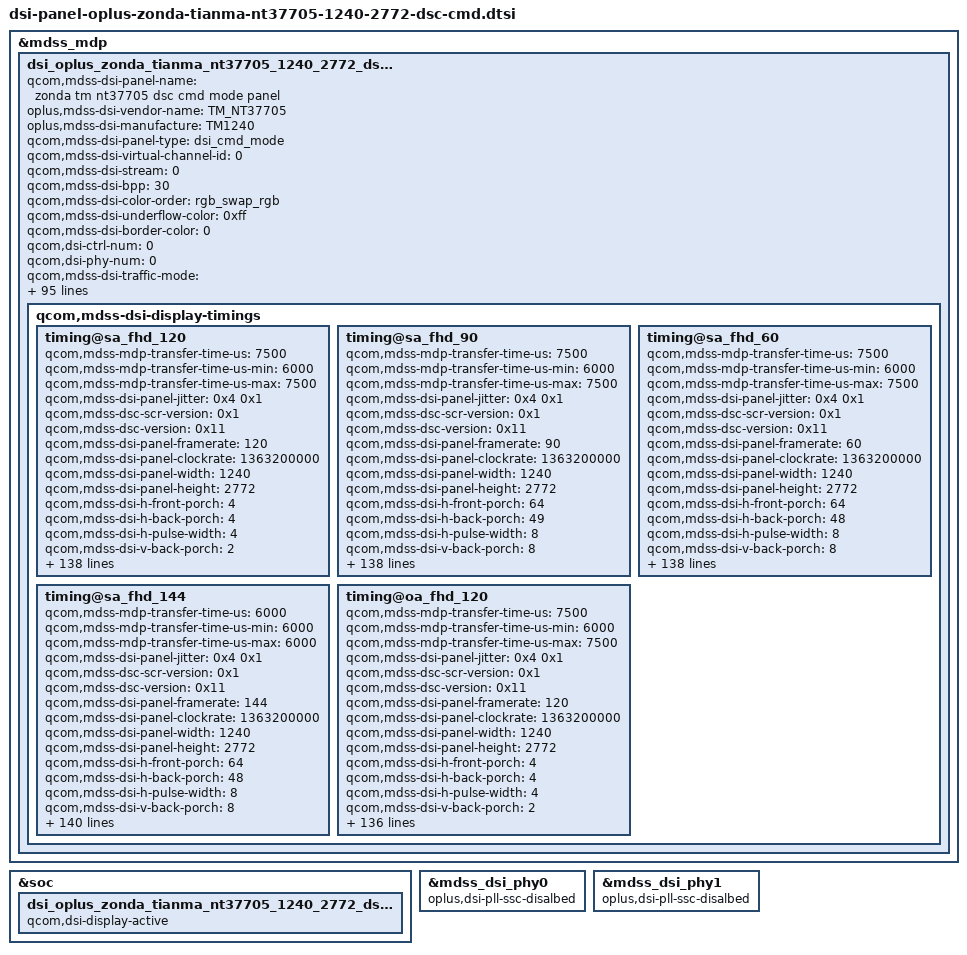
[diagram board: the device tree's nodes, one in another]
&mdss_mdp {
	dsi_oplus_zonda_tianma_nt37705_1240_2772_dsc_cmd: qcom,mdss_dsi_oplus_zonda_tianma_nt37705_1240_2772_dsc_cmd {
		qcom,mdss-dsi-panel-name = "zonda tm nt37705 dsc cmd mode panel";
		oplus,mdss-dsi-vendor-name = "TM_NT37705";
		oplus,mdss-dsi-manufacture = "TM1240";
		qcom,mdss-dsi-panel-type = "dsi_cmd_mode";
		qcom,mdss-dsi-virtual-channel-id = <0>;
		qcom,mdss-dsi-stream = <0>;
		qcom,mdss-dsi-bpp = <30>;
		qcom,mdss-dsi-color-order = "rgb_swap_rgb";
		qcom,mdss-dsi-underflow-color = <0xff>;
		qcom,mdss-dsi-border-color = <0>;
		qcom,dsi-ctrl-num = <0>;
		qcom,dsi-phy-num = <0>;
		qcom,mdss-dsi-traffic-mode = "non_burst_sync_event";
		qcom,mdss-dsi-lane-map = "lane_map_0123";
		qcom,mdss-dsi-bllp-eof-power-mode;
		qcom,mdss-dsi-bllp-power-mode;
		qcom,mdss-dsi-lane-0-state;
		qcom,mdss-dsi-lane-1-state;
		qcom,mdss-dsi-lane-2-state;
		qcom,mdss-dsi-lane-3-state;
		qcom,mdss-dsi-dma-trigger = "trigger_sw";
		qcom,mdss-dsi-mdp-trigger = "none";
		qcom,mdss-dsi-reset-sequence = <1 2>, <0 2>, <1 20>;

		qcom,mdss-dsi-te-pin-select = <1>;
		qcom,mdss-dsi-te-dcs-command = <1>;
		qcom,mdss-dsi-te-check-enable;
		qcom,mdss-dsi-te-using-te-pin;
		qcom,mdss-dsi-lp11-init;
		qcom,mdss-dsi-wr-mem-start = <0x2c>;
		qcom,mdss-dsi-wr-mem-continue = <0x3c>;
		/* HDR Setting */
		qcom,mdss-dsi-panel-hdr-enabled;
		qcom,mdss-dsi-panel-hdr-color-primaries = <15635 16450 34000 16000 13250 34500 7500 3000>;
		qcom,mdss-dsi-panel-peak-brightness = <5400000>;
		qcom,mdss-dsi-panel-blackness-level = <2000>;
		qcom,mdss-pan-physical-width-dimension = <70>;
		qcom,mdss-pan-physical-height-dimension = <156>;

		qcom,esd-check-enabled;
		//oplus,esd-check-flag-enabled;
		qcom,mdss-dsi-panel-status-check-mode = "reg_read";
		qcom,mdss-dsi-panel-status-command = [
				06 01 00 01 05 00 02 0A 00
			];
		qcom,mdss-dsi-panel-status-command-state = "dsi_lp_mode";
		qcom,mdss-dsi-panel-status-value = <0x9C>;
		qcom,mdss-dsi-panel-status-read-length = <1>;

		qcom,dynamic-mode-switch-enabled;
		qcom,dynamic-mode-switch-type = "dynamic-resolution-switch-immediate";
		qcom,mdss-dsi-display-timings {
			timing@sa_fhd_120{
				qcom,mdss-mdp-transfer-time-us = <7500>;
				qcom,mdss-mdp-transfer-time-us-min = <6000>;
				qcom,mdss-mdp-transfer-time-us-max = <7500>;
				qcom,mdss-dsi-panel-jitter = <0x4 0x1>;
				qcom,mdss-dsc-scr-version = <0x1>;
				qcom,mdss-dsc-version = <0x11>;
				qcom,mdss-dsi-panel-framerate = <120>;
				qcom,mdss-dsi-panel-clockrate = <1363200000>;
				qcom,mdss-dsi-panel-width = <1240>;
				qcom,mdss-dsi-panel-height = <2772>;

				qcom,mdss-dsi-h-front-porch = <4>;
				qcom,mdss-dsi-h-back-porch = <4>;
				qcom,mdss-dsi-h-pulse-width = <4>;
				qcom,mdss-dsi-v-back-porch = <2>;
				qcom,mdss-dsi-v-front-porch = <2>;
				qcom,mdss-dsi-v-pulse-width = <2>;
				qcom,mdss-dsi-h-sync-pulse = <0>;

				qcom,mdss-dsi-h-left-border = <0>;
				qcom,mdss-dsi-h-right-border = <0>;
				qcom,mdss-dsi-v-top-border = <0>;
				qcom,mdss-dsi-v-bottom-border = <0>;

				/* Apollo vsync config, need to measure TE signal */
				//oplus,apollo-panel-vsync-width = <13000>;
				//oplus,apollo-panel-vsync-period = <16600>;

				/* standard adfr */
				qcom,mdss-dsi-h-sync-skew = <0>;
				oplus,adfr-min-fps-mapping-table = <120 60>;

				qcom,mdss-dsi-panel-vsync-source = <1>;
				qcom,mdss-dsi-qsync-min-fps-0 = <1314>;
				oplus,fod-on-vblank = <0>;
				oplus,fod-off-vblank = <0>;
				oplus,ofp-need-to-filter-backlight-dim-icon;
				qcom,mdss-dsi-bl-demua1-command = [
					/* 51hex > 0x644 */
					39 00 00 50 00 00 06 F0 55 AA 52 08 04
					39 00 00 50 00 00 02 6F 02
					39 00 00 50 00 00 03 EC 01 03
					39 00 00 50 00 00 02 6F A5
					39 00 00 10 00 00 07 EC 01 01 01 03 03 03
				];
				qcom,mdss-dsi-bl-demua2-command = [
					/* 0x644>51hex>=0x530 */
					39 00 00 50 00 00 06 F0 55 AA 52 08 04
					39 00 00 50 00 00 02 6F 02
					39 00 00 50 00 00 03 EC 03 0B
					39 00 00 50 00 00 02 6F A5
					39 00 00 10 00 00 07 EC 03 03 03 0B 0B 0B
				];
				qcom,mdss-dsi-bl-demua3-command = [
					/* 0x530>51hex>=0x33A */
					39 00 00 50 00 00 06 F0 55 AA 52 08 04
					39 00 00 50 00 00 02 6F 02
					39 00 00 50 00 00 03 EC 10 18
					39 00 00 50 00 00 02 6F A5
					39 00 00 10 00 00 07 EC 10 10 10 18 18 18
				];
				qcom,mdss-dsi-bl-demua4-command = [
					/* 0x339>51hex>=0x25C */
					39 00 00 50 00 00 06 F0 55 AA 52 08 04
					39 00 00 50 00 00 02 6F 02
					39 00 00 50 00 00 03 EC 15 1D
					39 00 00 50 00 00 02 6F A5
					39 00 00 10 00 00 07 EC 15 15 15 1D 1D 1D
				];
				qcom,mdss-dsi-bl-demua5-command = [
					/* 0x25C>51hex>=0x196 */
					39 00 00 50 00 00 06 F0 55 AA 52 08 04
					39 00 00 50 00 00 02 6F 02
					39 00 00 50 00 00 03 EC 15 2D
					39 00 00 50 00 00 02 6F A5
					39 00 00 10 00 00 07 EC 15 15 15 2D 2D 2D
				];
				qcom,mdss-dsi-bl-demua6-command = [
					/* 0x196>51hex>=0x008 */
					39 00 00 50 00 00 06 F0 55 AA 52 08 04
					39 00 00 50 00 00 02 6F 02
					39 00 00 50 00 00 03 EC 15 4D
					39 00 00 50 00 00 02 6F A5
					39 00 00 10 00 00 07 EC 15 15 15 4D 4D 4D
				];
				qcom,mdss-dsi-skipframe-dbv-command = [
					39 00 00 40 00 00 06 F0 55 AA 52 08 01
					39 00 00 40 00 00 02 6F 02
					39 00 00 40 00 00 11 E5 00 00 00 00 00 00 00 00 00 00 00 00 00 00 00 00
					39 00 00 40 00 00 02 6F 24
					39 00 00 40 00 00 0D E5 00 00 00 00 00 00 00 00 00 00 00 00
					39 00 00 40 00 00 02 6F 46
					39 00 00 40 00 00 0D E5 00 00 00 00 00 00 00 00 00 00 00 00
					39 00 00 40 00 00 02 6F 03
					39 00 00 40 00 00 19 C6 1B 1B 24 23 23 23 23 23 23 1D 1D 25 23 23 23 23 23 23 1B 1B 24 23 23 23
					39 00 00 40 00 00 02 E5 B2
					39 00 00 40 00 00 02 6F 22
					39 00 00 40 00 00 02 E5 B2
					39 00 00 40 00 00 02 6F 44
					39 00 00 40 00 00 02 E5 B2
					39 00 00 40 00 00 06 F0 55 AA 52 08 05
					39 00 00 40 00 00 02 6F 12
					39 00 00 00 00 00 05 EC 00 00 00 00
					];
				qcom,mdss-dsi-timing-switch-command = [
					/* switch */
					39 00 00 40 00 00 06 F0 55 AA 52 08 00
					39 00 00 00 0C 00 02 2F 00
					39 00 00 40 00 00 02 BE 47
					39 00 00 40 00 00 02 6F A8
					39 00 00 40 00 00 03 BA 00 00
					39 00 00 40 00 00 02 6F B0
					39 00 00 40 00 00 05 BA 00 00 00 00
					39 00 00 40 00 00 02 2F 30
					39 00 00 40 00 00 02 6D 00
					39 00 00 00 00 00 05 35 00 00 00 00
					];
				qcom,mdss-dsi-on-command=[
					/* Optimize edge green */
					39 00 00 40 00 00 06 F0 55 AA 52 08 07
					39 00 00 40 00 00 0E B4 C0 80 80 80 80 50 80 80 80 80 80 50 80
					/* Vsync Hsync output */
					39 00 00 40 00 00 06 F0 55 AA 52 08 00
					39 00 00 40 00 00 02 6F 02
					39 00 00 00 00 00 03 BE 49 4C
					/* AVDD=7.9 */
					39 00 00 40 00 00 06 F0 55 AA 52 08 00
					39 00 00 40 00 00 02 6F 07
					39 00 00 40 00 00 02 B5 4E
					/* HBM L0 glows green */
					39 00 00 40 00 00 02 B5 80
					39 00 00 40 00 00 02 6F 2C
					39 00 00 00 00 00 02 B5 03
					39 00 00 40 00 00 05 FF AA 55 A5 81
					39 00 00 40 00 00 02 6F 19
					39 00 00 40 00 00 02 FB 00
					39 00 00 40 00 00 02 6F 05
					39 00 00 40 00 00 02 FE 34
					39 00 00 40 00 00 05 FF AA 55 A5 80
					39 00 00 40 00 00 02 6F 1A
					39 00 00 40 00 00 02 F4 55
					39 00 00 40 00 00 05 FF AA 55 A5 83
					39 00 00 40 00 00 02 6F 12
					39 00 00 40 00 00 02 FE 41
					39 00 00 40 00 00 02 5F 00
					39 00 00 40 00 00 02 26 00
					39 00 00 40 00 00 02 26 00
					39 00 00 40 00 00 02 17 10
					39 00 00 40 00 00 05 2A 00 00 04 D7
					39 00 00 00 00 00 05 2B 00 00 0A D3
					/* Fre 120Hz */
					39 00 00 00 00 00 02 2F 00
					/* TE ON */
					39 00 00 40 00 00 02 35 00
					39 00 00 00 00 00 03 44 00 00
					/* Nor 51 */
					39 00 00 40 00 00 03 51 00 00
					39 00 00 00 00 00 02 6F 04
					/* AOD 51 */
					39 00 00 40 00 00 03 51 00 00
					39 00 00 40 00 00 02 53 20
					39 00 00 00 00 00 03 90 03 03
					/* 10bit DSC */
					39 00 00 40 00 00 13 91 AB 28 00 0C F2 00 02 85 01 0F 00 08 0A E9 07 5F 10 F0
					39 00 00 40 00 00 05 FF AA 55 A5 81
					39 00 00 40 00 00 02 6F 24
					39 00 00 40 00 00 15 FB 00 03 04 55 77 77 77 99 9D 00 00 06 88 9A BB BC DE EF F0 11
					39 00 00 40 00 00 05 FF AA 55 A5 81
					39 00 00 40 00 00 02 6F 0E
					39 00 00 40 00 00 02 F5 00
					39 00 00 40 00 00 05 FF AA 55 A5 80
					39 00 00 40 00 00 02 6F 0F
					39 00 00 40 00 00 02 FC 00
					39 00 00 40 00 00 02 6F 09
					39 00 00 40 00 00 03 FC FC F0
					39 00 00 40 00 00 05 FF AA 55 A5 80
					39 00 00 40 00 00 02 6F 0A
					39 00 00 40 00 00 04 F6 70 70 70
					39 00 00 40 00 00 02 6F 0E
					39 00 00 00 00 00 02 F6 60
					/* OSC start */
					39 00 00 40 00 00 05 FF AA 55 A5 80
					39 00 00 40 00 00 02 6F 11
					/* OSC2 145Mhz */
					39 00 00 40 00 00 03 F8 01 8E
					39 00 00 40 00 00 02 6F 2D
					/* OSC1 121.9Mhz */
					39 00 00 40 00 00 03 F8 00 FC
					39 00 00 40 00 00 02 6F 01
					39 00 00 40 00 00 02 1F 06
					39 00 00 40 00 00 05 FF AA 55 A5 81
					39 00 00 40 00 00 02 6F 1E
					39 00 00 00 00 00 02 FB 0F
					/* OSC end */
					39 00 00 40 00 00 05 FF AA 55 A5 83
					39 00 00 40 00 00 02 6F 12
					39 00 00 40 00 00 02 FE 41
					39 00 00 40 00 00 05 FF AA 55 A5 80
					39 00 00 40 00 00 02 6F 19
					39 00 00 40 00 00 02 F2 00
					39 00 00 40 00 00 05 FF AA 55 A5 81
					39 00 00 40 00 00 02 6F 02
					39 00 00 40 00 00 02 F9 04
					39 00 00 40 00 00 02 5A 00
					/* AOD remove black frame */
					39 00 00 00 00 00 06 F0 55 AA 52 08 01
					39 00 00 00 00 00 06 D2 00 00 00 00 15
					15 00 00 00 00 00 02 6F 05
					39 00 00 00 00 00 04 D2 01 00 00
					15 00 00 00 00 00 02 6F 0E
					39 00 00 00 00 00 06 D2 02 00 10 05 88
					39 00 00 00 00 00 0B E4 80 00 00 00 00 00 00 00 00 33
					15 00 00 00 00 00 02 6F 0A
					39 00 00 00 00 00 07 E4 80 00 00 10 00 53
					/* AOD off splash */
					39 00 00 40 00 00 06 F0 55 AA 52 08 01
					39 00 00 40 00 00 02 6F 0E
					39 00 00 00 00 00 06 D2 02 00 10 05 82
					/* OSC Tracking */
					39 00 00 40 00 00 06 F0 55 AA 52 08 01
					39 00 00 00 00 00 2A C3 DD 06 22 15 F9 00 06 20 15 FF 00 03 E7 16 06 2B 1D 03 E7 16 06 2B 1D 03 E7 16 06 2B 1D 03 E7 16 06 2B 1D 03 E7 16 06 2B 1D
					/* 11H sleep out */
					39 00 00 00 78 00 02 11 00
					39 00 00 40 00 00 06 F0 55 AA 52 08 00
					39 00 00 00 09 00 02 2F 00
					39 00 00 40 00 00 02 BE 47
					39 00 00 40 00 00 02 6F A8
					39 00 00 40 00 00 03 BA 00 00
					39 00 00 40 00 00 02 6F B0
					39 00 00 40 00 00 05 BA 00 00 00 00
					39 00 00 40 00 00 02 2F 30
					39 00 00 40 00 00 02 6D 00
					39 00 00 00 00 00 05 35 00 00 00 00
					05 00 00 00 00 00 01 29
				];

				qcom,mdss-dsi-panel-info-switch-page-command = [
					/*read panel info switch page 01*/
					39 00 00 00 00 00 06 F0 55 AA 52 08 01
				];
				qcom,mdss-dsi-default-switch-page-command = [
					/*switch default page*/
					39 00 00 00 00 00 06 F0 55 AA 52 08 00
				];

				qcom,mdss-dsi-adfr-auto-on-command = [
					/* SDC Auto On */
				];
				qcom,mdss-dsi-adfr-auto-off-command = [
					/* SDC Auto Off */
				];
				qcom,mdss-dsi-adfr-min-fps-0-command = [
					15 00 00 40 00 00 02 2F 00
					15 00 00 40 00 00 02 2F 30
					15 00 00 00 00 00 02 6D 00
				];
				qcom,mdss-dsi-adfr-min-fps-1-command = [
					15 00 00 40 00 00 02 2F 00
					15 00 00 40 00 00 02 2F 30
					15 00 00 00 00 00 02 6D 01
				];

				qcom,mdss-dsi-post-on-backlight = [
					/* Display On */
					05 00 00 00 00 00 01 29
				];
				qcom,mdss-dsi-off-command=[
					05 00 00 00 0A 00 01 28
					05 00 00 00 78 00 01 10
				];
				qcom,mdss-dsi-lp1-command = [
					/* AOD Mode ON Setting */
					39 00 00 00 00 00 06 F0 55 AA 52 08 00
					15 00 00 00 00 00 02 6F 0C
					39 00 00 00 00 00 03 B5 50 4B
					39 00 00 00 00 00 05 35 00 00 00 00
					39 00 00 00 00 00 03 44 00 00
					15 00 00 00 10 00 02 2F 00
					05 00 00 00 00 00 01 39
					15 00 00 00 00 00 02 65 01
					15 00 00 00 00 00 02 6F 04
					39 00 00 00 00 00 03 51 02 FF
				];
				qcom,mdss-dsi-nolp-command = [
					/* AOD OFF */
					39 00 00 00 00 00 06 F0 55 AA 52 08 00
					15 00 00 00 00 00 02 6F 0C
					39 00 00 00 00 00 03 B5 4F 4B
					15 00 00 00 00 00 02 65 00
					05 00 00 00 00 00 01 38
					15 00 00 00 00 00 02 2F 30
					15 00 00 00 00 00 02 6D 00
					39 00 00 00 00 00 05 35 00 00 00 00
					39 00 00 00 00 00 03 44 00 00
					39 00 00 00 28 00 03 51 00 00
				];
				qcom,mdss-dsi-hbm-off-command = [
					//39 00 00 00 00 00 03 51 0D BB
				];
				qcom,mdss-dsi-hbm-on-command = [
					39 00 00 40 00 00 06 F0 55 AA 52 08 01
					39 00 00 40 00 00 02 6F 02
					39 00 00 40 00 00 11 E5 00 00 00 00 20 20 20 00 28 28 28 00 30 30 30 00
					39 00 00 40 00 00 02 6F 24
					39 00 00 40 00 00 0D E5 00 00 00 00 20 20 20 00 28 28 28 00
					39 00 00 40 00 00 02 6F 46
					39 00 00 40 00 00 0D E5 00 00 00 00 20 20 20 00 28 28 28 00
					39 00 00 40 00 00 02 6F 03
					39 00 00 40 00 00 19 C6 37 37 37 23 23 23 23 23 23 37 37 37 23 23 23 23 23 23 37 37 37 23 23 23
					39 00 00 40 00 00 02 E5 B2
					39 00 00 40 00 00 02 6F 22
					39 00 00 40 00 00 02 E5 B2
					39 00 00 40 00 00 02 6F 44
					39 00 00 40 00 00 02 E5 B2
					39 00 00 40 00 00 06 F0 55 AA 52 08 05
					39 00 00 40 00 00 02 6F 12
					39 00 00 40 00 00 05 EC 00 00 00 00
					39 00 00 40 00 00 06 F0 55 AA 52 08 00
					39 00 00 40 00 00 02 6F 11
					39 00 00 40 00 00 04 B2 02 03 42
					39 00 00 40 00 00 2D B3 00 08 00 B4 00 B4 01 5F 01 5F 02 20 02 20 03 7C 03 7C 05 30 05 30 06 43 06 43 06 44 06 44 09 0B 09 0B 0D BB 0D BB 0F FF 0F FF 0F FF
					39 00 00 40 00 00 2F B4 00 00 00 80 00 96 00 96 00 C0 00 C0 01 26 01 26 02 8E 02 8E 05 8E 05 8E 08 26 08 26 09 40 09 40 09 40 09 40 09 40 09 40 09 40 09 40 09 40
					39 00 00 40 00 00 02 6F 2E
					39 00 00 40 00 00 2F B4 00 00 00 E2 00 FF 00 FF 01 3A 01 3A 01 CE 01 CE 03 AA 03 AA 07 9C 07 9C 0B 20 0B 20 0C 56 0C 56 0C 56 0C 56 0C 56 0C 56 0C 56 0C 56 0C 56
					39 00 00 40 00 00 02 6F 5C
					39 00 00 40 00 00 2F B4 00 00 00 78 00 8C 00 8C 00 B4 00 B4 01 26 01 26 02 8E 02 8E 05 8E 05 8E 08 26 08 26 09 40 09 40 09 40 09 40 09 40 09 40 09 40 09 40 09 40
					39 00 00 00 00 00 03 51 0F 00
				];
				qcom,mdss-dsi-hbm-on-onepulse-command = [
					39 00 00 40 00 00 06 F0 55 AA 52 08 01
					39 00 00 40 00 00 02 6F 02
					39 00 00 40 00 00 11 E5 00 00 00 00 00 00 00 00 00 00 00 00 00 00 00 00
					39 00 00 40 00 00 02 6F 24
					39 00 00 40 00 00 0D E5 00 00 00 00 20 20 20 00 28 28 28 00
					39 00 00 40 00 00 02 6F 46
					39 00 00 40 00 00 0D E5 00 00 00 00 20 20 20 00 28 28 28 00
					39 00 00 40 00 00 02 6F 03
					39 00 00 40 00 00 19 C6 1D 1D 1D 23 23 23 23 23 23 37 37 37 23 23 23 23 23 23 37 37 37 23 23 23
					39 00 00 40 00 00 02 E5 B2
					39 00 00 40 00 00 02 6F 22
					39 00 00 40 00 00 02 E5 B2
					39 00 00 40 00 00 02 6F 44
					39 00 00 40 00 00 02 E5 B2
					39 00 00 40 00 00 06 F0 55 AA 52 08 05
					39 00 00 40 00 00 02 6F 12
					39 00 00 40 00 00 05 EC 00 00 00 00
					39 00 00 40 00 00 06 F0 55 AA 52 08 00
					39 00 00 40 00 00 02 6F 11
					39 00 00 40 00 00 04 B2 00 00 40
					39 00 00 40 00 00 2D B3 00 08 00 B4 00 B4 01 5F 01 5F 02 20 02 20 03 7C 03 7C 05 30 05 30 06 43 06 43 06 44 06 44 09 0B 09 0B 0D BB 0D BB 0F FF 0F FF 0F FF
					39 00 00 40 00 00 2F B4 00 00 00 80 00 96 00 96 00 C0 00 C0 01 26 01 26 02 8E 02 8E 05 8E 05 8E 08 26 08 26 0A DE 0A DE 0A DE 0A DE 0A DE 0A DE 0A DE 0A DE 0A DE
					39 00 00 40 00 00 02 6F 2E
					39 00 00 40 00 00 2F B4 00 00 00 E2 00 FF 00 FF 01 3A 01 3A 01 CE 01 CE 03 AA 03 AA 07 9C 07 9C 0B 20 0B 20 0E 5B 0E 5B 0E 5B 0E 5B 0E 5B 0E 5B 0E 5B 0E 5B 0E 5B
					39 00 00 40 00 00 02 6F 5C
					39 00 00 40 00 00 2F B4 00 00 00 78 00 8C 00 8C 00 B4 00 B4 01 26 01 26 02 8E 02 8E 05 8E 05 8E 08 26 08 26 0A DE 0A DE 0A DE 0A DE 0A DE 0A DE 0A DE 0A DE 0A DE
					39 00 00 00 00 00 03 51 0F 00
				];
				qcom,mdss-dsi-aod-high-mode-command = [
					/* AOD 50nit */
					15 00 00 40 00 00 02 6F 04
					39 00 00 00 00 00 03 51 02 FF
				];
				qcom,mdss-dsi-aod-low-mode-command = [
					/* AOD 10nit */
					15 00 00 40 00 00 02 6F 04
					39 00 00 00 00 00 03 51 01 FF
				];
				qcom,mdss-dsi-temperature-compensation-command = [
					39 00 00 40 00 00 06 F0 55 AA 52 08 01
					39 00 00 40 00 00 02 6F 06
					39 00 00 40 00 00 05 E5 00 00 00 00
					39 00 00 40 00 00 02 6F 0A
					39 00 00 40 00 00 05 E5 00 00 00 00
					39 00 00 40 00 00 02 6F 0E
					39 00 00 40 00 00 05 E5 00 00 00 00
					39 00 00 40 00 00 02 6F 28
					39 00 00 40 00 00 05 E5 00 00 00 00
					39 00 00 40 00 00 02 6F 2C
					39 00 00 40 00 00 05 E5 00 00 00 00
					39 00 00 40 00 00 02 6F 4A
					39 00 00 40 00 00 05 E5 00 00 00 00
					39 00 00 40 00 00 02 6F 4E
					39 00 00 40 00 00 05 E5 00 00 00 00
					39 00 00 40 00 00 02 6F 52
					39 00 00 40 00 00 05 E5 00 00 00 00
					39 00 00 40 00 00 02 6F 03
					39 00 00 40 00 00 04 C6 00 00 00
					39 00 00 40 00 00 02 6F 0C
					39 00 00 40 00 00 04 C6 00 00 00
					39 00 00 40 00 00 02 6F 15
					39 00 00 40 00 00 04 C6 00 00 00
					39 00 00 40 00 00 06 F0 55 AA 52 08 05
					39 00 00 40 00 00 02 6F 12
					39 00 00 00 00 00 05 EC 00 00 00 00
				];
				/* origin 3 pulse */
				qcom,mdss-dsi-pwm-switch-high-command = [
					39 00 00 40 00 00 06 F0 55 AA 52 08 00
					39 00 00 40 00 00 02 6F 11
					39 00 00 40 00 00 04 B2 02 03 42
					39 00 00 40 00 00 2D B3 00 08 00 B4 00 B4 01 5F 01 5F 02 20 02 20 03 7C 03 7C 05 30 05 30 06 43 06 43 06 44 06 44 09 0B 09 0B 0D BB 0D BB 0F FF 0F FF 0F FF
					39 00 00 40 00 00 2F B4 00 00 00 80 00 96 00 96 00 C0 00 C0 01 26 01 26 02 8E 02 8E 05 8E 05 8E 08 26 08 26 09 40 09 40 09 40 09 40 09 40 09 40 09 40 09 40 09 40
					39 00 00 40 00 00 02 6F 2E
					39 00 00 40 00 00 2F B4 00 00 00 E2 00 FF 00 FF 01 3A 01 3A 01 CE 01 CE 03 AA 03 AA 07 9C 07 9C 0B 20 0B 20 0C 56 0C 56 0C 56 0C 56 0C 56 0C 56 0C 56 0C 56 0C 56
					39 00 00 40 00 00 02 6F 5C
					39 00 00 40 00 00 2F B4 00 00 00 78 00 8C 00 8C 00 B4 00 B4 01 26 01 26 02 8E 02 8E 05 8E 05 8E 08 26 08 26 09 40 09 40 09 40 09 40 09 40 09 40 09 40 09 40 09 40
					39 00 00 00 00 00 03 51 06 44
				];
				qcom,mdss-dsi-pwm-switch-low-command = [
					39 00 00 40 00 00 06 F0 55 AA 52 08 00
					39 00 00 40 00 00 02 6F 11
					39 00 00 40 00 00 04 B2 0F 17 4E
					39 00 00 40 00 00 2D B3 00 08 00 B4 00 B4 01 5F 01 5F 02 20 02 20 03 7C 03 7C 05 30 05 30 06 43 06 43 06 44 06 44 09 0B 09 0B 0D BB 0D BB 0F FF 0F FF 0F FF
					39 00 00 40 00 00 2F B4 00 00 00 80 00 96 00 96 00 C0 00 C0 01 26 01 26 02 8E 02 8E 05 8E 05 8E 08 26 08 26 09 40 09 40 09 40 09 40 09 40 09 40 09 40 09 40 09 40
					39 00 00 40 00 00 02 6F 2E
					39 00 00 40 00 00 2F B4 00 00 00 E2 00 FF 00 FF 01 3A 01 3A 01 CE 01 CE 03 AA 03 AA 07 9C 07 9C 0B 20 0B 20 0C 56 0C 56 0C 56 0C 56 0C 56 0C 56 0C 56 0C 56 0C 56
					39 00 00 40 00 00 02 6F 5C
					39 00 00 40 00 00 2F B4 00 00 00 78 00 8C 00 8C 00 B4 00 B4 01 26 01 26 02 8E 02 8E 05 8E 05 8E 08 26 08 26 09 40 09 40 09 40 09 40 09 40 09 40 09 40 09 40 09 40
					39 00 00 00 00 00 03 51 06 43
				];
				/* origin 3 pulse */
				qcom,mdss-dsi-timming-pwm-switch-high-command = [
					39 00 00 40 00 00 06 F0 55 AA 52 08 00
					39 00 00 40 00 00 02 6F 11
					39 00 00 40 00 00 04 B2 02 03 42
					39 00 00 40 00 00 2D B3 00 08 00 B4 00 B4 01 5F 01 5F 02 20 02 20 03 7C 03 7C 05 30 05 30 06 43 06 43 06 44 06 44 09 0B 09 0B 0D BB 0D BB 0F FF 0F FF 0F FF
					39 00 00 40 00 00 2F B4 00 00 00 80 00 96 00 96 00 C0 00 C0 01 26 01 26 02 8E 02 8E 05 8E 05 8E 08 26 08 26 09 40 09 40 09 40 09 40 09 40 09 40 09 40 09 40 09 40
					39 00 00 40 00 00 02 6F 2E
					39 00 00 40 00 00 2F B4 00 00 00 E2 00 FF 00 FF 01 3A 01 3A 01 CE 01 CE 03 AA 03 AA 07 9C 07 9C 0B 20 0B 20 0C 56 0C 56 0C 56 0C 56 0C 56 0C 56 0C 56 0C 56 0C 56
					39 00 00 40 00 00 02 6F 5C
					39 00 00 00 00 00 2F B4 00 00 00 78 00 8C 00 8C 00 B4 00 B4 01 26 01 26 02 8E 02 8E 05 8E 05 8E 08 26 08 26 09 40 09 40 09 40 09 40 09 40 09 40 09 40 09 40 09 40
				];
				qcom,mdss-dsi-timming-pwm-switch-low-command = [
					39 00 00 40 00 00 06 F0 55 AA 52 08 00
					39 00 00 40 00 00 02 6F 11
					39 00 00 40 00 00 04 B2 0F 17 4E
					39 00 00 40 00 00 2D B3 00 08 00 B4 00 B4 01 5F 01 5F 02 20 02 20 03 7C 03 7C 05 30 05 30 06 43 06 43 06 44 06 44 09 0B 09 0B 0D BB 0D BB 0F FF 0F FF 0F FF
					39 00 00 40 00 00 2F B4 00 00 00 80 00 96 00 96 00 C0 00 C0 01 26 01 26 02 8E 02 8E 05 8E 05 8E 08 26 08 26 09 40 09 40 09 40 09 40 09 40 09 40 09 40 09 40 09 40
					39 00 00 40 00 00 02 6F 2E
					39 00 00 40 00 00 2F B4 00 00 00 E2 00 FF 00 FF 01 3A 01 3A 01 CE 01 CE 03 AA 03 AA 07 9C 07 9C 0B 20 0B 20 0C 56 0C 56 0C 56 0C 56 0C 56 0C 56 0C 56 0C 56 0C 56
					39 00 00 40 00 00 02 6F 5C
					39 00 00 00 00 00 2F B4 00 00 00 78 00 8C 00 8C 00 B4 00 B4 01 26 01 26 02 8E 02 8E 05 8E 05 8E 08 26 08 26 09 40 09 40 09 40 09 40 09 40 09 40 09 40 09 40 09 40
				];
				qcom,mdss-dsi-pwm-switch-onepulse-command = [
					39 00 00 40 00 00 06 F0 55 AA 52 08 00
					39 00 00 40 00 00 02 6F 11
					39 00 00 40 00 00 04 B2 00 00 40
					39 00 00 40 00 00 2D B3 00 08 00 B4 00 B4 01 5F 01 5F 02 20 02 20 03 7C 03 7C 05 30 05 30 06 43 06 43 06 44 06 44 09 0B 09 0B 0D BB 0D BB 0F FF 0F FF 0F FF
					39 00 00 40 00 00 2F B4 00 00 00 80 00 96 00 96 00 C0 00 C0 01 26 01 26 02 8E 02 8E 05 8E 05 8E 08 26 08 26 0A DE 0A DE 0A DE 0A DE 0A DE 0A DE 0A DE 0A DE 0A DE
					39 00 00 40 00 00 02 6F 2E
					39 00 00 40 00 00 2F B4 00 00 00 E2 00 FF 00 FF 01 3A 01 3A 01 CE 01 CE 03 AA 03 AA 07 9C 07 9C 0B 20 0B 20 0E 5B 0E 5B 0E 5B 0E 5B 0E 5B 0E 5B 0E 5B 0E 5B 0E 5B
					39 00 00 40 00 00 02 6F 5C
					39 00 00 40 00 00 2F B4 00 00 00 78 00 8C 00 8C 00 B4 00 B4 01 26 01 26 02 8E 02 8E 05 8E 05 8E 08 26 08 26 0A DE 0A DE 0A DE 0A DE 0A DE 0A DE 0A DE 0A DE 0A DE
					39 00 00 00 00 00 03 51 06 44
				];
				qcom,mdss-dsi-timming-pwm-switch-onepulse-command = [
					39 00 00 40 00 00 06 F0 55 AA 52 08 00
					39 00 00 40 00 00 02 6F 11
					39 00 00 40 00 00 04 B2 00 00 40
					39 00 00 40 00 00 2D B3 00 08 00 B4 00 B4 01 5F 01 5F 02 20 02 20 03 7C 03 7C 05 30 05 30 06 43 06 43 06 44 06 44 09 0B 09 0B 0D BB 0D BB 0F FF 0F FF 0F FF
					39 00 00 40 00 00 2F B4 00 00 00 80 00 96 00 96 00 C0 00 C0 01 26 01 26 02 8E 02 8E 05 8E 05 8E 08 26 08 26 0A DE 0A DE 0A DE 0A DE 0A DE 0A DE 0A DE 0A DE 0A DE
					39 00 00 40 00 00 02 6F 2E
					39 00 00 40 00 00 2F B4 00 00 00 E2 00 FF 00 FF 01 3A 01 3A 01 CE 01 CE 03 AA 03 AA 07 9C 07 9C 0B 20 0B 20 0E 5B 0E 5B 0E 5B 0E 5B 0E 5B 0E 5B 0E 5B 0E 5B 0E 5B
					39 00 00 40 00 00 02 6F 5C
					39 00 00 00 00 00 2F B4 00 00 00 78 00 8C 00 8C 00 B4 00 B4 01 26 01 26 02 8E 02 8E 05 8E 05 8E 08 26 08 26 0A DE 0A DE 0A DE 0A DE 0A DE 0A DE 0A DE 0A DE 0A DE
				];
				qcom,mdss-dsi-pwm-switch-threepulse-command = [
					39 00 00 40 00 00 06 F0 55 AA 52 08 00
					39 00 00 40 00 00 02 6F 11
					39 00 00 40 00 00 04 B2 02 03 42
					39 00 00 40 00 00 2D B3 00 08 00 B4 00 B4 01 5F 01 5F 02 20 02 20 03 7C 03 7C 05 30 05 30 06 43 06 43 06 44 06 44 09 0B 09 0B 0D BB 0D BB 0F FF 0F FF 0F FF
					39 00 00 40 00 00 2F B4 00 00 00 80 00 96 00 96 00 C0 00 C0 01 26 01 26 02 8E 02 8E 05 8E 05 8E 08 26 08 26 09 40 09 40 09 40 09 40 09 40 09 40 09 40 09 40 09 40
					39 00 00 40 00 00 02 6F 2E
					39 00 00 40 00 00 2F B4 00 00 00 E2 00 FF 00 FF 01 3A 01 3A 01 CE 01 CE 03 AA 03 AA 07 9C 07 9C 0B 20 0B 20 0C 56 0C 56 0C 56 0C 56 0C 56 0C 56 0C 56 0C 56 0C 56
					39 00 00 40 00 00 02 6F 5C
					39 00 00 00 00 00 2F B4 00 00 00 78 00 8C 00 8C 00 B4 00 B4 01 26 01 26 02 8E 02 8E 05 8E 05 8E 08 26 08 26 09 40 09 40 09 40 09 40 09 40 09 40 09 40 09 40 09 40
				];

				qcom,mdss-dsi-timing-switch-command-state = "dsi_hs_mode";
				qcom,mdss-dsi-on-command-state = "dsi_lp_mode";
				qcom,mdss-dsi-off-command-state = "dsi_hs_mode";
				qcom,mdss-dsi-hbm-on-command-state = "dsi_lp_mode";
				qcom,mdss-dsi-hbm-on-onepulse-command-state = "dsi_lp_mode";
				qcom,mdss-dsi-hbm-off-command-state = "dsi_lp_mode";
				qcom,mdss-dsi-skipframe-dbv-command-state = "dsi_hs_mode";
				qcom,mdss-dsi-adfr-auto-on-command-state ="dsi_hs_mode";
				qcom,mdss-dsi-adfr-auto-off-command-state ="dsi_hs_mode";
				qcom,mdss-dsi-adfr-min-fps-0-command-state = "dsi_hs_mode";
				qcom,mdss-dsi-adfr-min-fps-1-command-state = "dsi_hs_mode";
				qcom,mdss-dsi-bl-demua1-command-state = "dsi_hs_mode";
				qcom,mdss-dsi-bl-demua2-command-state = "dsi_hs_mode";
				qcom,mdss-dsi-bl-demua3-command-state = "dsi_hs_mode";
				qcom,mdss-dsi-bl-demua4-command-state = "dsi_hs_mode";
				qcom,mdss-dsi-bl-demua5-command-state = "dsi_hs_mode";
				qcom,mdss-dsi-bl-demua6-command-state = "dsi_hs_mode";
				qcom,mdss-dsi-panel-info-switch-page-command-state = "dsi_lp_mode";
				qcom,mdss-dsi-default-switch-page-command-state = "dsi_lp_mode";

				qcom,mdss-dsi-pwm-switch-high-command-state = "dsi_hs_mode";
				qcom,mdss-dsi-pwm-switch-low-command-state = "dsi_hs_mode";
				qcom,mdss-dsi-timming-pwm-switch-high-command-state = "dsi_hs_mode";
				qcom,mdss-dsi-timming-pwm-switch-low-command-state = "dsi_hs_mode";
				qcom,mdss-dsi-pwm-switch-onepulse-command-state = "dsi_hs_mode";
				qcom,mdss-dsi-timming-pwm-switch-onepulse-command-state = "dsi_hs_mode";
				qcom,mdss-dsi-pwm-switch-threepulse-command-state = "dsi_hs_mode";
				qcom,lm-split = <620 620>;
				qcom,compression-mode = "dsc";
				qcom,mdss-dsc-encoders = <2>;
				qcom,mdss-dsc-slice-height = <12>;
				qcom,mdss-dsc-slice-width = <620>;
				qcom,mdss-dsc-slice-per-pkt = <2>;
				qcom,mdss-dsc-bit-per-component = <10>;
				qcom,mdss-dsc-bit-per-pixel = <8>;
				qcom,mdss-dsc-block-prediction-enable;
			};
			timing@sa_fhd_90{
				qcom,mdss-mdp-transfer-time-us = <7500>;
				qcom,mdss-mdp-transfer-time-us-min = <6000>;
				qcom,mdss-mdp-transfer-time-us-max = <7500>;
				qcom,mdss-dsi-panel-jitter = <0x4 0x1>;
				qcom,mdss-dsc-scr-version = <0x1>;
				qcom,mdss-dsc-version = <0x11>;
				qcom,mdss-dsi-panel-framerate = <90>;
				qcom,mdss-dsi-panel-clockrate = <1363200000>;
				qcom,mdss-dsi-panel-width = <1240>;
				qcom,mdss-dsi-panel-height = <2772>;

				qcom,mdss-dsi-h-front-porch = <64>;
				qcom,mdss-dsi-h-back-porch = <49>;
				qcom,mdss-dsi-h-pulse-width = <8>;
				qcom,mdss-dsi-v-back-porch = <8>;
				qcom,mdss-dsi-v-front-porch = <2>;
				qcom,mdss-dsi-v-pulse-width = <2>;
				qcom,mdss-dsi-h-sync-pulse = <0>;

				qcom,mdss-dsi-h-left-border = <0>;
				qcom,mdss-dsi-h-right-border = <0>;
				qcom,mdss-dsi-v-top-border = <0>;
				qcom,mdss-dsi-v-bottom-border = <0>;

				/* Apollo vsync config, need to measure TE signal */
				//oplus,apollo-panel-vsync-width = <13000>;
				//oplus,apollo-panel-vsync-period = <16600>;

				/* standard adfr */
				qcom,mdss-dsi-h-sync-skew = <0>;
				oplus,adfr-min-fps-mapping-table = <90 45>;

				qcom,mdss-dsi-panel-vsync-source = <1>;
				qcom,mdss-dsi-qsync-min-fps-0 = <1314>;
				oplus,fod-on-vblank = <0>;
				oplus,fod-off-vblank = <0>;
				oplus,ofp-need-to-filter-backlight-dim-icon;
				qcom,mdss-dsi-bl-demua1-command = [
					/* 51hex > 0x644 */
					39 00 00 50 00 00 06 F0 55 AA 52 08 04
					39 00 00 50 00 00 02 6F 02
					39 00 00 50 00 00 03 EC 01 03
					39 00 00 50 00 00 02 6F A5
					39 00 00 10 00 00 07 EC 01 01 01 03 03 03
				];
				qcom,mdss-dsi-bl-demua2-command = [
					/* 0x644>51hex>=0x530 */
					39 00 00 50 00 00 06 F0 55 AA 52 08 04
					39 00 00 50 00 00 02 6F 02
					39 00 00 50 00 00 03 EC 03 0B
					39 00 00 50 00 00 02 6F A5
					39 00 00 10 00 00 07 EC 03 03 03 0B 0B 0B
				];
				qcom,mdss-dsi-bl-demua3-command = [
					/* 0x530>51hex>=0x33A */
					39 00 00 50 00 00 06 F0 55 AA 52 08 04
					39 00 00 50 00 00 02 6F 02
					39 00 00 50 00 00 03 EC 10 18
					39 00 00 50 00 00 02 6F A5
					39 00 00 10 00 00 07 EC 10 10 10 18 18 18
				];
				qcom,mdss-dsi-bl-demua4-command = [
					/* 0x339>51hex>=0x25C */
					39 00 00 50 00 00 06 F0 55 AA 52 08 04
					39 00 00 50 00 00 02 6F 02
					39 00 00 50 00 00 03 EC 15 1D
					39 00 00 50 00 00 02 6F A5
					39 00 00 10 00 00 07 EC 15 15 15 1D 1D 1D
				];
				qcom,mdss-dsi-bl-demua5-command = [
					/* 0x25C>51hex>=0x196 */
					39 00 00 50 00 00 06 F0 55 AA 52 08 04
					39 00 00 50 00 00 02 6F 02
					39 00 00 50 00 00 03 EC 15 2D
					39 00 00 50 00 00 02 6F A5
					39 00 00 10 00 00 07 EC 15 15 15 2D 2D 2D
				];
				qcom,mdss-dsi-bl-demua6-command = [
					/* 0x196>51hex>=0x008 */
					39 00 00 50 00 00 06 F0 55 AA 52 08 04
					39 00 00 50 00 00 02 6F 02
					39 00 00 50 00 00 03 EC 15 4D
					39 00 00 50 00 00 02 6F A5
					39 00 00 10 00 00 07 EC 15 15 15 4D 4D 4D
				];
				qcom,mdss-dsi-skipframe-dbv-command = [
					39 00 00 40 00 00 06 F0 55 AA 52 08 01
					39 00 00 40 00 00 02 6F 02
					39 00 00 40 00 00 11 E5 00 00 00 00 00 00 00 00 00 00 00 00 00 00 00 00
					39 00 00 40 00 00 02 6F 24
					39 00 00 40 00 00 0D E5 00 00 00 00 00 00 00 00 00 00 00 00
					39 00 00 40 00 00 02 6F 46
					39 00 00 40 00 00 0D E5 00 00 00 00 00 00 00 00 00 00 00 00
					39 00 00 40 00 00 02 6F 03
					39 00 00 40 00 00 19 C6 1B 1B 24 23 23 23 23 23 23 1D 1D 25 23 23 23 23 23 23 1B 1B 24 23 23 23
					39 00 00 40 00 00 02 E5 B2
					39 00 00 40 00 00 02 6F 22
					39 00 00 40 00 00 02 E5 B2
					39 00 00 40 00 00 02 6F 44
					39 00 00 40 00 00 02 E5 B2
					39 00 00 40 00 00 06 F0 55 AA 52 08 05
					39 00 00 40 00 00 02 6F 12
					39 00 00 00 00 00 05 EC 00 00 00 00
					];
				qcom,mdss-dsi-timing-switch-command = [
					/* switch to 120*/
					39 00 00 40 00 00 06 F0 55 AA 52 08 00
					39 00 00 00 0C 00 02 2F 00
					39 00 00 40 00 00 02 BE 47
					39 00 00 40 00 00 02 6F A8
					39 00 00 40 00 00 03 BA 00 00
					39 00 00 40 00 00 02 6F B0
					39 00 00 40 00 00 05 BA 00 00 00 00
					39 00 00 40 00 00 02 2F 30
					39 00 00 40 00 00 02 6D 00
					39 00 00 00 00 00 05 35 00 00 00 00
					/* switch */
					39 00 00 40 00 00 06 F0 55 AA 52 08 00
					39 00 00 00 0C 00 02 2F 01
					39 00 00 40 00 00 02 BE 47
					39 00 00 40 00 00 02 6F A8
					39 00 00 40 00 00 03 BA 11 11
					39 00 00 40 00 00 02 6F B0
					39 00 00 40 00 00 05 BA 11 11 00 00
					39 00 00 40 00 00 02 2F 31
					39 00 00 40 00 00 02 6D 00
					39 00 00 00 00 00 05 35 00 00 00 00
					];
				qcom,mdss-dsi-on-command=[
					/* Optimize edge green */
					39 00 00 40 00 00 06 F0 55 AA 52 08 07
					39 00 00 40 00 00 0E B4 C0 80 80 80 80 50 80 80 80 80 80 50 80
					/* Vsync Hsync output */
					39 00 00 40 00 00 06 F0 55 AA 52 08 00
					39 00 00 40 00 00 02 6F 02
					39 00 00 00 00 00 03 BE 49 4C
					/* AVDD=7.9 */
					39 00 00 40 00 00 06 F0 55 AA 52 08 00
					39 00 00 40 00 00 02 6F 07
					39 00 00 40 00 00 02 B5 4E
					/* HBM L0 glows green */
					39 00 00 40 00 00 02 B5 80
					39 00 00 40 00 00 02 6F 2C
					39 00 00 00 00 00 02 B5 03
					39 00 00 40 00 00 05 FF AA 55 A5 81
					39 00 00 40 00 00 02 6F 19
					39 00 00 40 00 00 02 FB 00
					39 00 00 40 00 00 02 6F 05
					39 00 00 40 00 00 02 FE 34
					39 00 00 40 00 00 05 FF AA 55 A5 80
					39 00 00 40 00 00 02 6F 1A
					39 00 00 40 00 00 02 F4 55
					39 00 00 40 00 00 05 FF AA 55 A5 83
					39 00 00 40 00 00 02 6F 12
					39 00 00 40 00 00 02 FE 41
					39 00 00 40 00 00 02 5F 00
					39 00 00 40 00 00 02 26 00
					39 00 00 40 00 00 02 26 00
					39 00 00 40 00 00 02 17 10
					39 00 00 40 00 00 05 2A 00 00 04 D7
					39 00 00 00 00 00 05 2B 00 00 0A D3
					/* Fre 90Hz */
					39 00 00 00 00 00 02 2F 01
					/* TE ON */
					39 00 00 40 00 00 02 35 00
					39 00 00 00 00 00 03 44 00 00
					/* Nor 51 */
					39 00 00 40 00 00 03 51 00 00
					39 00 00 00 00 00 02 6F 04
					/* AOD 51 */
					39 00 00 40 00 00 03 51 00 00
					39 00 00 40 00 00 02 53 20
					39 00 00 00 00 00 03 90 03 03
					/* 10bit DSC */
					39 00 00 40 00 00 13 91 AB 28 00 0C F2 00 02 85 01 0F 00 08 0A E9 07 5F 10 F0
					39 00 00 40 00 00 05 FF AA 55 A5 81
					39 00 00 40 00 00 02 6F 24
					39 00 00 40 00 00 15 FB 00 03 04 55 77 77 77 99 9D 00 00 06 88 9A BB BC DE EF F0 11
					39 00 00 40 00 00 05 FF AA 55 A5 81
					39 00 00 40 00 00 02 6F 0E
					39 00 00 40 00 00 02 F5 00
					39 00 00 40 00 00 05 FF AA 55 A5 80
					39 00 00 40 00 00 02 6F 0F
					39 00 00 40 00 00 02 FC 00
					39 00 00 40 00 00 02 6F 09
					39 00 00 40 00 00 03 FC FC F0
					39 00 00 40 00 00 05 FF AA 55 A5 80
					39 00 00 40 00 00 02 6F 0A
					39 00 00 40 00 00 04 F6 70 70 70
					39 00 00 40 00 00 02 6F 0E
					39 00 00 00 00 00 02 F6 60
					/* OSC start */
					39 00 00 40 00 00 05 FF AA 55 A5 80
					39 00 00 40 00 00 02 6F 11
					/* OSC2 145Mhz */
					39 00 00 40 00 00 03 F8 01 8E
					39 00 00 40 00 00 02 6F 2D
					/* OSC1 121.9Mhz */
					39 00 00 40 00 00 03 F8 00 FC
					39 00 00 40 00 00 02 6F 01
					39 00 00 40 00 00 02 1F 06
					39 00 00 40 00 00 05 FF AA 55 A5 81
					39 00 00 40 00 00 02 6F 1E
					39 00 00 00 00 00 02 FB 0F
					/* OSC end */
					39 00 00 40 00 00 05 FF AA 55 A5 83
					39 00 00 40 00 00 02 6F 12
					39 00 00 40 00 00 02 FE 41
					39 00 00 40 00 00 05 FF AA 55 A5 80
					39 00 00 40 00 00 02 6F 19
					39 00 00 40 00 00 02 F2 00
					39 00 00 40 00 00 05 FF AA 55 A5 81
					39 00 00 40 00 00 02 6F 02
					39 00 00 40 00 00 02 F9 04
					39 00 00 40 00 00 02 5A 00
					/* AOD remove black frame */
					39 00 00 00 00 00 06 F0 55 AA 52 08 01
					39 00 00 00 00 00 06 D2 00 00 00 00 15
					15 00 00 00 00 00 02 6F 05
					39 00 00 00 00 00 04 D2 01 00 00
					15 00 00 00 00 00 02 6F 0E
					39 00 00 00 00 00 06 D2 02 00 10 05 88
					39 00 00 00 00 00 0B E4 80 00 00 00 00 00 00 00 00 33
					15 00 00 00 00 00 02 6F 0A
					39 00 00 00 00 00 07 E4 80 00 00 10 00 53
					/* AOD off splash */
					39 00 00 40 00 00 06 F0 55 AA 52 08 01
					39 00 00 40 00 00 02 6F 0E
					39 00 00 00 00 00 06 D2 02 00 10 05 82
					/* OSC Tracking */
					39 00 00 40 00 00 06 F0 55 AA 52 08 01
					39 00 00 00 00 00 2A C3 DD 06 22 15 F9 00 06 20 15 FF 00 03 E7 16 06 2B 1D 03 E7 16 06 2B 1D 03 E7 16 06 2B 1D 03 E7 16 06 2B 1D 03 E7 16 06 2B 1D
					/* 11H sleep out */
					39 01 00 00 78 00 02 11 00
					39 00 00 40 00 00 06 F0 55 AA 52 08 00
					39 00 00 00 0C 00 02 2F 01
					39 00 00 40 00 00 02 BE 47
					39 00 00 40 00 00 02 6F A8
					39 00 00 40 00 00 03 BA 11 11
					39 00 00 40 00 00 02 6F B0
					39 00 00 40 00 00 05 BA 11 11 00 00
					39 00 00 40 00 00 02 2F 31
					39 00 00 40 00 00 02 6D 00
					39 00 00 00 00 00 05 35 00 00 00 00
					05 00 00 00 00 00 01 29
				];

				qcom,mdss-dsi-panel-info-switch-page-command = [
					/*read panel info switch page 01*/
					39 00 00 00 00 00 06 F0 55 AA 52 08 01
				];
				qcom,mdss-dsi-default-switch-page-command = [
					/*switch default page*/
					39 00 00 00 00 00 06 F0 55 AA 52 08 00
				];

				qcom,mdss-dsi-adfr-auto-on-command = [
					/* SDC Auto On */
				];
				qcom,mdss-dsi-adfr-auto-off-command = [
					/* SDC Auto Off */
				];
				qcom,mdss-dsi-adfr-min-fps-0-command = [
					15 00 00 40 00 00 02 2F 01
					15 00 00 40 00 00 02 2F 31
					15 00 00 00 00 00 02 6D 00
				];
				qcom,mdss-dsi-adfr-min-fps-1-command = [
					15 00 00 40 00 00 02 2F 01
					15 00 00 40 00 00 02 2F 31
					15 00 00 00 00 00 02 6D 01
				];

				qcom,mdss-dsi-post-on-backlight = [
					/* Display On */
					05 00 00 00 00 00 01 29
				];
				qcom,mdss-dsi-off-command=[
					05 00 00 00 0A 00 01 28
					05 00 00 00 78 00 01 10
				];
				qcom,mdss-dsi-lp1-command = [
					/* AOD Mode ON Setting */
					39 00 00 00 00 00 06 F0 55 AA 52 08 00
					15 00 00 00 00 00 02 6F 0C
					39 00 00 00 00 00 03 B5 50 4B
					39 00 00 00 00 00 05 35 00 00 00 00
					39 00 00 00 00 00 03 44 00 00
					15 00 00 00 10 00 02 2F 00
					05 00 00 00 00 00 01 39
					15 00 00 00 00 00 02 65 01
					15 00 00 00 00 00 02 6F 04
					39 00 00 00 00 00 03 51 02 FF
				];
				qcom,mdss-dsi-nolp-command = [
					/* AOD OFF */
					39 00 00 00 00 00 06 F0 55 AA 52 08 00
					15 00 00 00 00 00 02 6F 0C
					39 00 00 00 00 00 03 B5 4F 4B
					15 00 00 00 00 00 02 65 00
					05 00 00 00 00 00 01 38
					15 00 00 00 00 00 02 2F 31
					15 00 00 00 00 00 02 6D 00
					39 00 00 00 00 00 05 35 00 00 00 00
					39 00 00 00 00 00 03 44 00 00
					39 00 00 00 28 00 03 51 00 00
				];
				qcom,mdss-dsi-hbm-off-command = [
					//39 00 00 00 00 00 03 51 0D BB
				];
				qcom,mdss-dsi-hbm-on-command = [
					39 00 00 40 00 00 06 F0 55 AA 52 08 01
					39 00 00 40 00 00 02 6F 02
					39 00 00 40 00 00 11 E5 00 00 00 00 20 20 20 00 28 28 28 00 30 30 30 00
					39 00 00 40 00 00 02 6F 24
					39 00 00 40 00 00 0D E5 00 00 00 00 20 20 20 00 28 28 28 00
					39 00 00 40 00 00 02 6F 46
					39 00 00 40 00 00 0D E5 00 00 00 00 20 20 20 00 28 28 28 00
					39 00 00 40 00 00 02 6F 03
					39 00 00 40 00 00 19 C6 37 37 37 23 23 23 23 23 23 37 37 37 23 23 23 23 23 23 37 37 37 23 23 23
					39 00 00 40 00 00 02 E5 B2
					39 00 00 40 00 00 02 6F 22
					39 00 00 40 00 00 02 E5 B2
					39 00 00 40 00 00 02 6F 44
					39 00 00 40 00 00 02 E5 B2
					39 00 00 40 00 00 06 F0 55 AA 52 08 05
					39 00 00 40 00 00 02 6F 12
					39 00 00 40 00 00 05 EC 00 00 00 00
					39 00 00 40 00 00 06 F0 55 AA 52 08 00
					39 00 00 40 00 00 02 6F 11
					39 00 00 40 00 00 04 B2 02 03 42
					39 00 00 40 00 00 2D B3 00 08 00 B4 00 B4 01 5F 01 5F 02 20 02 20 03 7C 03 7C 05 30 05 30 06 43 06 43 06 44 06 44 09 0B 09 0B 0D BB 0D BB 0F FF 0F FF 0F FF
					39 00 00 40 00 00 2F B4 00 00 00 80 00 96 00 96 00 C0 00 C0 01 26 01 26 02 8E 02 8E 05 8E 05 8E 08 26 08 26 09 40 09 40 09 40 09 40 09 40 09 40 09 40 09 40 09 40
					39 00 00 40 00 00 02 6F 2E
					39 00 00 40 00 00 2F B4 00 00 00 E2 00 FF 00 FF 01 3A 01 3A 01 CE 01 CE 03 AA 03 AA 07 9C 07 9C 0B 20 0B 20 0C 56 0C 56 0C 56 0C 56 0C 56 0C 56 0C 56 0C 56 0C 56
					39 00 00 40 00 00 02 6F 5C
					39 00 00 40 00 00 2F B4 00 00 00 78 00 8C 00 8C 00 B4 00 B4 01 26 01 26 02 8E 02 8E 05 8E 05 8E 08 26 08 26 09 40 09 40 09 40 09 40 09 40 09 40 09 40 09 40 09 40
					39 00 00 00 00 00 03 51 0F 00
				];
				qcom,mdss-dsi-hbm-on-onepulse-command = [
					39 00 00 40 00 00 06 F0 55 AA 52 08 01
					39 00 00 40 00 00 02 6F 02
					39 00 00 40 00 00 11 E5 00 00 00 00 00 00 00 00 00 00 00 00 00 00 00 00
					39 00 00 40 00 00 02 6F 24
					39 00 00 40 00 00 0D E5 00 00 00 00 20 20 20 00 28 28 28 00
					39 00 00 40 00 00 02 6F 46
					39 00 00 40 00 00 0D E5 00 00 00 00 20 20 20 00 28 28 28 00
					39 00 00 40 00 00 02 6F 03
					39 00 00 40 00 00 19 C6 1D 1D 1D 23 23 23 23 23 23 37 37 37 23 23 23 23 23 23 37 37 37 23 23 23
					39 00 00 40 00 00 02 E5 B2
					39 00 00 40 00 00 02 6F 22
					39 00 00 40 00 00 02 E5 B2
					39 00 00 40 00 00 02 6F 44
					39 00 00 40 00 00 02 E5 B2
					39 00 00 40 00 00 06 F0 55 AA 52 08 05
					39 00 00 40 00 00 02 6F 12
					39 00 00 40 00 00 05 EC 00 00 00 00
					39 00 00 40 00 00 06 F0 55 AA 52 08 00
					39 00 00 40 00 00 02 6F 11
					39 00 00 40 00 00 04 B2 00 00 40
					39 00 00 40 00 00 2D B3 00 08 00 B4 00 B4 01 5F 01 5F 02 20 02 20 03 7C 03 7C 05 30 05 30 06 43 06 43 06 44 06 44 09 0B 09 0B 0D BB 0D BB 0F FF 0F FF 0F FF
					39 00 00 40 00 00 2F B4 00 00 00 80 00 96 00 96 00 C0 00 C0 01 26 01 26 02 8E 02 8E 05 8E 05 8E 08 26 08 26 0A DE 0A DE 0A DE 0A DE 0A DE 0A DE 0A DE 0A DE 0A DE
					39 00 00 40 00 00 02 6F 2E
					39 00 00 40 00 00 2F B4 00 00 00 E2 00 FF 00 FF 01 3A 01 3A 01 CE 01 CE 03 AA 03 AA 07 9C 07 9C 0B 20 0B 20 0E 5B 0E 5B 0E 5B 0E 5B 0E 5B 0E 5B 0E 5B 0E 5B 0E 5B
					39 00 00 40 00 00 02 6F 5C
					39 00 00 40 00 00 2F B4 00 00 00 78 00 8C 00 8C 00 B4 00 B4 01 26 01 26 02 8E 02 8E 05 8E 05 8E 08 26 08 26 0A DE 0A DE 0A DE 0A DE 0A DE 0A DE 0A DE 0A DE 0A DE
					39 00 00 00 00 00 03 51 0F 00
				];
				qcom,mdss-dsi-aod-high-mode-command = [
					/* AOD 50nit */
					15 00 00 40 00 00 02 6F 04
					39 00 00 00 00 00 03 51 02 FF
				];
				qcom,mdss-dsi-aod-low-mode-command = [
					/* AOD 10nit */
					15 00 00 40 00 00 02 6F 04
					39 00 00 00 00 00 03 51 01 FF
				];
				qcom,mdss-dsi-temperature-compensation-command = [
					39 00 00 40 00 00 06 F0 55 AA 52 08 01
					39 00 00 40 00 00 02 6F 06
					39 00 00 40 00 00 05 E5 00 00 00 00
					39 00 00 40 00 00 02 6F 0A
					39 00 00 40 00 00 05 E5 00 00 00 00
					39 00 00 40 00 00 02 6F 0E
					39 00 00 40 00 00 05 E5 00 00 00 00
					39 00 00 40 00 00 02 6F 28
					39 00 00 40 00 00 05 E5 00 00 00 00
					39 00 00 40 00 00 02 6F 2C
					39 00 00 40 00 00 05 E5 00 00 00 00
					39 00 00 40 00 00 02 6F 4A
					39 00 00 40 00 00 05 E5 00 00 00 00
					39 00 00 40 00 00 02 6F 4E
					39 00 00 40 00 00 05 E5 00 00 00 00
					39 00 00 40 00 00 02 6F 52
					39 00 00 40 00 00 05 E5 00 00 00 00
					39 00 00 40 00 00 02 6F 03
					39 00 00 40 00 00 04 C6 00 00 00
					39 00 00 40 00 00 02 6F 0C
					39 00 00 40 00 00 04 C6 00 00 00
					39 00 00 40 00 00 02 6F 15
					39 00 00 40 00 00 04 C6 00 00 00
					39 00 00 40 00 00 06 F0 55 AA 52 08 05
					39 00 00 40 00 00 02 6F 12
					39 00 00 00 00 00 05 EC 00 00 00 00
				];
				/* origin 3 pulse */
				qcom,mdss-dsi-pwm-switch-high-command = [
					39 00 00 40 00 00 06 F0 55 AA 52 08 00
					39 00 00 40 00 00 02 6F 11
					39 00 00 40 00 00 04 B2 02 03 42
					39 00 00 40 00 00 2D B3 00 08 00 B4 00 B4 01 5F 01 5F 02 20 02 20 03 7C 03 7C 05 30 05 30 06 43 06 43 06 44 06 44 09 0B 09 0B 0D BB 0D BB 0F FF 0F FF 0F FF
					39 00 00 40 00 00 2F B4 00 00 00 80 00 96 00 96 00 C0 00 C0 01 26 01 26 02 8E 02 8E 05 8E 05 8E 08 26 08 26 09 40 09 40 09 40 09 40 09 40 09 40 09 40 09 40 09 40
					39 00 00 40 00 00 02 6F 2E
					39 00 00 40 00 00 2F B4 00 00 00 E2 00 FF 00 FF 01 3A 01 3A 01 CE 01 CE 03 AA 03 AA 07 9C 07 9C 0B 20 0B 20 0C 56 0C 56 0C 56 0C 56 0C 56 0C 56 0C 56 0C 56 0C 56
					39 00 00 40 00 00 02 6F 5C
					39 00 00 40 00 00 2F B4 00 00 00 78 00 8C 00 8C 00 B4 00 B4 01 26 01 26 02 8E 02 8E 05 8E 05 8E 08 26 08 26 09 40 09 40 09 40 09 40 09 40 09 40 09 40 09 40 09 40
					39 00 00 00 00 00 03 51 06 44
				];
				qcom,mdss-dsi-pwm-switch-low-command = [
					39 00 00 40 00 00 06 F0 55 AA 52 08 00
					39 00 00 40 00 00 02 6F 11
					39 00 00 40 00 00 04 B2 0F 17 4E
					39 00 00 40 00 00 2D B3 00 08 00 B4 00 B4 01 5F 01 5F 02 20 02 20 03 7C 03 7C 05 30 05 30 06 43 06 43 06 44 06 44 09 0B 09 0B 0D BB 0D BB 0F FF 0F FF 0F FF
					39 00 00 40 00 00 2F B4 00 00 00 80 00 96 00 96 00 C0 00 C0 01 26 01 26 02 8E 02 8E 05 8E 05 8E 08 26 08 26 09 40 09 40 09 40 09 40 09 40 09 40 09 40 09 40 09 40
					39 00 00 40 00 00 02 6F 2E
					39 00 00 40 00 00 2F B4 00 00 00 E2 00 FF 00 FF 01 3A 01 3A 01 CE 01 CE 03 AA 03 AA 07 9C 07 9C 0B 20 0B 20 0C 56 0C 56 0C 56 0C 56 0C 56 0C 56 0C 56 0C 56 0C 56
					39 00 00 40 00 00 02 6F 5C
					39 00 00 40 00 00 2F B4 00 00 00 78 00 8C 00 8C 00 B4 00 B4 01 26 01 26 02 8E 02 8E 05 8E 05 8E 08 26 08 26 09 40 09 40 09 40 09 40 09 40 09 40 09 40 09 40 09 40
					39 00 00 00 00 00 03 51 06 43
				];
				/* origin 3 pulse */
				qcom,mdss-dsi-timming-pwm-switch-high-command = [
					39 00 00 40 00 00 06 F0 55 AA 52 08 00
					39 00 00 40 00 00 02 6F 11
					39 00 00 40 00 00 04 B2 02 03 42
					39 00 00 40 00 00 2D B3 00 08 00 B4 00 B4 01 5F 01 5F 02 20 02 20 03 7C 03 7C 05 30 05 30 06 43 06 43 06 44 06 44 09 0B 09 0B 0D BB 0D BB 0F FF 0F FF 0F FF
					39 00 00 40 00 00 2F B4 00 00 00 80 00 96 00 96 00 C0 00 C0 01 26 01 26 02 8E 02 8E 05 8E 05 8E 08 26 08 26 09 40 09 40 09 40 09 40 09 40 09 40 09 40 09 40 09 40
					39 00 00 40 00 00 02 6F 2E
					39 00 00 40 00 00 2F B4 00 00 00 E2 00 FF 00 FF 01 3A 01 3A 01 CE 01 CE 03 AA 03 AA 07 9C 07 9C 0B 20 0B 20 0C 56 0C 56 0C 56 0C 56 0C 56 0C 56 0C 56 0C 56 0C 56
					39 00 00 40 00 00 02 6F 5C
					39 00 00 00 00 00 2F B4 00 00 00 78 00 8C 00 8C 00 B4 00 B4 01 26 01 26 02 8E 02 8E 05 8E 05 8E 08 26 08 26 09 40 09 40 09 40 09 40 09 40 09 40 09 40 09 40 09 40
				];
				qcom,mdss-dsi-timming-pwm-switch-low-command = [
					39 00 00 40 00 00 06 F0 55 AA 52 08 00
					39 00 00 40 00 00 02 6F 11
					39 00 00 40 00 00 04 B2 0F 17 4E
					39 00 00 40 00 00 2D B3 00 08 00 B4 00 B4 01 5F 01 5F 02 20 02 20 03 7C 03 7C 05 30 05 30 06 43 06 43 06 44 06 44 09 0B 09 0B 0D BB 0D BB 0F FF 0F FF 0F FF
					39 00 00 40 00 00 2F B4 00 00 00 80 00 96 00 96 00 C0 00 C0 01 26 01 26 02 8E 02 8E 05 8E 05 8E 08 26 08 26 09 40 09 40 09 40 09 40 09 40 09 40 09 40 09 40 09 40
					39 00 00 40 00 00 02 6F 2E
					39 00 00 40 00 00 2F B4 00 00 00 E2 00 FF 00 FF 01 3A 01 3A 01 CE 01 CE 03 AA 03 AA 07 9C 07 9C 0B 20 0B 20 0C 56 0C 56 0C 56 0C 56 0C 56 0C 56 0C 56 0C 56 0C 56
					39 00 00 40 00 00 02 6F 5C
					39 00 00 00 00 00 2F B4 00 00 00 78 00 8C 00 8C 00 B4 00 B4 01 26 01 26 02 8E 02 8E 05 8E 05 8E 08 26 08 26 09 40 09 40 09 40 09 40 09 40 09 40 09 40 09 40 09 40
				];
				qcom,mdss-dsi-pwm-switch-onepulse-command = [
					39 00 00 40 00 00 06 F0 55 AA 52 08 00
					39 00 00 40 00 00 02 6F 11
					39 00 00 40 00 00 04 B2 00 00 40
					39 00 00 40 00 00 2D B3 00 08 00 B4 00 B4 01 5F 01 5F 02 20 02 20 03 7C 03 7C 05 30 05 30 06 43 06 43 06 44 06 44 09 0B 09 0B 0D BB 0D BB 0F FF 0F FF 0F FF
					39 00 00 40 00 00 2F B4 00 00 00 80 00 96 00 96 00 C0 00 C0 01 26 01 26 02 8E 02 8E 05 8E 05 8E 08 26 08 26 0A DE 0A DE 0A DE 0A DE 0A DE 0A DE 0A DE 0A DE 0A DE
					39 00 00 40 00 00 02 6F 2E
					39 00 00 40 00 00 2F B4 00 00 00 E2 00 FF 00 FF 01 3A 01 3A 01 CE 01 CE 03 AA 03 AA 07 9C 07 9C 0B 20 0B 20 0E 5B 0E 5B 0E 5B 0E 5B 0E 5B 0E 5B 0E 5B 0E 5B 0E 5B
					39 00 00 40 00 00 02 6F 5C
					39 00 00 40 00 00 2F B4 00 00 00 78 00 8C 00 8C 00 B4 00 B4 01 26 01 26 02 8E 02 8E 05 8E 05 8E 08 26 08 26 0A DE 0A DE 0A DE 0A DE 0A DE 0A DE 0A DE 0A DE 0A DE
					39 00 00 00 00 00 03 51 06 44
				];
				qcom,mdss-dsi-timming-pwm-switch-onepulse-command = [
					39 00 00 40 00 00 06 F0 55 AA 52 08 00
					39 00 00 40 00 00 02 6F 11
					39 00 00 40 00 00 04 B2 00 00 40
					39 00 00 40 00 00 2D B3 00 08 00 B4 00 B4 01 5F 01 5F 02 20 02 20 03 7C 03 7C 05 30 05 30 06 43 06 43 06 44 06 44 09 0B 09 0B 0D BB 0D BB 0F FF 0F FF 0F FF
					39 00 00 40 00 00 2F B4 00 00 00 80 00 96 00 96 00 C0 00 C0 01 26 01 26 02 8E 02 8E 05 8E 05 8E 08 26 08 26 0A DE 0A DE 0A DE 0A DE 0A DE 0A DE 0A DE 0A DE 0A DE
					39 00 00 40 00 00 02 6F 2E
					39 00 00 40 00 00 2F B4 00 00 00 E2 00 FF 00 FF 01 3A 01 3A 01 CE 01 CE 03 AA 03 AA 07 9C 07 9C 0B 20 0B 20 0E 5B 0E 5B 0E 5B 0E 5B 0E 5B 0E 5B 0E 5B 0E 5B 0E 5B
					39 00 00 40 00 00 02 6F 5C
					39 00 00 00 00 00 2F B4 00 00 00 78 00 8C 00 8C 00 B4 00 B4 01 26 01 26 02 8E 02 8E 05 8E 05 8E 08 26 08 26 0A DE 0A DE 0A DE 0A DE 0A DE 0A DE 0A DE 0A DE 0A DE
				];
				qcom,mdss-dsi-pwm-switch-threepulse-command = [
					39 00 00 40 00 00 06 F0 55 AA 52 08 00
					39 00 00 40 00 00 02 6F 11
					39 00 00 40 00 00 04 B2 02 03 42
					39 00 00 40 00 00 2D B3 00 08 00 B4 00 B4 01 5F 01 5F 02 20 02 20 03 7C 03 7C 05 30 05 30 06 43 06 43 06 44 06 44 09 0B 09 0B 0D BB 0D BB 0F FF 0F FF 0F FF
					39 00 00 40 00 00 2F B4 00 00 00 80 00 96 00 96 00 C0 00 C0 01 26 01 26 02 8E 02 8E 05 8E 05 8E 08 26 08 26 09 40 09 40 09 40 09 40 09 40 09 40 09 40 09 40 09 40
					39 00 00 40 00 00 02 6F 2E
					39 00 00 40 00 00 2F B4 00 00 00 E2 00 FF 00 FF 01 3A 01 3A 01 CE 01 CE 03 AA 03 AA 07 9C 07 9C 0B 20 0B 20 0C 56 0C 56 0C 56 0C 56 0C 56 0C 56 0C 56 0C 56 0C 56
					39 00 00 40 00 00 02 6F 5C
					39 00 00 00 00 00 2F B4 00 00 00 78 00 8C 00 8C 00 B4 00 B4 01 26 01 26 02 8E 02 8E 05 8E 05 8E 08 26 08 26 09 40 09 40 09 40 09 40 09 40 09 40 09 40 09 40 09 40
				];
				qcom,mdss-dsi-timing-switch-command-state = "dsi_hs_mode";
				qcom,mdss-dsi-on-command-state = "dsi_lp_mode";
				qcom,mdss-dsi-off-command-state = "dsi_hs_mode";
				qcom,mdss-dsi-hbm-on-command-state = "dsi_lp_mode";
				qcom,mdss-dsi-hbm-on-onepulse-command-state = "dsi_lp_mode";
				qcom,mdss-dsi-hbm-off-command-state = "dsi_lp_mode";
				qcom,mdss-dsi-skipframe-dbv-command-state = "dsi_hs_mode";
				qcom,mdss-dsi-adfr-auto-on-command-state ="dsi_hs_mode";
				qcom,mdss-dsi-adfr-auto-off-command-state ="dsi_hs_mode";
				qcom,mdss-dsi-adfr-min-fps-0-command-state = "dsi_hs_mode";
				qcom,mdss-dsi-adfr-min-fps-1-command-state = "dsi_hs_mode";
				qcom,mdss-dsi-bl-demua1-command-state = "dsi_hs_mode";
				qcom,mdss-dsi-bl-demua2-command-state = "dsi_hs_mode";
				qcom,mdss-dsi-bl-demua3-command-state = "dsi_hs_mode";
				qcom,mdss-dsi-bl-demua4-command-state = "dsi_hs_mode";
				qcom,mdss-dsi-bl-demua5-command-state = "dsi_hs_mode";
				qcom,mdss-dsi-bl-demua6-command-state = "dsi_hs_mode";
				qcom,mdss-dsi-panel-info-switch-page-command-state = "dsi_lp_mode";
				qcom,mdss-dsi-default-switch-page-command-state = "dsi_lp_mode";

                qcom,mdss-dsi-pwm-switch-high-command-state = "dsi_hs_mode";
				qcom,mdss-dsi-pwm-switch-low-command-state = "dsi_hs_mode";
				qcom,mdss-dsi-timming-pwm-switch-high-command-state = "dsi_hs_mode";
				qcom,mdss-dsi-timming-pwm-switch-low-command-state = "dsi_hs_mode";
				qcom,mdss-dsi-pwm-switch-onepulse-command-state = "dsi_hs_mode";
				qcom,mdss-dsi-timming-pwm-switch-onepulse-command-state = "dsi_hs_mode";
				qcom,mdss-dsi-pwm-switch-threepulse-command-state = "dsi_hs_mode";
				qcom,lm-split = <620 620>;
				qcom,compression-mode = "dsc";
				qcom,mdss-dsc-encoders = <2>;
				qcom,mdss-dsc-slice-height = <12>;
				qcom,mdss-dsc-slice-width = <620>;
				qcom,mdss-dsc-slice-per-pkt = <2>;
				qcom,mdss-dsc-bit-per-component = <10>;
				qcom,mdss-dsc-bit-per-pixel = <8>;
				qcom,mdss-dsc-block-prediction-enable;
			};
			timing@sa_fhd_60{
				qcom,mdss-mdp-transfer-time-us = <7500>;
				qcom,mdss-mdp-transfer-time-us-min = <6000>;
				qcom,mdss-mdp-transfer-time-us-max = <7500>;
				qcom,mdss-dsi-panel-jitter = <0x4 0x1>;
				qcom,mdss-dsc-scr-version = <0x1>;
				qcom,mdss-dsc-version = <0x11>;
				qcom,mdss-dsi-panel-framerate = <60>;
				qcom,mdss-dsi-panel-clockrate = <1363200000>;
				qcom,mdss-dsi-panel-width = <1240>;
				qcom,mdss-dsi-panel-height = <2772>;

				qcom,mdss-dsi-h-front-porch = <64>;
				qcom,mdss-dsi-h-back-porch = <48>;
				qcom,mdss-dsi-h-pulse-width = <8>;
				qcom,mdss-dsi-v-back-porch = <8>;
				qcom,mdss-dsi-v-front-porch = <2>;
				qcom,mdss-dsi-v-pulse-width = <2>;
				qcom,mdss-dsi-h-sync-pulse = <0>;

				qcom,mdss-dsi-h-left-border = <0>;
				qcom,mdss-dsi-h-right-border = <0>;
				qcom,mdss-dsi-v-top-border = <0>;
				qcom,mdss-dsi-v-bottom-border = <0>;

				/* Apollo vsync config, need to measure TE signal */
				//oplus,apollo-panel-vsync-width = <13000>;
				//oplus,apollo-panel-vsync-period = <16600>;
				/* standard adfr */
				qcom,mdss-dsi-h-sync-skew = <0>;
				oplus,adfr-min-fps-mapping-table = <60 40>;

				qcom,mdss-dsi-panel-vsync-source = <1>;
				qcom,mdss-dsi-qsync-min-fps-0 = <1314>;
				oplus,fod-on-vblank = <0>;
				oplus,fod-off-vblank = <0>;
				oplus,ofp-need-to-filter-backlight-dim-icon;
				qcom,mdss-dsi-bl-demua1-command = [
					/* 51hex > 0x644 */
					39 00 00 50 00 00 06 F0 55 AA 52 08 04
					39 00 00 50 00 00 02 6F 02
					39 00 00 50 00 00 03 EC 01 03
					39 00 00 50 00 00 02 6F A5
					39 00 00 10 00 00 07 EC 01 01 01 03 03 03
				];
				qcom,mdss-dsi-bl-demua2-command = [
					/* 0x644>51hex>=0x530 */
					39 00 00 50 00 00 06 F0 55 AA 52 08 04
					39 00 00 50 00 00 02 6F 02
					39 00 00 50 00 00 03 EC 03 0B
					39 00 00 50 00 00 02 6F A5
					39 00 00 10 00 00 07 EC 03 03 03 0B 0B 0B
				];
				qcom,mdss-dsi-bl-demua3-command = [
					/* 0x530>51hex>=0x33A */
					39 00 00 50 00 00 06 F0 55 AA 52 08 04
					39 00 00 50 00 00 02 6F 02
					39 00 00 50 00 00 03 EC 10 18
					39 00 00 50 00 00 02 6F A5
					39 00 00 10 00 00 07 EC 10 10 10 18 18 18
				];
				qcom,mdss-dsi-bl-demua4-command = [
					/* 0x339>51hex>=0x25C */
					39 00 00 50 00 00 06 F0 55 AA 52 08 04
					39 00 00 50 00 00 02 6F 02
					39 00 00 50 00 00 03 EC 15 1D
					39 00 00 50 00 00 02 6F A5
					39 00 00 10 00 00 07 EC 15 15 15 1D 1D 1D
				];
				qcom,mdss-dsi-bl-demua5-command = [
					/* 0x25C>51hex>=0x196 */
					39 00 00 50 00 00 06 F0 55 AA 52 08 04
					39 00 00 50 00 00 02 6F 02
					39 00 00 50 00 00 03 EC 15 2D
					39 00 00 50 00 00 02 6F A5
					39 00 00 10 00 00 07 EC 15 15 15 2D 2D 2D
				];
				qcom,mdss-dsi-bl-demua6-command = [
					/* 0x196>51hex>=0x008 */
					39 00 00 50 00 00 06 F0 55 AA 52 08 04
					39 00 00 50 00 00 02 6F 02
					39 00 00 50 00 00 03 EC 15 4D
					39 00 00 50 00 00 02 6F A5
					39 00 00 10 00 00 07 EC 15 15 15 4D 4D 4D
				];
				qcom,mdss-dsi-skipframe-dbv-command = [
					39 00 00 40 00 00 06 F0 55 AA 52 08 01
					39 00 00 40 00 00 02 6F 02
					39 00 00 40 00 00 11 E5 00 00 00 00 00 00 00 00 00 00 00 00 00 00 00 00
					39 00 00 40 00 00 02 6F 24
					39 00 00 40 00 00 0D E5 00 00 00 00 00 00 00 00 00 00 00 00
					39 00 00 40 00 00 02 6F 46
					39 00 00 40 00 00 0D E5 00 00 00 00 00 00 00 00 00 00 00 00
					39 00 00 40 00 00 02 6F 03
					39 00 00 40 00 00 19 C6 1B 1B 24 23 23 23 23 23 23 1D 1D 25 23 23 23 23 23 23 1B 1B 24 23 23 23
					39 00 00 40 00 00 02 E5 B2
					39 00 00 40 00 00 02 6F 22
					39 00 00 40 00 00 02 E5 B2
					39 00 00 40 00 00 02 6F 44
					39 00 00 40 00 00 02 E5 B2
					39 00 00 40 00 00 06 F0 55 AA 52 08 05
					39 00 00 40 00 00 02 6F 12
					39 00 00 00 00 00 05 EC 00 00 00 00
					];
				qcom,mdss-dsi-timing-switch-command = [
					/* switch60Hz */
					39 00 00 40 00 00 06 F0 55 AA 52 08 00
					39 00 00 00 11 00 02 2F 00
					39 00 00 40 00 00 02 BE 47
					39 00 00 40 00 00 02 6F A8
					39 00 00 40 00 00 03 BA 00 00
					39 00 00 40 00 00 02 6F B0
					39 00 00 40 00 00 05 BA 00 00 00 00
					39 00 00 40 00 00 02 2F 30
					39 00 00 40 00 00 02 6D 01
					39 00 00 00 00 00 05 35 00 00 00 01
					];
				qcom,mdss-dsi-on-command=[
					/* Optimize edge green */
					39 00 00 40 00 00 06 F0 55 AA 52 08 07
					39 00 00 40 00 00 0E B4 C0 80 80 80 80 50 80 80 80 80 80 50 80
					/* Vsync Hsync output */
					39 00 00 40 00 00 06 F0 55 AA 52 08 00
					39 00 00 40 00 00 02 6F 02
					39 00 00 00 00 00 03 BE 49 4C
					/* AVDD=7.9 */
					39 00 00 40 00 00 06 F0 55 AA 52 08 00
					39 00 00 40 00 00 02 6F 07
					39 00 00 40 00 00 02 B5 4E
					/* HBM L0 glows green */
					39 00 00 40 00 00 02 B5 80
					39 00 00 40 00 00 02 6F 2C
					39 00 00 00 00 00 02 B5 03
					39 00 00 40 00 00 05 FF AA 55 A5 81
					39 00 00 40 00 00 02 6F 19
					39 00 00 40 00 00 02 FB 00
					39 00 00 40 00 00 02 6F 05
					39 00 00 40 00 00 02 FE 34
					39 00 00 40 00 00 05 FF AA 55 A5 80
					39 00 00 40 00 00 02 6F 1A
					39 00 00 40 00 00 02 F4 55
					39 00 00 40 00 00 05 FF AA 55 A5 83
					39 00 00 40 00 00 02 6F 12
					39 00 00 40 00 00 02 FE 41
					39 00 00 40 00 00 02 5F 00
					39 00 00 40 00 00 02 26 00
					39 00 00 40 00 00 02 26 00
					39 00 00 40 00 00 02 17 10
					39 00 00 40 00 00 05 2A 00 00 04 D7
					39 00 00 00 00 00 05 2B 00 00 0A D3
					/* Fre 120Hz */
					39 00 00 00 00 00 02 2F 00
					/* TE ON */
					/*39 00 00 40 00 00 02 35 00*/
					39 00 00 00 00 00 03 44 00 00
					/* Nor 51 */
					39 00 00 40 00 00 03 51 00 00
					39 00 00 00 00 00 02 6F 04
					/* AOD 51 */
					39 00 00 40 00 00 03 51 00 00
					39 00 00 40 00 00 02 53 20
					39 00 00 00 00 00 03 90 03 03
					/* 10bit DSC */
					39 00 00 40 00 00 13 91 AB 28 00 0C F2 00 02 85 01 0F 00 08 0A E9 07 5F 10 F0
					39 00 00 40 00 00 05 FF AA 55 A5 81
					39 00 00 40 00 00 02 6F 24
					39 00 00 40 00 00 15 FB 00 03 04 55 77 77 77 99 9D 00 00 06 88 9A BB BC DE EF F0 11
					39 00 00 40 00 00 05 FF AA 55 A5 81
					39 00 00 40 00 00 02 6F 0E
					39 00 00 40 00 00 02 F5 00
					39 00 00 40 00 00 05 FF AA 55 A5 80
					39 00 00 40 00 00 02 6F 0F
					39 00 00 40 00 00 02 FC 00
					39 00 00 40 00 00 02 6F 09
					39 00 00 40 00 00 03 FC FC F0
					39 00 00 40 00 00 05 FF AA 55 A5 80
					39 00 00 40 00 00 02 6F 0A
					39 00 00 40 00 00 04 F6 70 70 70
					39 00 00 40 00 00 02 6F 0E
					39 00 00 00 00 00 02 F6 60
					/* OSC start */
					39 00 00 40 00 00 05 FF AA 55 A5 80
					39 00 00 40 00 00 02 6F 11
					/* OSC2 145Mhz */
					39 00 00 40 00 00 03 F8 01 8E
					39 00 00 40 00 00 02 6F 2D
					/* OSC1 121.9Mhz */
					39 00 00 40 00 00 03 F8 00 FC
					39 00 00 40 00 00 02 6F 01
					39 00 00 40 00 00 02 1F 06
					39 00 00 40 00 00 05 FF AA 55 A5 81
					39 00 00 40 00 00 02 6F 1E
					39 00 00 00 00 00 02 FB 0F
					/* OSC end */
					39 00 00 40 00 00 05 FF AA 55 A5 83
					39 00 00 40 00 00 02 6F 12
					39 00 00 40 00 00 02 FE 41
					39 00 00 40 00 00 05 FF AA 55 A5 80
					39 00 00 40 00 00 02 6F 19
					39 00 00 40 00 00 02 F2 00
					39 00 00 40 00 00 05 FF AA 55 A5 81
					39 00 00 40 00 00 02 6F 02
					39 00 00 40 00 00 02 F9 04
					39 00 00 40 00 00 02 5A 00
					/* AOD remove black frame */
					39 00 00 00 00 00 06 F0 55 AA 52 08 01
					39 00 00 00 00 00 06 D2 00 00 00 00 15
					15 00 00 00 00 00 02 6F 05
					39 00 00 00 00 00 04 D2 01 00 00
					15 00 00 00 00 00 02 6F 0E
					39 00 00 00 00 00 06 D2 02 00 10 05 88
					39 00 00 00 00 00 0B E4 80 00 00 00 00 00 00 00 00 33
					15 00 00 00 00 00 02 6F 0A
					39 00 00 00 00 00 07 E4 80 00 00 10 00 53
					/* AOD off splash */
					39 00 00 40 00 00 06 F0 55 AA 52 08 01
					39 00 00 40 00 00 02 6F 0E
					39 00 00 00 00 00 06 D2 02 00 10 05 82
					/* OSC Tracking */
					39 00 00 40 00 00 06 F0 55 AA 52 08 01
					39 00 00 00 00 00 2A C3 DD 06 22 15 F9 00 06 20 15 FF 00 03 E7 16 06 2B 1D 03 E7 16 06 2B 1D 03 E7 16 06 2B 1D 03 E7 16 06 2B 1D 03 E7 16 06 2B 1D
					/* 11H sleep out */
					39 01 00 00 78 00 02 11 00
					/* timing-switch */
					39 00 00 40 00 00 06 F0 55 AA 52 08 00
					39 00 00 00 11 00 02 2F 00
					39 00 00 40 00 00 02 6F A8
					39 00 00 40 00 00 03 BA 00 00
					39 00 00 40 00 00 02 6F B0
					39 00 00 40 00 00 05 BA 00 00 00 00
					39 00 00 40 00 00 02 2F 30
					39 00 00 40 00 00 02 6D 01
					39 00 00 00 00 00 05 35 00 00 00 01
					05 00 00 00 00 00 01 29
				];

				qcom,mdss-dsi-panel-info-switch-page-command = [
					/*read panel info switch page 01*/
					39 00 00 00 00 00 06 F0 55 AA 52 08 01
				];
				qcom,mdss-dsi-default-switch-page-command = [
					/*switch default page*/
					39 00 00 00 00 00 06 F0 55 AA 52 08 00
				];

				qcom,mdss-dsi-adfr-auto-on-command = [
					/* SDC Auto On */
				];
				qcom,mdss-dsi-adfr-auto-off-command = [
					/* SDC Auto Off */
				];
				qcom,mdss-dsi-adfr-min-fps-0-command = [
					15 00 00 40 00 00 02 2F 00
					15 00 00 40 00 00 02 2F 30
					15 00 00 00 00 00 02 6D 01
				];
				qcom,mdss-dsi-adfr-min-fps-1-command = [
					15 00 00 40 00 00 02 2F 00
					15 00 00 40 00 00 02 2F 30
					15 00 00 00 00 00 02 6D 02
				];

				qcom,mdss-dsi-post-on-backlight = [
					/* Display On */
					05 00 00 00 00 00 01 29
				];
				qcom,mdss-dsi-off-command=[
					05 00 00 00 0A 00 01 28
					05 00 00 00 78 00 01 10
				];
				qcom,mdss-dsi-lp1-command = [
					/* FD OFF */
					39 00 00 00 00 00 06 F0 55 AA 52 08 00
					15 00 00 00 00 00 02 6F 0C
					39 00 00 00 00 00 03 B5 50 4B
					39 00 00 00 00 00 05 35 00 00 00 00
					39 00 00 00 00 00 03 44 00 00
					/* AOD Mode 30Hz */
					15 00 00 00 10 00 02 2F 00
					05 00 00 00 00 00 01 39
					15 00 00 00 00 00 02 65 01
					/* 50nit */
					15 00 00 00 00 00 02 6F 04
					39 00 00 00 00 00 03 51 02 FF
				];
				qcom,mdss-dsi-nolp-command = [
					/* AOD OFF */
					39 00 00 00 00 00 06 F0 55 AA 52 08 00
					15 00 00 00 00 00 02 6F 0C
					39 00 00 00 00 00 03 B5 4F 4B
					15 00 00 00 00 00 02 65 00
					05 00 00 00 00 00 01 38
					/* Switch to 60Hz */
					15 00 00 00 00 00 02 2F 30
					15 00 00 00 00 00 02 6D 01
					39 00 00 00 00 00 05 35 00 00 00 01
					39 00 00 00 00 00 03 44 00 00
					39 00 00 00 28 00 03 51 00 00
				];
				qcom,mdss-dsi-hbm-off-command = [
					//39 00 00 00 00 00 03 51 0D BB
				];
				qcom,mdss-dsi-hbm-on-command = [
					39 00 00 40 00 00 06 F0 55 AA 52 08 01
					39 00 00 40 00 00 02 6F 02
					39 00 00 40 00 00 11 E5 00 00 00 00 20 20 20 00 28 28 28 00 30 30 30 00
					39 00 00 40 00 00 02 6F 24
					39 00 00 40 00 00 0D E5 00 00 00 00 20 20 20 00 28 28 28 00
					39 00 00 40 00 00 02 6F 46
					39 00 00 40 00 00 0D E5 00 00 00 00 20 20 20 00 28 28 28 00
					39 00 00 40 00 00 02 6F 03
					39 00 00 40 00 00 19 C6 37 37 37 23 23 23 23 23 23 37 37 37 23 23 23 23 23 23 37 37 37 23 23 23
					39 00 00 40 00 00 02 E5 B2
					39 00 00 40 00 00 02 6F 22
					39 00 00 40 00 00 02 E5 B2
					39 00 00 40 00 00 02 6F 44
					39 00 00 40 00 00 02 E5 B2
					39 00 00 40 00 00 06 F0 55 AA 52 08 05
					39 00 00 40 00 00 02 6F 12
					39 00 00 40 00 00 05 EC 00 00 00 00
					39 00 00 40 00 00 06 F0 55 AA 52 08 00
					39 00 00 40 00 00 02 6F 11
					39 00 00 40 00 00 04 B2 02 03 42
					39 00 00 40 00 00 2D B3 00 08 00 B4 00 B4 01 5F 01 5F 02 20 02 20 03 7C 03 7C 05 30 05 30 06 43 06 43 06 44 06 44 09 0B 09 0B 0D BB 0D BB 0F FF 0F FF 0F FF
					39 00 00 40 00 00 2F B4 00 00 00 80 00 96 00 96 00 C0 00 C0 01 26 01 26 02 8E 02 8E 05 8E 05 8E 08 26 08 26 09 40 09 40 09 40 09 40 09 40 09 40 09 40 09 40 09 40
					39 00 00 40 00 00 02 6F 2E
					39 00 00 40 00 00 2F B4 00 00 00 E2 00 FF 00 FF 01 3A 01 3A 01 CE 01 CE 03 AA 03 AA 07 9C 07 9C 0B 20 0B 20 0C 56 0C 56 0C 56 0C 56 0C 56 0C 56 0C 56 0C 56 0C 56
					39 00 00 40 00 00 02 6F 5C
					39 00 00 40 00 00 2F B4 00 00 00 78 00 8C 00 8C 00 B4 00 B4 01 26 01 26 02 8E 02 8E 05 8E 05 8E 08 26 08 26 09 40 09 40 09 40 09 40 09 40 09 40 09 40 09 40 09 40
					39 00 00 00 00 00 03 51 0F 00
				];
				qcom,mdss-dsi-hbm-on-onepulse-command = [
					39 00 00 40 00 00 06 F0 55 AA 52 08 01
					39 00 00 40 00 00 02 6F 02
					39 00 00 40 00 00 11 E5 00 00 00 00 00 00 00 00 00 00 00 00 00 00 00 00
					39 00 00 40 00 00 02 6F 24
					39 00 00 40 00 00 0D E5 00 00 00 00 20 20 20 00 28 28 28 00
					39 00 00 40 00 00 02 6F 46
					39 00 00 40 00 00 0D E5 00 00 00 00 20 20 20 00 28 28 28 00
					39 00 00 40 00 00 02 6F 03
					39 00 00 40 00 00 19 C6 1D 1D 1D 23 23 23 23 23 23 37 37 37 23 23 23 23 23 23 37 37 37 23 23 23
					39 00 00 40 00 00 02 E5 B2
					39 00 00 40 00 00 02 6F 22
					39 00 00 40 00 00 02 E5 B2
					39 00 00 40 00 00 02 6F 44
					39 00 00 40 00 00 02 E5 B2
					39 00 00 40 00 00 06 F0 55 AA 52 08 05
					39 00 00 40 00 00 02 6F 12
					39 00 00 40 00 00 05 EC 00 00 00 00
					39 00 00 40 00 00 06 F0 55 AA 52 08 00
					39 00 00 40 00 00 02 6F 11
					39 00 00 40 00 00 04 B2 00 00 40
					39 00 00 40 00 00 2D B3 00 08 00 B4 00 B4 01 5F 01 5F 02 20 02 20 03 7C 03 7C 05 30 05 30 06 43 06 43 06 44 06 44 09 0B 09 0B 0D BB 0D BB 0F FF 0F FF 0F FF
					39 00 00 40 00 00 2F B4 00 00 00 80 00 96 00 96 00 C0 00 C0 01 26 01 26 02 8E 02 8E 05 8E 05 8E 08 26 08 26 0A DE 0A DE 0A DE 0A DE 0A DE 0A DE 0A DE 0A DE 0A DE
					39 00 00 40 00 00 02 6F 2E
					39 00 00 40 00 00 2F B4 00 00 00 E2 00 FF 00 FF 01 3A 01 3A 01 CE 01 CE 03 AA 03 AA 07 9C 07 9C 0B 20 0B 20 0E 5B 0E 5B 0E 5B 0E 5B 0E 5B 0E 5B 0E 5B 0E 5B 0E 5B
					39 00 00 40 00 00 02 6F 5C
					39 00 00 40 00 00 2F B4 00 00 00 78 00 8C 00 8C 00 B4 00 B4 01 26 01 26 02 8E 02 8E 05 8E 05 8E 08 26 08 26 0A DE 0A DE 0A DE 0A DE 0A DE 0A DE 0A DE 0A DE 0A DE
					39 00 00 00 00 00 03 51 0F 00
				];
				qcom,mdss-dsi-aod-high-mode-command = [
					/* AOD 50nit */
					15 00 00 40 00 00 02 6F 04
					39 00 00 00 00 00 03 51 02 FF
				];
				qcom,mdss-dsi-aod-low-mode-command = [
					/* AOD 10nit */
					15 00 00 40 00 00 02 6F 04
					39 00 00 00 00 00 03 51 01 FF
				];
				qcom,mdss-dsi-temperature-compensation-command = [
					39 00 00 40 00 00 06 F0 55 AA 52 08 01
					39 00 00 40 00 00 02 6F 06
					39 00 00 40 00 00 05 E5 00 00 00 00
					39 00 00 40 00 00 02 6F 0A
					39 00 00 40 00 00 05 E5 00 00 00 00
					39 00 00 40 00 00 02 6F 0E
					39 00 00 40 00 00 05 E5 00 00 00 00
					39 00 00 40 00 00 02 6F 28
					39 00 00 40 00 00 05 E5 00 00 00 00
					39 00 00 40 00 00 02 6F 2C
					39 00 00 40 00 00 05 E5 00 00 00 00
					39 00 00 40 00 00 02 6F 4A
					39 00 00 40 00 00 05 E5 00 00 00 00
					39 00 00 40 00 00 02 6F 4E
					39 00 00 40 00 00 05 E5 00 00 00 00
					39 00 00 40 00 00 02 6F 52
					39 00 00 40 00 00 05 E5 00 00 00 00
					39 00 00 40 00 00 02 6F 03
					39 00 00 40 00 00 04 C6 00 00 00
					39 00 00 40 00 00 02 6F 0C
					39 00 00 40 00 00 04 C6 00 00 00
					39 00 00 40 00 00 02 6F 15
					39 00 00 40 00 00 04 C6 00 00 00
					39 00 00 40 00 00 06 F0 55 AA 52 08 05
					39 00 00 40 00 00 02 6F 12
					39 00 00 00 00 00 05 EC 00 00 00 00
				];
				/* origin 3 pulse */
				qcom,mdss-dsi-pwm-switch-high-command = [
					39 00 00 40 00 00 06 F0 55 AA 52 08 00
					39 00 00 40 00 00 02 6F 11
					39 00 00 40 00 00 04 B2 02 03 42
					39 00 00 40 00 00 2D B3 00 08 00 B4 00 B4 01 5F 01 5F 02 20 02 20 03 7C 03 7C 05 30 05 30 06 43 06 43 06 44 06 44 09 0B 09 0B 0D BB 0D BB 0F FF 0F FF 0F FF
					39 00 00 40 00 00 2F B4 00 00 00 80 00 96 00 96 00 C0 00 C0 01 26 01 26 02 8E 02 8E 05 8E 05 8E 08 26 08 26 09 40 09 40 09 40 09 40 09 40 09 40 09 40 09 40 09 40
					39 00 00 40 00 00 02 6F 2E
					39 00 00 40 00 00 2F B4 00 00 00 E2 00 FF 00 FF 01 3A 01 3A 01 CE 01 CE 03 AA 03 AA 07 9C 07 9C 0B 20 0B 20 0C 56 0C 56 0C 56 0C 56 0C 56 0C 56 0C 56 0C 56 0C 56
					39 00 00 40 00 00 02 6F 5C
					39 00 00 40 00 00 2F B4 00 00 00 78 00 8C 00 8C 00 B4 00 B4 01 26 01 26 02 8E 02 8E 05 8E 05 8E 08 26 08 26 09 40 09 40 09 40 09 40 09 40 09 40 09 40 09 40 09 40
					39 00 00 00 00 00 03 51 06 44
				];
				qcom,mdss-dsi-pwm-switch-low-command = [
					39 00 00 40 00 00 06 F0 55 AA 52 08 00
					39 00 00 40 00 00 02 6F 11
					39 00 00 40 00 00 04 B2 0F 17 4E
					39 00 00 40 00 00 2D B3 00 08 00 B4 00 B4 01 5F 01 5F 02 20 02 20 03 7C 03 7C 05 30 05 30 06 43 06 43 06 44 06 44 09 0B 09 0B 0D BB 0D BB 0F FF 0F FF 0F FF
					39 00 00 40 00 00 2F B4 00 00 00 80 00 96 00 96 00 C0 00 C0 01 26 01 26 02 8E 02 8E 05 8E 05 8E 08 26 08 26 09 40 09 40 09 40 09 40 09 40 09 40 09 40 09 40 09 40
					39 00 00 40 00 00 02 6F 2E
					39 00 00 40 00 00 2F B4 00 00 00 E2 00 FF 00 FF 01 3A 01 3A 01 CE 01 CE 03 AA 03 AA 07 9C 07 9C 0B 20 0B 20 0C 56 0C 56 0C 56 0C 56 0C 56 0C 56 0C 56 0C 56 0C 56
					39 00 00 40 00 00 02 6F 5C
					39 00 00 40 00 00 2F B4 00 00 00 78 00 8C 00 8C 00 B4 00 B4 01 26 01 26 02 8E 02 8E 05 8E 05 8E 08 26 08 26 09 40 09 40 09 40 09 40 09 40 09 40 09 40 09 40 09 40
					39 00 00 00 00 00 03 51 06 43

				];
				/* origin 3 pulse */
				qcom,mdss-dsi-timming-pwm-switch-high-command = [
					39 00 00 40 00 00 06 F0 55 AA 52 08 00
					39 00 00 40 00 00 02 6F 11
					39 00 00 40 00 00 04 B2 02 03 42
					39 00 00 40 00 00 2D B3 00 08 00 B4 00 B4 01 5F 01 5F 02 20 02 20 03 7C 03 7C 05 30 05 30 06 43 06 43 06 44 06 44 09 0B 09 0B 0D BB 0D BB 0F FF 0F FF 0F FF
					39 00 00 40 00 00 2F B4 00 00 00 80 00 96 00 96 00 C0 00 C0 01 26 01 26 02 8E 02 8E 05 8E 05 8E 08 26 08 26 09 40 09 40 09 40 09 40 09 40 09 40 09 40 09 40 09 40
					39 00 00 40 00 00 02 6F 2E
					39 00 00 40 00 00 2F B4 00 00 00 E2 00 FF 00 FF 01 3A 01 3A 01 CE 01 CE 03 AA 03 AA 07 9C 07 9C 0B 20 0B 20 0C 56 0C 56 0C 56 0C 56 0C 56 0C 56 0C 56 0C 56 0C 56
					39 00 00 40 00 00 02 6F 5C
					39 00 00 00 00 00 2F B4 00 00 00 78 00 8C 00 8C 00 B4 00 B4 01 26 01 26 02 8E 02 8E 05 8E 05 8E 08 26 08 26 09 40 09 40 09 40 09 40 09 40 09 40 09 40 09 40 09 40
				];
				qcom,mdss-dsi-timming-pwm-switch-low-command = [
					39 00 00 40 00 00 06 F0 55 AA 52 08 00
					39 00 00 40 00 00 02 6F 11
					39 00 00 40 00 00 04 B2 0F 17 4E
					39 00 00 40 00 00 2D B3 00 08 00 B4 00 B4 01 5F 01 5F 02 20 02 20 03 7C 03 7C 05 30 05 30 06 43 06 43 06 44 06 44 09 0B 09 0B 0D BB 0D BB 0F FF 0F FF 0F FF
					39 00 00 40 00 00 2F B4 00 00 00 80 00 96 00 96 00 C0 00 C0 01 26 01 26 02 8E 02 8E 05 8E 05 8E 08 26 08 26 09 40 09 40 09 40 09 40 09 40 09 40 09 40 09 40 09 40
					39 00 00 40 00 00 02 6F 2E
					39 00 00 40 00 00 2F B4 00 00 00 E2 00 FF 00 FF 01 3A 01 3A 01 CE 01 CE 03 AA 03 AA 07 9C 07 9C 0B 20 0B 20 0C 56 0C 56 0C 56 0C 56 0C 56 0C 56 0C 56 0C 56 0C 56
					39 00 00 40 00 00 02 6F 5C
					39 00 00 00 00 00 2F B4 00 00 00 78 00 8C 00 8C 00 B4 00 B4 01 26 01 26 02 8E 02 8E 05 8E 05 8E 08 26 08 26 09 40 09 40 09 40 09 40 09 40 09 40 09 40 09 40 09 40
				];
				qcom,mdss-dsi-pwm-switch-onepulse-command = [
					39 00 00 40 00 00 06 F0 55 AA 52 08 00
					39 00 00 40 00 00 02 6F 11
					39 00 00 40 00 00 04 B2 00 00 40
					39 00 00 40 00 00 2D B3 00 08 00 B4 00 B4 01 5F 01 5F 02 20 02 20 03 7C 03 7C 05 30 05 30 06 43 06 43 06 44 06 44 09 0B 09 0B 0D BB 0D BB 0F FF 0F FF 0F FF
					39 00 00 40 00 00 2F B4 00 00 00 80 00 96 00 96 00 C0 00 C0 01 26 01 26 02 8E 02 8E 05 8E 05 8E 08 26 08 26 0A DE 0A DE 0A DE 0A DE 0A DE 0A DE 0A DE 0A DE 0A DE
					39 00 00 40 00 00 02 6F 2E
					39 00 00 40 00 00 2F B4 00 00 00 E2 00 FF 00 FF 01 3A 01 3A 01 CE 01 CE 03 AA 03 AA 07 9C 07 9C 0B 20 0B 20 0E 5B 0E 5B 0E 5B 0E 5B 0E 5B 0E 5B 0E 5B 0E 5B 0E 5B
					39 00 00 40 00 00 02 6F 5C
					39 00 00 40 00 00 2F B4 00 00 00 78 00 8C 00 8C 00 B4 00 B4 01 26 01 26 02 8E 02 8E 05 8E 05 8E 08 26 08 26 0A DE 0A DE 0A DE 0A DE 0A DE 0A DE 0A DE 0A DE 0A DE
					39 00 00 00 00 00 03 51 06 44
				];
				qcom,mdss-dsi-timming-pwm-switch-onepulse-command = [
					39 00 00 40 00 00 06 F0 55 AA 52 08 00
					39 00 00 40 00 00 02 6F 11
					39 00 00 40 00 00 04 B2 00 00 40
					39 00 00 40 00 00 2D B3 00 08 00 B4 00 B4 01 5F 01 5F 02 20 02 20 03 7C 03 7C 05 30 05 30 06 43 06 43 06 44 06 44 09 0B 09 0B 0D BB 0D BB 0F FF 0F FF 0F FF
					39 00 00 40 00 00 2F B4 00 00 00 80 00 96 00 96 00 C0 00 C0 01 26 01 26 02 8E 02 8E 05 8E 05 8E 08 26 08 26 0A DE 0A DE 0A DE 0A DE 0A DE 0A DE 0A DE 0A DE 0A DE
					39 00 00 40 00 00 02 6F 2E
					39 00 00 40 00 00 2F B4 00 00 00 E2 00 FF 00 FF 01 3A 01 3A 01 CE 01 CE 03 AA 03 AA 07 9C 07 9C 0B 20 0B 20 0E 5B 0E 5B 0E 5B 0E 5B 0E 5B 0E 5B 0E 5B 0E 5B 0E 5B
					39 00 00 40 00 00 02 6F 5C
					39 00 00 00 00 00 2F B4 00 00 00 78 00 8C 00 8C 00 B4 00 B4 01 26 01 26 02 8E 02 8E 05 8E 05 8E 08 26 08 26 0A DE 0A DE 0A DE 0A DE 0A DE 0A DE 0A DE 0A DE 0A DE
				];
				qcom,mdss-dsi-pwm-switch-threepulse-command = [
					39 00 00 40 00 00 06 F0 55 AA 52 08 00
					39 00 00 40 00 00 02 6F 11
					39 00 00 40 00 00 04 B2 02 03 42
					39 00 00 40 00 00 2D B3 00 08 00 B4 00 B4 01 5F 01 5F 02 20 02 20 03 7C 03 7C 05 30 05 30 06 43 06 43 06 44 06 44 09 0B 09 0B 0D BB 0D BB 0F FF 0F FF 0F FF
					39 00 00 40 00 00 2F B4 00 00 00 80 00 96 00 96 00 C0 00 C0 01 26 01 26 02 8E 02 8E 05 8E 05 8E 08 26 08 26 09 40 09 40 09 40 09 40 09 40 09 40 09 40 09 40 09 40
					39 00 00 40 00 00 02 6F 2E
					39 00 00 40 00 00 2F B4 00 00 00 E2 00 FF 00 FF 01 3A 01 3A 01 CE 01 CE 03 AA 03 AA 07 9C 07 9C 0B 20 0B 20 0C 56 0C 56 0C 56 0C 56 0C 56 0C 56 0C 56 0C 56 0C 56
					39 00 00 40 00 00 02 6F 5C
					39 00 00 00 00 00 2F B4 00 00 00 78 00 8C 00 8C 00 B4 00 B4 01 26 01 26 02 8E 02 8E 05 8E 05 8E 08 26 08 26 09 40 09 40 09 40 09 40 09 40 09 40 09 40 09 40 09 40
				];
				qcom,mdss-dsi-timing-switch-command-state = "dsi_hs_mode";
				qcom,mdss-dsi-on-command-state = "dsi_lp_mode";
				qcom,mdss-dsi-off-command-state = "dsi_hs_mode";
				qcom,mdss-dsi-hbm-on-command-state = "dsi_lp_mode";
				qcom,mdss-dsi-hbm-on-onepulse-command-state = "dsi_lp_mode";
				qcom,mdss-dsi-hbm-off-command-state = "dsi_lp_mode";
				qcom,mdss-dsi-skipframe-dbv-command-state = "dsi_hs_mode";
				qcom,mdss-dsi-adfr-auto-on-command-state ="dsi_hs_mode";
				qcom,mdss-dsi-adfr-auto-off-command-state ="dsi_hs_mode";
				qcom,mdss-dsi-adfr-min-fps-0-command-state = "dsi_hs_mode";
				qcom,mdss-dsi-adfr-min-fps-1-command-state = "dsi_hs_mode";
				qcom,mdss-dsi-bl-demua1-command-state = "dsi_hs_mode";
				qcom,mdss-dsi-bl-demua2-command-state = "dsi_hs_mode";
				qcom,mdss-dsi-bl-demua3-command-state = "dsi_hs_mode";
				qcom,mdss-dsi-bl-demua4-command-state = "dsi_hs_mode";
				qcom,mdss-dsi-bl-demua5-command-state = "dsi_hs_mode";
				qcom,mdss-dsi-bl-demua6-command-state = "dsi_hs_mode";
				qcom,mdss-dsi-panel-info-switch-page-command-state = "dsi_lp_mode";
				qcom,mdss-dsi-default-switch-page-command-state = "dsi_lp_mode";
				qcom,mdss-dsi-pwm-switch-high-command-state = "dsi_hs_mode";
				qcom,mdss-dsi-pwm-switch-low-command-state = "dsi_hs_mode";
				qcom,mdss-dsi-timming-pwm-switch-high-command-state = "dsi_hs_mode";
				qcom,mdss-dsi-timming-pwm-switch-low-command-state = "dsi_hs_mode";
				qcom,mdss-dsi-pwm-switch-onepulse-command-state = "dsi_hs_mode";
				qcom,mdss-dsi-timming-pwm-switch-onepulse-command-state = "dsi_hs_mode";
				qcom,mdss-dsi-pwm-switch-threepulse-command-state = "dsi_hs_mode";

				qcom,lm-split = <620 620>;
				qcom,compression-mode = "dsc";
				qcom,mdss-dsc-encoders = <2>;
				qcom,mdss-dsc-slice-height = <12>;
				qcom,mdss-dsc-slice-width = <620>;
				qcom,mdss-dsc-slice-per-pkt = <2>;
				qcom,mdss-dsc-bit-per-component = <10>;
				qcom,mdss-dsc-bit-per-pixel = <8>;
				qcom,mdss-dsc-block-prediction-enable;
			};
			timing@sa_fhd_144{
				qcom,mdss-mdp-transfer-time-us = <6000>;
				qcom,mdss-mdp-transfer-time-us-min = <6000>;
				qcom,mdss-mdp-transfer-time-us-max = <6000>;
				qcom,mdss-dsi-panel-jitter = <0x4 0x1>;
				qcom,mdss-dsc-scr-version = <0x1>;
				qcom,mdss-dsc-version = <0x11>;
				qcom,mdss-dsi-panel-framerate = <144>;
				qcom,mdss-dsi-panel-clockrate = <1363200000>;
				qcom,mdss-dsi-panel-width = <1240>;
				qcom,mdss-dsi-panel-height = <2772>;

				qcom,mdss-dsi-h-front-porch = <64>;
				qcom,mdss-dsi-h-back-porch = <48>;
				qcom,mdss-dsi-h-pulse-width = <8>;
				qcom,mdss-dsi-v-back-porch = <8>;
				qcom,mdss-dsi-v-front-porch = <2>;
				qcom,mdss-dsi-v-pulse-width = <2>;
				qcom,mdss-dsi-h-sync-pulse = <0>;

				qcom,mdss-dsi-h-left-border = <0>;
				qcom,mdss-dsi-h-right-border = <0>;
				qcom,mdss-dsi-v-top-border = <0>;
				qcom,mdss-dsi-v-bottom-border = <0>;

				/* Apollo vsync config, need to measure TE signal */
				//oplus,apollo-panel-vsync-width = <13000>;
				//oplus,apollo-panel-vsync-period = <16600>;
				/* standard adfr */
				qcom,mdss-dsi-h-sync-skew = <0>;
				oplus,adfr-min-fps-mapping-table = <144 72>;

				qcom,mdss-dsi-panel-vsync-source = <1>;
				qcom,mdss-dsi-qsync-min-fps-0 = <1314>;
				oplus,fod-on-vblank = <0>;
				oplus,fod-off-vblank = <0>;
				oplus,ofp-need-to-filter-backlight-dim-icon;
				qcom,mdss-dsi-bl-demua1-command = [
					/* 51hex > 0x644 */
					39 00 00 50 00 00 06 F0 55 AA 52 08 04
					39 00 00 50 00 00 02 6F 02
					39 00 00 50 00 00 03 EC 01 03
					39 00 00 50 00 00 02 6F A5
					39 00 00 10 00 00 07 EC 01 01 01 03 03 03
				];
				qcom,mdss-dsi-bl-demua2-command = [
					/* 0x644>51hex>=0x530 */
					39 00 00 50 00 00 06 F0 55 AA 52 08 04
					39 00 00 50 00 00 02 6F 02
					39 00 00 50 00 00 03 EC 03 0B
					39 00 00 50 00 00 02 6F A5
					39 00 00 10 00 00 07 EC 03 03 03 0B 0B 0B
				];
				qcom,mdss-dsi-bl-demua3-command = [
					/* 0x530>51hex>=0x33A */
					39 00 00 50 00 00 06 F0 55 AA 52 08 04
					39 00 00 50 00 00 02 6F 02
					39 00 00 50 00 00 03 EC 10 18
					39 00 00 50 00 00 02 6F A5
					39 00 00 10 00 00 07 EC 10 10 10 18 18 18
				];
				qcom,mdss-dsi-bl-demua4-command = [
					/* 0x339>51hex>=0x25C */
					39 00 00 50 00 00 06 F0 55 AA 52 08 04
					39 00 00 50 00 00 02 6F 02
					39 00 00 50 00 00 03 EC 15 1D
					39 00 00 50 00 00 02 6F A5
					39 00 00 10 00 00 07 EC 15 15 15 1D 1D 1D
				];
				qcom,mdss-dsi-bl-demua5-command = [
					/* 0x25C>51hex>=0x196 */
					39 00 00 50 00 00 06 F0 55 AA 52 08 04
					39 00 00 50 00 00 02 6F 02
					39 00 00 50 00 00 03 EC 15 2D
					39 00 00 50 00 00 02 6F A5
					39 00 00 10 00 00 07 EC 15 15 15 2D 2D 2D
				];
				qcom,mdss-dsi-bl-demua6-command = [
					/* 0x196>51hex>=0x008 */
					39 00 00 50 00 00 06 F0 55 AA 52 08 04
					39 00 00 50 00 00 02 6F 02
					39 00 00 50 00 00 03 EC 15 4D
					39 00 00 50 00 00 02 6F A5
					39 00 00 10 00 00 07 EC 15 15 15 4D 4D 4D
				];
				qcom,mdss-dsi-skipframe-dbv-command = [
					39 00 00 40 00 00 06 F0 55 AA 52 08 01
					39 00 00 40 00 00 02 6F 02
					39 00 00 40 00 00 11 E5 00 00 00 00 00 00 00 00 00 00 00 00 00 00 00 00
					39 00 00 40 00 00 02 6F 24
					39 00 00 40 00 00 0D E5 00 00 00 00 00 00 00 00 00 00 00 00
					39 00 00 40 00 00 02 6F 46
					39 00 00 40 00 00 0D E5 00 00 00 00 00 00 00 00 00 00 00 00
					39 00 00 40 00 00 02 6F 03
					39 00 00 40 00 00 19 C6 1B 1B 24 23 23 23 23 23 23 1D 1D 25 23 23 23 23 23 23 1B 1B 24 23 23 23
					39 00 00 40 00 00 02 E5 B2
					39 00 00 40 00 00 02 6F 22
					39 00 00 40 00 00 02 E5 B2
					39 00 00 40 00 00 02 6F 44
					39 00 00 40 00 00 02 E5 B2
					39 00 00 40 00 00 06 F0 55 AA 52 08 05
					39 00 00 40 00 00 02 6F 12
					39 00 00 00 00 00 05 EC 00 00 00 00
					];
				qcom,mdss-dsi-timing-switch-command = [
					/* switch  to 120*/
					39 00 00 40 00 00 06 F0 55 AA 52 08 00
					39 00 00 00 0C 00 02 2F 00
					39 00 00 40 00 00 02 BE 47
					39 00 00 40 00 00 02 6F A8
					39 00 00 40 00 00 03 BA 00 00
					39 00 00 40 00 00 02 6F B0
					39 00 00 40 00 00 05 BA 00 00 00 00
					39 00 00 40 00 00 02 2F 30
					39 00 00 40 00 00 02 6D 00
					39 00 00 00 00 00 05 35 00 00 00 00
					/* switch */
					39 00 00 40 00 00 06 F0 55 AA 52 08 00
					39 00 00 00 0A 00 02 2F 02
					39 00 00 40 00 00 02 BE 47
					39 00 00 40 00 00 02 6F A8
					39 00 00 40 00 00 03 BA 22 22
					39 00 00 40 00 00 02 6F B0
					39 00 00 40 00 00 05 BA 22 22 00 00
					39 00 00 40 00 00 02 2F 32
					39 00 00 40 00 00 02 6D 00
					39 00 00 00 00 00 05 35 00 00 00 00
					];
				qcom,mdss-dsi-on-command=[
					/* Optimize edge green */
					39 00 00 40 00 00 06 F0 55 AA 52 08 07
					39 00 00 40 00 00 0E B4 C0 80 80 80 80 50 80 80 80 80 80 50 80
					/* Vsync Hsync output */
					39 00 00 40 00 00 06 F0 55 AA 52 08 00
					39 00 00 40 00 00 02 6F 02
					39 00 00 00 00 00 03 BE 49 4C
					/* AVDD=7.9 */
					39 00 00 40 00 00 06 F0 55 AA 52 08 00
					39 00 00 40 00 00 02 6F 07
					39 00 00 40 00 00 02 B5 4E
					/* HBM L0 glows green */
					39 00 00 40 00 00 02 B5 80
					39 00 00 40 00 00 02 6F 2C
					39 00 00 00 00 00 02 B5 03
					39 00 00 40 00 00 05 FF AA 55 A5 81
					39 00 00 40 00 00 02 6F 19
					39 00 00 40 00 00 02 FB 00
					39 00 00 40 00 00 02 6F 05
					39 00 00 40 00 00 02 FE 34
					39 00 00 40 00 00 05 FF AA 55 A5 80
					39 00 00 40 00 00 02 6F 1A
					39 00 00 40 00 00 02 F4 55
					39 00 00 40 00 00 05 FF AA 55 A5 83
					39 00 00 40 00 00 02 6F 12
					39 00 00 40 00 00 02 FE 41
					39 00 00 40 00 00 02 5F 00
					39 00 00 40 00 00 02 26 00
					39 00 00 40 00 00 02 26 00
					39 00 00 40 00 00 02 17 10
					39 00 00 40 00 00 05 2A 00 00 04 D7
					39 00 00 00 00 00 05 2B 00 00 0A D3
					/* Fre 144Hz */
					39 00 00 00 00 00 02 2F 02
					/* TE ON */
					39 00 00 40 00 00 02 35 00
					39 00 00 00 00 00 03 44 00 00
					/* Nor 51 */
					39 00 00 40 00 00 03 51 00 00
					39 00 00 00 00 00 02 6F 04
					/* AOD 51 */
					39 00 00 40 00 00 03 51 00 00
					39 00 00 40 00 00 02 53 20
					39 00 00 00 00 00 03 90 03 03
					/* 10bit DSC */
					39 00 00 40 00 00 13 91 AB 28 00 0C F2 00 02 85 01 0F 00 08 0A E9 07 5F 10 F0
					39 00 00 40 00 00 05 FF AA 55 A5 81
					39 00 00 40 00 00 02 6F 24
					39 00 00 40 00 00 15 FB 00 03 04 55 77 77 77 99 9D 00 00 06 88 9A BB BC DE EF F0 11
					39 00 00 40 00 00 05 FF AA 55 A5 81
					39 00 00 40 00 00 02 6F 0E
					39 00 00 40 00 00 02 F5 00
					39 00 00 40 00 00 05 FF AA 55 A5 80
					39 00 00 40 00 00 02 6F 0F
					39 00 00 40 00 00 02 FC 00
					39 00 00 40 00 00 02 6F 09
					39 00 00 40 00 00 03 FC FC F0
					39 00 00 40 00 00 05 FF AA 55 A5 80
					39 00 00 40 00 00 02 6F 0A
					39 00 00 40 00 00 04 F6 70 70 70
					39 00 00 40 00 00 02 6F 0E
					39 00 00 00 00 00 02 F6 60
					/* OSC start */
					39 00 00 40 00 00 05 FF AA 55 A5 80
					39 00 00 40 00 00 02 6F 11
					/* OSC2 145Mhz */
					39 00 00 40 00 00 03 F8 01 8E
					39 00 00 40 00 00 02 6F 2D
					/* OSC1 121.9Mhz */
					39 00 00 40 00 00 03 F8 00 FC
					39 00 00 40 00 00 02 6F 01
					39 00 00 40 00 00 02 1F 06
					39 00 00 40 00 00 05 FF AA 55 A5 81
					39 00 00 40 00 00 02 6F 1E
					39 00 00 00 00 00 02 FB 0F
					/* OSC end */
					39 00 00 40 00 00 05 FF AA 55 A5 83
					39 00 00 40 00 00 02 6F 12
					39 00 00 40 00 00 02 FE 41
					39 00 00 40 00 00 05 FF AA 55 A5 80
					39 00 00 40 00 00 02 6F 19
					39 00 00 40 00 00 02 F2 00
					39 00 00 40 00 00 05 FF AA 55 A5 81
					39 00 00 40 00 00 02 6F 02
					39 00 00 40 00 00 02 F9 04
					39 00 00 40 00 00 02 5A 00
					/* AOD remove black frame */
					39 00 00 00 00 00 06 F0 55 AA 52 08 01
					39 00 00 00 00 00 06 D2 00 00 00 00 15
					15 00 00 00 00 00 02 6F 05
					39 00 00 00 00 00 04 D2 01 00 00
					15 00 00 00 00 00 02 6F 0E
					39 00 00 00 00 00 06 D2 02 00 10 05 88
					39 00 00 00 00 00 0B E4 80 00 00 00 00 00 00 00 00 33
					15 00 00 00 00 00 02 6F 0A
					39 00 00 00 00 00 07 E4 80 00 00 10 00 53
					/* AOD off splash */
					39 00 00 40 00 00 06 F0 55 AA 52 08 01
					39 00 00 40 00 00 02 6F 0E
					39 00 00 00 00 00 06 D2 02 00 10 05 82
					/* OSC Tracking */
					39 00 00 40 00 00 06 F0 55 AA 52 08 01
					39 00 00 00 00 00 2A C3 DD 06 22 15 F9 00 06 20 15 FF 00 03 E7 16 06 2B 1D 03 E7 16 06 2B 1D 03 E7 16 06 2B 1D 03 E7 16 06 2B 1D 03 E7 16 06 2B 1D
					/* 11H sleep out */
					39 00 00 00 78 00 02 11 00
					39 00 00 40 00 00 06 F0 55 AA 52 08 00
					39 00 00 00 08 00 02 2F 02
					39 00 00 40 00 00 02 BE 47
					39 00 00 40 00 00 02 6F A8
					39 00 00 40 00 00 03 BA 22 22
					39 00 00 40 00 00 02 6F B0
					39 00 00 40 00 00 05 BA 22 22 00 00
					39 00 00 40 00 00 02 2F 32
					39 00 00 40 00 00 02 6D 00
					39 00 00 00 00 00 05 35 00 00 00 00
					05 00 00 00 00 00 01 29
				];

				qcom,mdss-dsi-panel-info-switch-page-command = [
					/*read panel info switch page 01*/
					39 00 00 00 00 00 06 F0 55 AA 52 08 01
				];
				qcom,mdss-dsi-default-switch-page-command = [
					/*switch default page*/
					39 00 00 00 00 00 06 F0 55 AA 52 08 00
				];

				qcom,mdss-dsi-qsync-on-commands = [
					/* SDC Auto On */
				];
				qcom,mdss-dsi-qsync-off-commands = [
					/* SDC Auto Off */
				];
				qcom,mdss-dsi-adfr-auto-on-command = [
					/* SDC Auto On */
				];
				qcom,mdss-dsi-adfr-auto-off-command = [
					/* SDC Auto Off */
				];
				qcom,mdss-dsi-adfr-min-fps-0-command = [
					15 00 00 40 00 00 02 2F 02
					15 00 00 40 00 00 02 2F 32
					15 00 00 00 00 00 02 6D 00
				];
				qcom,mdss-dsi-adfr-min-fps-1-command = [
					15 00 00 40 00 00 02 2F 02
					15 00 00 40 00 00 02 2F 32
					15 00 00 00 00 00 02 6D 01
				];

				qcom,mdss-dsi-post-on-backlight = [
					/* Display On */
					05 00 00 00 00 00 01 29
				];
				qcom,mdss-dsi-off-command=[
					05 00 00 00 0A 00 01 28
					05 00 00 00 78 00 01 10
				];
				qcom,mdss-dsi-lp1-command = [
					/* AOD Mode ON Setting */
					39 00 00 00 00 00 06 F0 55 AA 52 08 00
					15 00 00 00 00 00 02 6F 0C
					39 00 00 00 00 00 03 B5 50 4B
					39 00 00 00 00 00 05 35 00 00 00 00
					39 00 00 00 00 00 03 44 00 00
					15 00 00 00 10 00 02 2F 00
					05 00 00 00 00 00 01 39
					15 00 00 00 00 00 02 65 01
					15 00 00 00 00 00 02 6F 04
					39 00 00 00 00 00 03 51 02 FF
				];
				qcom,mdss-dsi-nolp-command = [
					/* AOD OFF */
					39 00 00 00 00 00 06 F0 55 AA 52 08 00
					15 00 00 00 00 00 02 6F 0C
					39 00 00 00 00 00 03 B5 4F 4B
					15 00 00 00 00 00 02 65 00
					05 00 00 00 00 00 01 38
					15 00 00 00 00 00 02 2F 32
					15 00 00 00 00 00 02 6D 00
					39 00 00 00 00 00 05 35 00 00 00 00
					39 00 00 00 00 00 03 44 00 00
					39 00 00 00 28 00 03 51 00 00
				];
				qcom,mdss-dsi-hbm-off-command = [
					//39 00 00 00 00 00 03 51 0D BB
				];
				qcom,mdss-dsi-hbm-on-command = [
					39 00 00 40 00 00 06 F0 55 AA 52 08 01
					39 00 00 40 00 00 02 6F 02
					39 00 00 40 00 00 11 E5 00 00 00 00 20 20 20 00 28 28 28 00 30 30 30 00
					39 00 00 40 00 00 02 6F 24
					39 00 00 40 00 00 0D E5 00 00 00 00 20 20 20 00 28 28 28 00
					39 00 00 40 00 00 02 6F 46
					39 00 00 40 00 00 0D E5 00 00 00 00 20 20 20 00 28 28 28 00
					39 00 00 40 00 00 02 6F 03
					39 00 00 40 00 00 19 C6 37 37 37 23 23 23 23 23 23 37 37 37 23 23 23 23 23 23 37 37 37 23 23 23
					39 00 00 40 00 00 02 E5 B2
					39 00 00 40 00 00 02 6F 22
					39 00 00 40 00 00 02 E5 B2
					39 00 00 40 00 00 02 6F 44
					39 00 00 40 00 00 02 E5 B2
					39 00 00 40 00 00 06 F0 55 AA 52 08 05
					39 00 00 40 00 00 02 6F 12
					39 00 00 40 00 00 05 EC 00 00 00 00
					39 00 00 40 00 00 06 F0 55 AA 52 08 00
					39 00 00 40 00 00 02 6F 11
					39 00 00 40 00 00 04 B2 02 03 42
					39 00 00 40 00 00 2D B3 00 08 00 B4 00 B4 01 5F 01 5F 02 20 02 20 03 7C 03 7C 05 30 05 30 06 43 06 43 06 44 06 44 09 0B 09 0B 0D BB 0D BB 0F FF 0F FF 0F FF
					39 00 00 40 00 00 2F B4 00 00 00 80 00 96 00 96 00 C0 00 C0 01 26 01 26 02 8E 02 8E 05 8E 05 8E 08 26 08 26 09 40 09 40 09 40 09 40 09 40 09 40 09 40 09 40 09 40
					39 00 00 40 00 00 02 6F 2E
					39 00 00 40 00 00 2F B4 00 00 00 E2 00 FF 00 FF 01 3A 01 3A 01 CE 01 CE 03 AA 03 AA 07 9C 07 9C 0B 20 0B 20 0C 56 0C 56 0C 56 0C 56 0C 56 0C 56 0C 56 0C 56 0C 56
					39 00 00 40 00 00 02 6F 5C
					39 00 00 40 00 00 2F B4 00 00 00 78 00 8C 00 8C 00 B4 00 B4 01 26 01 26 02 8E 02 8E 05 8E 05 8E 08 26 08 26 09 40 09 40 09 40 09 40 09 40 09 40 09 40 09 40 09 40
					39 00 00 00 00 00 03 51 0F 00
				];
				qcom,mdss-dsi-hbm-on-onepulse-command = [
					39 00 00 40 00 00 06 F0 55 AA 52 08 01
					39 00 00 40 00 00 02 6F 02
					39 00 00 40 00 00 11 E5 00 00 00 00 00 00 00 00 00 00 00 00 00 00 00 00
					39 00 00 40 00 00 02 6F 24
					39 00 00 40 00 00 0D E5 00 00 00 00 20 20 20 00 28 28 28 00
					39 00 00 40 00 00 02 6F 46
					39 00 00 40 00 00 0D E5 00 00 00 00 20 20 20 00 28 28 28 00
					39 00 00 40 00 00 02 6F 03
					39 00 00 40 00 00 19 C6 1D 1D 1D 23 23 23 23 23 23 37 37 37 23 23 23 23 23 23 37 37 37 23 23 23
					39 00 00 40 00 00 02 E5 B2
					39 00 00 40 00 00 02 6F 22
					39 00 00 40 00 00 02 E5 B2
					39 00 00 40 00 00 02 6F 44
					39 00 00 40 00 00 02 E5 B2
					39 00 00 40 00 00 06 F0 55 AA 52 08 05
					39 00 00 40 00 00 02 6F 12
					39 00 00 40 00 00 05 EC 00 00 00 00
					39 00 00 40 00 00 06 F0 55 AA 52 08 00
					39 00 00 40 00 00 02 6F 11
					39 00 00 40 00 00 04 B2 00 00 40
					39 00 00 40 00 00 2D B3 00 08 00 B4 00 B4 01 5F 01 5F 02 20 02 20 03 7C 03 7C 05 30 05 30 06 43 06 43 06 44 06 44 09 0B 09 0B 0D BB 0D BB 0F FF 0F FF 0F FF
					39 00 00 40 00 00 2F B4 00 00 00 80 00 96 00 96 00 C0 00 C0 01 26 01 26 02 8E 02 8E 05 8E 05 8E 08 26 08 26 0A DE 0A DE 0A DE 0A DE 0A DE 0A DE 0A DE 0A DE 0A DE
					39 00 00 40 00 00 02 6F 2E
					39 00 00 40 00 00 2F B4 00 00 00 E2 00 FF 00 FF 01 3A 01 3A 01 CE 01 CE 03 AA 03 AA 07 9C 07 9C 0B 20 0B 20 0E 5B 0E 5B 0E 5B 0E 5B 0E 5B 0E 5B 0E 5B 0E 5B 0E 5B
					39 00 00 40 00 00 02 6F 5C
					39 00 00 40 00 00 2F B4 00 00 00 78 00 8C 00 8C 00 B4 00 B4 01 26 01 26 02 8E 02 8E 05 8E 05 8E 08 26 08 26 0A DE 0A DE 0A DE 0A DE 0A DE 0A DE 0A DE 0A DE 0A DE
					39 00 00 00 00 00 03 51 0F 00
				];
				qcom,mdss-dsi-aod-high-mode-command = [
					/* AOD 50nit */
					15 00 00 40 00 00 02 6F 04
					39 00 00 00 00 00 03 51 02 FF
				];
				qcom,mdss-dsi-aod-low-mode-command = [
					/* AOD 10nit */
					15 00 00 40 00 00 02 6F 04
					39 00 00 00 00 00 03 51 01 FF
				];
				qcom,mdss-dsi-temperature-compensation-command = [
					39 00 00 40 00 00 06 F0 55 AA 52 08 01
					39 00 00 40 00 00 02 6F 06
					39 00 00 40 00 00 05 E5 00 00 00 00
					39 00 00 40 00 00 02 6F 0A
					39 00 00 40 00 00 05 E5 00 00 00 00
					39 00 00 40 00 00 02 6F 0E
					39 00 00 40 00 00 05 E5 00 00 00 00
					39 00 00 40 00 00 02 6F 28
					39 00 00 40 00 00 05 E5 00 00 00 00
					39 00 00 40 00 00 02 6F 2C
					39 00 00 40 00 00 05 E5 00 00 00 00
					39 00 00 40 00 00 02 6F 4A
					39 00 00 40 00 00 05 E5 00 00 00 00
					39 00 00 40 00 00 02 6F 4E
					39 00 00 40 00 00 05 E5 00 00 00 00
					39 00 00 40 00 00 02 6F 52
					39 00 00 40 00 00 05 E5 00 00 00 00
					39 00 00 40 00 00 02 6F 03
					39 00 00 40 00 00 04 C6 00 00 00
					39 00 00 40 00 00 02 6F 0C
					39 00 00 40 00 00 04 C6 00 00 00
					39 00 00 40 00 00 02 6F 15
					39 00 00 40 00 00 04 C6 00 00 00
					39 00 00 40 00 00 06 F0 55 AA 52 08 05
					39 00 00 40 00 00 02 6F 12
					39 00 00 00 00 00 05 EC 00 00 00 00
				];
				/* origin 3 pulse */
				qcom,mdss-dsi-pwm-switch-high-command = [
					39 00 00 40 00 00 06 F0 55 AA 52 08 00
					39 00 00 40 00 00 02 6F 11
					39 00 00 40 00 00 04 B2 02 03 42
					39 00 00 40 00 00 2D B3 00 08 00 B4 00 B4 01 5F 01 5F 02 20 02 20 03 7C 03 7C 05 30 05 30 06 43 06 43 06 44 06 44 09 0B 09 0B 0D BB 0D BB 0F FF 0F FF 0F FF
					39 00 00 40 00 00 2F B4 00 00 00 80 00 96 00 96 00 C0 00 C0 01 26 01 26 02 8E 02 8E 05 8E 05 8E 08 26 08 26 09 40 09 40 09 40 09 40 09 40 09 40 09 40 09 40 09 40
					39 00 00 40 00 00 02 6F 2E
					39 00 00 40 00 00 2F B4 00 00 00 E2 00 FF 00 FF 01 3A 01 3A 01 CE 01 CE 03 AA 03 AA 07 9C 07 9C 0B 20 0B 20 0C 56 0C 56 0C 56 0C 56 0C 56 0C 56 0C 56 0C 56 0C 56
					39 00 00 40 00 00 02 6F 5C
					39 00 00 40 00 00 2F B4 00 00 00 78 00 8C 00 8C 00 B4 00 B4 01 26 01 26 02 8E 02 8E 05 8E 05 8E 08 26 08 26 09 40 09 40 09 40 09 40 09 40 09 40 09 40 09 40 09 40
					39 00 00 00 00 00 03 51 06 44
				];
				qcom,mdss-dsi-pwm-switch-low-command = [
					39 00 00 40 00 00 06 F0 55 AA 52 08 00
					39 00 00 40 00 00 02 6F 11
					39 00 00 40 00 00 04 B2 0F 17 4E
					39 00 00 40 00 00 2D B3 00 08 00 B4 00 B4 01 5F 01 5F 02 20 02 20 03 7C 03 7C 05 30 05 30 06 43 06 43 06 44 06 44 09 0B 09 0B 0D BB 0D BB 0F FF 0F FF 0F FF
					39 00 00 40 00 00 2F B4 00 00 00 80 00 96 00 96 00 C0 00 C0 01 26 01 26 02 8E 02 8E 05 8E 05 8E 08 26 08 26 09 40 09 40 09 40 09 40 09 40 09 40 09 40 09 40 09 40
					39 00 00 40 00 00 02 6F 2E
					39 00 00 40 00 00 2F B4 00 00 00 E2 00 FF 00 FF 01 3A 01 3A 01 CE 01 CE 03 AA 03 AA 07 9C 07 9C 0B 20 0B 20 0C 56 0C 56 0C 56 0C 56 0C 56 0C 56 0C 56 0C 56 0C 56
					39 00 00 40 00 00 02 6F 5C
					39 00 00 40 00 00 2F B4 00 00 00 78 00 8C 00 8C 00 B4 00 B4 01 26 01 26 02 8E 02 8E 05 8E 05 8E 08 26 08 26 09 40 09 40 09 40 09 40 09 40 09 40 09 40 09 40 09 40
					39 00 00 00 00 00 03 51 06 43
				];
				/* origin 3 pulse */
				qcom,mdss-dsi-timming-pwm-switch-high-command = [
					39 00 00 40 00 00 06 F0 55 AA 52 08 00
					39 00 00 40 00 00 02 6F 11
					39 00 00 40 00 00 04 B2 02 03 42
					39 00 00 40 00 00 2D B3 00 08 00 B4 00 B4 01 5F 01 5F 02 20 02 20 03 7C 03 7C 05 30 05 30 06 43 06 43 06 44 06 44 09 0B 09 0B 0D BB 0D BB 0F FF 0F FF 0F FF
					39 00 00 40 00 00 2F B4 00 00 00 80 00 96 00 96 00 C0 00 C0 01 26 01 26 02 8E 02 8E 05 8E 05 8E 08 26 08 26 09 40 09 40 09 40 09 40 09 40 09 40 09 40 09 40 09 40
					39 00 00 40 00 00 02 6F 2E
					39 00 00 40 00 00 2F B4 00 00 00 E2 00 FF 00 FF 01 3A 01 3A 01 CE 01 CE 03 AA 03 AA 07 9C 07 9C 0B 20 0B 20 0C 56 0C 56 0C 56 0C 56 0C 56 0C 56 0C 56 0C 56 0C 56
					39 00 00 40 00 00 02 6F 5C
					39 00 00 00 00 00 2F B4 00 00 00 78 00 8C 00 8C 00 B4 00 B4 01 26 01 26 02 8E 02 8E 05 8E 05 8E 08 26 08 26 09 40 09 40 09 40 09 40 09 40 09 40 09 40 09 40 09 40
				];
				qcom,mdss-dsi-timming-pwm-switch-low-command = [
					39 00 00 40 00 00 06 F0 55 AA 52 08 00
					39 00 00 40 00 00 02 6F 11
					39 00 00 40 00 00 04 B2 0F 17 4E
					39 00 00 40 00 00 2D B3 00 08 00 B4 00 B4 01 5F 01 5F 02 20 02 20 03 7C 03 7C 05 30 05 30 06 43 06 43 06 44 06 44 09 0B 09 0B 0D BB 0D BB 0F FF 0F FF 0F FF
					39 00 00 40 00 00 2F B4 00 00 00 80 00 96 00 96 00 C0 00 C0 01 26 01 26 02 8E 02 8E 05 8E 05 8E 08 26 08 26 09 40 09 40 09 40 09 40 09 40 09 40 09 40 09 40 09 40
					39 00 00 40 00 00 02 6F 2E
					39 00 00 40 00 00 2F B4 00 00 00 E2 00 FF 00 FF 01 3A 01 3A 01 CE 01 CE 03 AA 03 AA 07 9C 07 9C 0B 20 0B 20 0C 56 0C 56 0C 56 0C 56 0C 56 0C 56 0C 56 0C 56 0C 56
					39 00 00 40 00 00 02 6F 5C
					39 00 00 00 00 00 2F B4 00 00 00 78 00 8C 00 8C 00 B4 00 B4 01 26 01 26 02 8E 02 8E 05 8E 05 8E 08 26 08 26 09 40 09 40 09 40 09 40 09 40 09 40 09 40 09 40 09 40
				];
				qcom,mdss-dsi-pwm-switch-onepulse-command = [
					39 00 00 40 00 00 06 F0 55 AA 52 08 00
					39 00 00 40 00 00 02 6F 11
					39 00 00 40 00 00 04 B2 00 00 40
					39 00 00 40 00 00 2D B3 00 08 00 B4 00 B4 01 5F 01 5F 02 20 02 20 03 7C 03 7C 05 30 05 30 06 43 06 43 06 44 06 44 09 0B 09 0B 0D BB 0D BB 0F FF 0F FF 0F FF
					39 00 00 40 00 00 2F B4 00 00 00 80 00 96 00 96 00 C0 00 C0 01 26 01 26 02 8E 02 8E 05 8E 05 8E 08 26 08 26 0A DE 0A DE 0A DE 0A DE 0A DE 0A DE 0A DE 0A DE 0A DE
					39 00 00 40 00 00 02 6F 2E
					39 00 00 40 00 00 2F B4 00 00 00 E2 00 FF 00 FF 01 3A 01 3A 01 CE 01 CE 03 AA 03 AA 07 9C 07 9C 0B 20 0B 20 0E 5B 0E 5B 0E 5B 0E 5B 0E 5B 0E 5B 0E 5B 0E 5B 0E 5B
					39 00 00 40 00 00 02 6F 5C
					39 00 00 40 00 00 2F B4 00 00 00 78 00 8C 00 8C 00 B4 00 B4 01 26 01 26 02 8E 02 8E 05 8E 05 8E 08 26 08 26 0A DE 0A DE 0A DE 0A DE 0A DE 0A DE 0A DE 0A DE 0A DE
					39 00 00 00 00 00 03 51 06 44
				];
				qcom,mdss-dsi-timming-pwm-switch-onepulse-command = [
					39 00 00 40 00 00 06 F0 55 AA 52 08 00
					39 00 00 40 00 00 02 6F 11
					39 00 00 40 00 00 04 B2 00 00 40
					39 00 00 40 00 00 2D B3 00 08 00 B4 00 B4 01 5F 01 5F 02 20 02 20 03 7C 03 7C 05 30 05 30 06 43 06 43 06 44 06 44 09 0B 09 0B 0D BB 0D BB 0F FF 0F FF 0F FF
					39 00 00 40 00 00 2F B4 00 00 00 80 00 96 00 96 00 C0 00 C0 01 26 01 26 02 8E 02 8E 05 8E 05 8E 08 26 08 26 0A DE 0A DE 0A DE 0A DE 0A DE 0A DE 0A DE 0A DE 0A DE
					39 00 00 40 00 00 02 6F 2E
					39 00 00 40 00 00 2F B4 00 00 00 E2 00 FF 00 FF 01 3A 01 3A 01 CE 01 CE 03 AA 03 AA 07 9C 07 9C 0B 20 0B 20 0E 5B 0E 5B 0E 5B 0E 5B 0E 5B 0E 5B 0E 5B 0E 5B 0E 5B
					39 00 00 40 00 00 02 6F 5C
					39 00 00 00 00 00 2F B4 00 00 00 78 00 8C 00 8C 00 B4 00 B4 01 26 01 26 02 8E 02 8E 05 8E 05 8E 08 26 08 26 0A DE 0A DE 0A DE 0A DE 0A DE 0A DE 0A DE 0A DE 0A DE
				];
				qcom,mdss-dsi-pwm-switch-threepulse-command = [
					39 00 00 40 00 00 06 F0 55 AA 52 08 00
					39 00 00 40 00 00 02 6F 11
					39 00 00 40 00 00 04 B2 02 03 42
					39 00 00 40 00 00 2D B3 00 08 00 B4 00 B4 01 5F 01 5F 02 20 02 20 03 7C 03 7C 05 30 05 30 06 43 06 43 06 44 06 44 09 0B 09 0B 0D BB 0D BB 0F FF 0F FF 0F FF
					39 00 00 40 00 00 2F B4 00 00 00 80 00 96 00 96 00 C0 00 C0 01 26 01 26 02 8E 02 8E 05 8E 05 8E 08 26 08 26 09 40 09 40 09 40 09 40 09 40 09 40 09 40 09 40 09 40
					39 00 00 40 00 00 02 6F 2E
					39 00 00 40 00 00 2F B4 00 00 00 E2 00 FF 00 FF 01 3A 01 3A 01 CE 01 CE 03 AA 03 AA 07 9C 07 9C 0B 20 0B 20 0C 56 0C 56 0C 56 0C 56 0C 56 0C 56 0C 56 0C 56 0C 56
					39 00 00 40 00 00 02 6F 5C
					39 00 00 00 00 00 2F B4 00 00 00 78 00 8C 00 8C 00 B4 00 B4 01 26 01 26 02 8E 02 8E 05 8E 05 8E 08 26 08 26 09 40 09 40 09 40 09 40 09 40 09 40 09 40 09 40 09 40
				];
				qcom,mdss-dsi-timing-switch-command-state = "dsi_hs_mode";
				qcom,mdss-dsi-on-command-state = "dsi_lp_mode";
				qcom,mdss-dsi-off-command-state = "dsi_hs_mode";
				qcom,mdss-dsi-hbm-on-command-state = "dsi_lp_mode";
				qcom,mdss-dsi-hbm-on-onepulse-command-state = "dsi_lp_mode";
				qcom,mdss-dsi-hbm-off-command-state = "dsi_lp_mode";
				qcom,mdss-dsi-skipframe-dbv-command-state = "dsi_hs_mode";
				qcom,mdss-dsi-adfr-auto-on-command-state ="dsi_hs_mode";
				qcom,mdss-dsi-adfr-auto-off-command-state ="dsi_hs_mode";
				qcom,mdss-dsi-adfr-min-fps-0-command-state = "dsi_hs_mode";
				qcom,mdss-dsi-adfr-min-fps-1-command-state = "dsi_hs_mode";
				qcom,mdss-dsi-bl-demua1-command-state = "dsi_hs_mode";
				qcom,mdss-dsi-bl-demua2-command-state = "dsi_hs_mode";
				qcom,mdss-dsi-bl-demua3-command-state = "dsi_hs_mode";
				qcom,mdss-dsi-bl-demua4-command-state = "dsi_hs_mode";
				qcom,mdss-dsi-bl-demua5-command-state = "dsi_hs_mode";
				qcom,mdss-dsi-bl-demua6-command-state = "dsi_hs_mode";
				qcom,mdss-dsi-panel-info-switch-page-command-state = "dsi_lp_mode";
				qcom,mdss-dsi-default-switch-page-command-state = "dsi_lp_mode";
				qcom,mdss-dsi-pwm-switch-high-command-state = "dsi_hs_mode";
				qcom,mdss-dsi-pwm-switch-low-command-state = "dsi_hs_mode";
				qcom,mdss-dsi-timming-pwm-switch-high-command-state = "dsi_hs_mode";
				qcom,mdss-dsi-timming-pwm-switch-low-command-state = "dsi_hs_mode";
				qcom,mdss-dsi-pwm-switch-onepulse-command-state = "dsi_hs_mode";
				qcom,mdss-dsi-timming-pwm-switch-onepulse-command-state = "dsi_hs_mode";
				qcom,mdss-dsi-pwm-switch-threepulse-command-state = "dsi_hs_mode";

				qcom,lm-split = <620 620>;
				qcom,compression-mode = "dsc";
				qcom,mdss-dsc-encoders = <2>;
				qcom,mdss-dsc-slice-height = <12>;
				qcom,mdss-dsc-slice-width = <620>;
				qcom,mdss-dsc-slice-per-pkt = <2>;
				qcom,mdss-dsc-bit-per-component = <10>;
				qcom,mdss-dsc-bit-per-pixel = <8>;
				qcom,mdss-dsc-block-prediction-enable;
			};
			timing@oa_fhd_120{
				qcom,mdss-mdp-transfer-time-us = <7500>;
				qcom,mdss-mdp-transfer-time-us-min = <6000>;
				qcom,mdss-mdp-transfer-time-us-max = <7500>;
				qcom,mdss-dsi-panel-jitter = <0x4 0x1>;
				qcom,mdss-dsc-scr-version = <0x1>;
				qcom,mdss-dsc-version = <0x11>;
				qcom,mdss-dsi-panel-framerate = <120>;
				qcom,mdss-dsi-panel-clockrate = <1363200000>;
				qcom,mdss-dsi-panel-width = <1240>;
				qcom,mdss-dsi-panel-height = <2772>;

				qcom,mdss-dsi-h-front-porch = <4>;
				qcom,mdss-dsi-h-back-porch = <4>;
				qcom,mdss-dsi-h-pulse-width = <4>;
				qcom,mdss-dsi-v-back-porch = <2>;
				qcom,mdss-dsi-v-front-porch = <2>;
				qcom,mdss-dsi-v-pulse-width = <2>;
				qcom,mdss-dsi-h-sync-pulse = <0>;

				qcom,mdss-dsi-h-left-border = <0>;
				qcom,mdss-dsi-h-right-border = <0>;
				qcom,mdss-dsi-v-top-border = <0>;
				qcom,mdss-dsi-v-bottom-border = <0>;

				/* Apollo vsync config, need to measure TE signal */
				//oplus,apollo-panel-vsync-width = <13000>;
				//oplus,apollo-panel-vsync-period = <16600>;

				/* oplus adfr */
				qcom,mdss-dsi-h-sync-skew = <2>;
				oplus,adfr-min-fps-mapping-table = <120 60>;

				oplus,fod-on-vblank = <0>;
				oplus,fod-off-vblank = <0>;
				oplus,ofp-need-to-filter-backlight-dim-icon;
				qcom,mdss-dsi-bl-demua1-command = [
					/* 51hex > 0x644 */
					39 00 00 50 00 00 06 F0 55 AA 52 08 04
					39 00 00 50 00 00 02 6F 02
					39 00 00 50 00 00 03 EC 01 03
					39 00 00 50 00 00 02 6F A5
					39 00 00 10 00 00 07 EC 01 01 01 03 03 03
				];
				qcom,mdss-dsi-bl-demua2-command = [
					/* 0x644>51hex>=0x530 */
					39 00 00 50 00 00 06 F0 55 AA 52 08 04
					39 00 00 50 00 00 02 6F 02
					39 00 00 50 00 00 03 EC 03 0B
					39 00 00 50 00 00 02 6F A5
					39 00 00 10 00 00 07 EC 03 03 03 0B 0B 0B
				];
				qcom,mdss-dsi-bl-demua3-command = [
					/* 0x530>51hex>=0x33A */
					39 00 00 50 00 00 06 F0 55 AA 52 08 04
					39 00 00 50 00 00 02 6F 02
					39 00 00 50 00 00 03 EC 10 18
					39 00 00 50 00 00 02 6F A5
					39 00 00 10 00 00 07 EC 10 10 10 18 18 18
				];
				qcom,mdss-dsi-bl-demua4-command = [
					/* 0x339>51hex>=0x25C */
					39 00 00 50 00 00 06 F0 55 AA 52 08 04
					39 00 00 50 00 00 02 6F 02
					39 00 00 50 00 00 03 EC 15 1D
					39 00 00 50 00 00 02 6F A5
					39 00 00 10 00 00 07 EC 15 15 15 1D 1D 1D
				];
				qcom,mdss-dsi-bl-demua5-command = [
					/* 0x25C>51hex>=0x196 */
					39 00 00 50 00 00 06 F0 55 AA 52 08 04
					39 00 00 50 00 00 02 6F 02
					39 00 00 50 00 00 03 EC 15 2D
					39 00 00 50 00 00 02 6F A5
					39 00 00 10 00 00 07 EC 15 15 15 2D 2D 2D
				];
				qcom,mdss-dsi-bl-demua6-command = [
					/* 0x196>51hex>=0x008 */
					39 00 00 50 00 00 06 F0 55 AA 52 08 04
					39 00 00 50 00 00 02 6F 02
					39 00 00 50 00 00 03 EC 15 4D
					39 00 00 50 00 00 02 6F A5
					39 00 00 10 00 00 07 EC 15 15 15 4D 4D 4D
				];
				qcom,mdss-dsi-skipframe-dbv-command = [
					39 00 00 40 00 00 06 F0 55 AA 52 08 01
					39 00 00 40 00 00 02 6F 02
					39 00 00 40 00 00 11 E5 00 00 00 00 00 00 00 00 00 00 00 00 00 00 00 00
					39 00 00 40 00 00 02 6F 24
					39 00 00 40 00 00 0D E5 00 00 00 00 00 00 00 00 00 00 00 00
					39 00 00 40 00 00 02 6F 46
					39 00 00 40 00 00 0D E5 00 00 00 00 00 00 00 00 00 00 00 00
					39 00 00 40 00 00 02 6F 03
					39 00 00 40 00 00 19 C6 1B 1B 24 23 23 23 23 23 23 1D 1D 25 23 23 23 23 23 23 1B 1B 24 23 23 23
					39 00 00 40 00 00 02 E5 B2
					39 00 00 40 00 00 02 6F 22
					39 00 00 40 00 00 02 E5 B2
					39 00 00 40 00 00 02 6F 44
					39 00 00 40 00 00 02 E5 B2
					39 00 00 40 00 00 06 F0 55 AA 52 08 05
					39 00 00 40 00 00 02 6F 12
					39 00 00 00 00 00 05 EC 00 00 00 00
					];
				qcom,mdss-dsi-timing-switch-command = [
					/* switch */
					39 00 00 40 00 00 06 F0 55 AA 52 08 00
					39 00 00 00 0C 00 02 2F 00
					39 00 00 40 00 00 02 BE 5F
					39 00 00 40 00 00 02 6F A8
					39 00 00 40 00 00 03 BA 00 00
					39 00 00 40 00 00 02 6F B0
					39 00 00 40 00 00 05 BA 00 00 00 00
					39 00 00 40 00 00 02 2F 30
					39 00 00 40 00 00 02 6D 00
					39 00 00 00 00 00 05 35 00 00 00 00
					];
				qcom,mdss-dsi-on-command=[
					/* Optimize edge green */
					39 00 00 40 00 00 06 F0 55 AA 52 08 07
					39 00 00 40 00 00 0E B4 C0 80 80 80 80 50 80 80 80 80 80 50 80
					/* Vsync Hsync output */
					39 00 00 40 00 00 06 F0 55 AA 52 08 00
					39 00 00 40 00 00 02 6F 02
					39 00 00 00 00 00 03 BE 49 4C
					/* AVDD=7.9 */
					39 00 00 40 00 00 06 F0 55 AA 52 08 00
					39 00 00 40 00 00 02 6F 07
					39 00 00 40 00 00 02 B5 4E
					/* HBM L0 glows green */
					39 00 00 40 00 00 02 B5 80
					39 00 00 40 00 00 02 6F 2C
					39 00 00 00 00 00 02 B5 03
					39 00 00 40 00 00 05 FF AA 55 A5 81
					39 00 00 40 00 00 02 6F 19
					39 00 00 40 00 00 02 FB 00
					39 00 00 40 00 00 02 6F 05
					39 00 00 40 00 00 02 FE 34
					39 00 00 40 00 00 05 FF AA 55 A5 80
					39 00 00 40 00 00 02 6F 1A
					39 00 00 40 00 00 02 F4 55
					39 00 00 40 00 00 05 FF AA 55 A5 83
					39 00 00 40 00 00 02 6F 12
					39 00 00 40 00 00 02 FE 41
					39 00 00 40 00 00 02 5F 00
					39 00 00 40 00 00 02 26 00
					39 00 00 40 00 00 02 26 00
					39 00 00 40 00 00 02 17 10
					39 00 00 40 00 00 05 2A 00 00 04 D7
					39 00 00 00 00 00 05 2B 00 00 0A D3
					/* Fre 120Hz */
					39 00 00 00 00 00 02 2F 00
					/* TE ON */
					39 00 00 40 00 00 02 35 00
					39 00 00 00 00 00 03 44 00 00
					/* Nor 51 */
					39 00 00 40 00 00 03 51 00 00
					39 00 00 00 00 00 02 6F 04
					/* AOD 51 */
					39 00 00 40 00 00 03 51 00 00
					39 00 00 40 00 00 02 53 20
					39 00 00 00 00 00 03 90 03 03
					/* 10bit DSC */
					39 00 00 40 00 00 13 91 AB 28 00 0C F2 00 02 85 01 0F 00 08 0A E9 07 5F 10 F0
					39 00 00 40 00 00 05 FF AA 55 A5 81
					39 00 00 40 00 00 02 6F 24
					39 00 00 40 00 00 15 FB 00 03 04 55 77 77 77 99 9D 00 00 06 88 9A BB BC DE EF F0 11
					39 00 00 40 00 00 05 FF AA 55 A5 81
					39 00 00 40 00 00 02 6F 0E
					39 00 00 40 00 00 02 F5 00
					39 00 00 40 00 00 05 FF AA 55 A5 80
					39 00 00 40 00 00 02 6F 0F
					39 00 00 40 00 00 02 FC 00
					39 00 00 40 00 00 02 6F 09
					39 00 00 40 00 00 03 FC FC F0
					39 00 00 40 00 00 05 FF AA 55 A5 80
					39 00 00 40 00 00 02 6F 0A
					39 00 00 40 00 00 04 F6 70 70 70
					39 00 00 40 00 00 02 6F 0E
					39 00 00 00 00 00 02 F6 60
					/* OSC start */
					39 00 00 40 00 00 05 FF AA 55 A5 80
					39 00 00 40 00 00 02 6F 11
					/* OSC2 145Mhz */
					39 00 00 40 00 00 03 F8 01 8E
					39 00 00 40 00 00 02 6F 2D
					/* OSC1 121.9Mhz */
					39 00 00 40 00 00 03 F8 00 FC
					39 00 00 40 00 00 02 6F 01
					39 00 00 40 00 00 02 1F 06
					39 00 00 40 00 00 05 FF AA 55 A5 81
					39 00 00 40 00 00 02 6F 1E
					39 00 00 00 00 00 02 FB 0F
					/* OSC end */
					39 00 00 40 00 00 05 FF AA 55 A5 83
					39 00 00 40 00 00 02 6F 12
					39 00 00 40 00 00 02 FE 41
					39 00 00 40 00 00 05 FF AA 55 A5 80
					39 00 00 40 00 00 02 6F 19
					39 00 00 40 00 00 02 F2 00
					39 00 00 40 00 00 05 FF AA 55 A5 81
					39 00 00 40 00 00 02 6F 02
					39 00 00 40 00 00 02 F9 04
					39 00 00 40 00 00 02 5A 00
					/* AOD remove black frame */
					39 00 00 00 00 00 06 F0 55 AA 52 08 01
					39 00 00 00 00 00 06 D2 00 00 00 00 15
					15 00 00 00 00 00 02 6F 05
					39 00 00 00 00 00 04 D2 01 00 00
					15 00 00 00 00 00 02 6F 0E
					39 00 00 00 00 00 06 D2 02 00 10 05 88
					39 00 00 00 00 00 0B E4 80 00 00 00 00 00 00 00 00 33
					15 00 00 00 00 00 02 6F 0A
					39 00 00 00 00 00 07 E4 80 00 00 10 00 53
					/* AOD off splash */
					39 00 00 40 00 00 06 F0 55 AA 52 08 01
					39 00 00 40 00 00 02 6F 0E
					39 00 00 00 00 00 06 D2 02 00 10 05 82
					/* OSC Tracking */
					39 00 00 40 00 00 06 F0 55 AA 52 08 01
					39 00 00 00 00 00 2A C3 DD 06 22 15 F9 00 06 20 15 FF 00 03 E7 16 06 2B 1D 03 E7 16 06 2B 1D 03 E7 16 06 2B 1D 03 E7 16 06 2B 1D 03 E7 16 06 2B 1D
					/* 11H sleep out */
					39 00 00 00 78 00 02 11 00
					39 00 00 40 00 00 06 F0 55 AA 52 08 00
					39 00 00 00 09 00 02 2F 00
					39 00 00 40 00 00 02 BE 5F
					39 00 00 40 00 00 02 6F A8
					39 00 00 40 00 00 03 BA 00 00
					39 00 00 40 00 00 02 6F B0
					39 00 00 40 00 00 05 BA 00 00 00 00
					39 00 00 40 00 00 02 2F 30
					39 00 00 40 00 00 02 6D 00
					39 00 00 00 00 00 05 35 00 00 00 00
					05 00 00 00 00 00 01 29
				];

				qcom,mdss-dsi-panel-info-switch-page-command = [
					/*read panel info switch page 01*/
					39 00 00 00 00 00 06 F0 55 AA 52 08 01
				];
				qcom,mdss-dsi-default-switch-page-command = [
					/*switch default page*/
					39 00 00 00 00 00 06 F0 55 AA 52 08 00
				];

				qcom,mdss-dsi-qsync-off-commands = [
					15 00 00 40 00 00 02 2F 00
					15 00 00 40 00 00 02 2F 30
					15 00 00 00 00 00 02 6D 00
				];
				qcom,mdss-dsi-adfr-min-fps-0-command = [
					15 00 00 40 00 00 02 2F 00
					15 00 00 40 00 00 02 2F 30
					15 00 00 00 00 00 02 6D 00
				];
				qcom,mdss-dsi-adfr-min-fps-1-command = [
					15 00 00 40 00 00 02 2F 00
					15 00 00 40 00 00 02 2F 30
					15 00 00 00 00 00 02 6D 01
				];

				qcom,mdss-dsi-post-on-backlight = [
					/* Display On */
					05 00 00 00 00 00 01 29
				];
				qcom,mdss-dsi-off-command=[
					05 00 00 00 0A 00 01 28
					05 00 00 00 78 00 01 10
				];
				qcom,mdss-dsi-lp1-command = [
					/* AOD Mode ON Setting */
					39 00 00 00 00 00 06 F0 55 AA 52 08 00
					15 00 00 00 00 00 02 6F 0C
					39 00 00 00 00 00 03 B5 50 4B
					39 00 00 00 00 00 05 35 00 00 00 00
					39 00 00 00 00 00 03 44 00 00
					15 00 00 00 10 00 02 2F 00
					05 00 00 00 00 00 01 39
					15 00 00 00 00 00 02 65 01
					15 00 00 00 00 00 02 6F 04
					39 00 00 00 00 00 03 51 02 FF
				];
				qcom,mdss-dsi-nolp-command = [
					/* AOD OFF */
					39 00 00 00 00 00 06 F0 55 AA 52 08 00
					15 00 00 00 00 00 02 6F 0C
					39 00 00 00 00 00 03 B5 4F 4B
					15 00 00 00 00 00 02 65 00
					05 00 00 00 00 00 01 38
					15 00 00 00 00 00 02 2F 30
					15 00 00 00 00 00 02 6D 00
					39 00 00 00 00 00 05 35 00 00 00 00
					39 00 00 00 00 00 03 44 00 00
					39 00 00 00 28 00 03 51 00 00
				];
				qcom,mdss-dsi-hbm-off-command = [
					//39 00 00 00 00 00 03 51 0D BB
				];
				qcom,mdss-dsi-hbm-on-command = [
					39 00 00 40 00 00 06 F0 55 AA 52 08 01
					39 00 00 40 00 00 02 6F 02
					39 00 00 40 00 00 11 E5 00 00 00 00 20 20 20 00 28 28 28 00 30 30 30 00
					39 00 00 40 00 00 02 6F 24
					39 00 00 40 00 00 0D E5 00 00 00 00 20 20 20 00 28 28 28 00
					39 00 00 40 00 00 02 6F 46
					39 00 00 40 00 00 0D E5 00 00 00 00 20 20 20 00 28 28 28 00
					39 00 00 40 00 00 02 6F 03
					39 00 00 40 00 00 19 C6 37 37 37 23 23 23 23 23 23 37 37 37 23 23 23 23 23 23 37 37 37 23 23 23
					39 00 00 40 00 00 02 E5 B2
					39 00 00 40 00 00 02 6F 22
					39 00 00 40 00 00 02 E5 B2
					39 00 00 40 00 00 02 6F 44
					39 00 00 40 00 00 02 E5 B2
					39 00 00 40 00 00 06 F0 55 AA 52 08 05
					39 00 00 40 00 00 02 6F 12
					39 00 00 40 00 00 05 EC 00 00 00 00
					39 00 00 40 00 00 06 F0 55 AA 52 08 00
					39 00 00 40 00 00 02 6F 11
					39 00 00 40 00 00 04 B2 02 03 42
					39 00 00 40 00 00 2D B3 00 08 00 B4 00 B4 01 5F 01 5F 02 20 02 20 03 7C 03 7C 05 30 05 30 06 43 06 43 06 44 06 44 09 0B 09 0B 0D BB 0D BB 0F FF 0F FF 0F FF
					39 00 00 40 00 00 2F B4 00 00 00 80 00 96 00 96 00 C0 00 C0 01 26 01 26 02 8E 02 8E 05 8E 05 8E 08 26 08 26 09 40 09 40 09 40 09 40 09 40 09 40 09 40 09 40 09 40
					39 00 00 40 00 00 02 6F 2E
					39 00 00 40 00 00 2F B4 00 00 00 E2 00 FF 00 FF 01 3A 01 3A 01 CE 01 CE 03 AA 03 AA 07 9C 07 9C 0B 20 0B 20 0C 56 0C 56 0C 56 0C 56 0C 56 0C 56 0C 56 0C 56 0C 56
					39 00 00 40 00 00 02 6F 5C
					39 00 00 40 00 00 2F B4 00 00 00 78 00 8C 00 8C 00 B4 00 B4 01 26 01 26 02 8E 02 8E 05 8E 05 8E 08 26 08 26 09 40 09 40 09 40 09 40 09 40 09 40 09 40 09 40 09 40
					39 00 00 00 00 00 03 51 0F 00
				];
				qcom,mdss-dsi-hbm-on-onepulse-command = [
					39 00 00 40 00 00 06 F0 55 AA 52 08 01
					39 00 00 40 00 00 02 6F 02
					39 00 00 40 00 00 11 E5 00 00 00 00 00 00 00 00 00 00 00 00 00 00 00 00
					39 00 00 40 00 00 02 6F 24
					39 00 00 40 00 00 0D E5 00 00 00 00 20 20 20 00 28 28 28 00
					39 00 00 40 00 00 02 6F 46
					39 00 00 40 00 00 0D E5 00 00 00 00 20 20 20 00 28 28 28 00
					39 00 00 40 00 00 02 6F 03
					39 00 00 40 00 00 19 C6 1D 1D 1D 23 23 23 23 23 23 37 37 37 23 23 23 23 23 23 37 37 37 23 23 23
					39 00 00 40 00 00 02 E5 B2
					39 00 00 40 00 00 02 6F 22
					39 00 00 40 00 00 02 E5 B2
					39 00 00 40 00 00 02 6F 44
					39 00 00 40 00 00 02 E5 B2
					39 00 00 40 00 00 06 F0 55 AA 52 08 05
					39 00 00 40 00 00 02 6F 12
					39 00 00 40 00 00 05 EC 00 00 00 00
					39 00 00 40 00 00 06 F0 55 AA 52 08 00
					39 00 00 40 00 00 02 6F 11
					39 00 00 40 00 00 04 B2 00 00 40
					39 00 00 40 00 00 2D B3 00 08 00 B4 00 B4 01 5F 01 5F 02 20 02 20 03 7C 03 7C 05 30 05 30 06 43 06 43 06 44 06 44 09 0B 09 0B 0D BB 0D BB 0F FF 0F FF 0F FF
					39 00 00 40 00 00 2F B4 00 00 00 80 00 96 00 96 00 C0 00 C0 01 26 01 26 02 8E 02 8E 05 8E 05 8E 08 26 08 26 0A DE 0A DE 0A DE 0A DE 0A DE 0A DE 0A DE 0A DE 0A DE
					39 00 00 40 00 00 02 6F 2E
					39 00 00 40 00 00 2F B4 00 00 00 E2 00 FF 00 FF 01 3A 01 3A 01 CE 01 CE 03 AA 03 AA 07 9C 07 9C 0B 20 0B 20 0E 5B 0E 5B 0E 5B 0E 5B 0E 5B 0E 5B 0E 5B 0E 5B 0E 5B
					39 00 00 40 00 00 02 6F 5C
					39 00 00 40 00 00 2F B4 00 00 00 78 00 8C 00 8C 00 B4 00 B4 01 26 01 26 02 8E 02 8E 05 8E 05 8E 08 26 08 26 0A DE 0A DE 0A DE 0A DE 0A DE 0A DE 0A DE 0A DE 0A DE
					39 00 00 00 00 00 03 51 0F 00
				];
				qcom,mdss-dsi-aod-high-mode-command = [
					/* AOD 50nit */
					15 00 00 40 00 00 02 6F 04
					39 00 00 00 00 00 03 51 02 FF
				];
				qcom,mdss-dsi-aod-low-mode-command = [
					/* AOD 10nit */
					15 00 00 40 00 00 02 6F 04
					39 00 00 00 00 00 03 51 01 FF
				];
				qcom,mdss-dsi-temperature-compensation-command = [
					39 00 00 40 00 00 06 F0 55 AA 52 08 01
					39 00 00 40 00 00 02 6F 06
					39 00 00 40 00 00 05 E5 00 00 00 00
					39 00 00 40 00 00 02 6F 0A
					39 00 00 40 00 00 05 E5 00 00 00 00
					39 00 00 40 00 00 02 6F 0E
					39 00 00 40 00 00 05 E5 00 00 00 00
					39 00 00 40 00 00 02 6F 28
					39 00 00 40 00 00 05 E5 00 00 00 00
					39 00 00 40 00 00 02 6F 2C
					39 00 00 40 00 00 05 E5 00 00 00 00
					39 00 00 40 00 00 02 6F 4A
					39 00 00 40 00 00 05 E5 00 00 00 00
					39 00 00 40 00 00 02 6F 4E
					39 00 00 40 00 00 05 E5 00 00 00 00
					39 00 00 40 00 00 02 6F 52
					39 00 00 40 00 00 05 E5 00 00 00 00
					39 00 00 40 00 00 02 6F 03
					39 00 00 40 00 00 04 C6 00 00 00
					39 00 00 40 00 00 02 6F 0C
					39 00 00 40 00 00 04 C6 00 00 00
					39 00 00 40 00 00 02 6F 15
					39 00 00 40 00 00 04 C6 00 00 00
					39 00 00 40 00 00 06 F0 55 AA 52 08 05
					39 00 00 40 00 00 02 6F 12
					39 00 00 00 00 00 05 EC 00 00 00 00
				];
				/* origin 3 pulse */
				qcom,mdss-dsi-pwm-switch-high-command = [
					39 00 00 40 00 00 06 F0 55 AA 52 08 00
					39 00 00 40 00 00 02 6F 11
					39 00 00 40 00 00 04 B2 02 03 42
					39 00 00 40 00 00 2D B3 00 08 00 B4 00 B4 01 5F 01 5F 02 20 02 20 03 7C 03 7C 05 30 05 30 06 43 06 43 06 44 06 44 09 0B 09 0B 0D BB 0D BB 0F FF 0F FF 0F FF
					39 00 00 40 00 00 2F B4 00 00 00 80 00 96 00 96 00 C0 00 C0 01 26 01 26 02 8E 02 8E 05 8E 05 8E 08 26 08 26 09 40 09 40 09 40 09 40 09 40 09 40 09 40 09 40 09 40
					39 00 00 40 00 00 02 6F 2E
					39 00 00 40 00 00 2F B4 00 00 00 E2 00 FF 00 FF 01 3A 01 3A 01 CE 01 CE 03 AA 03 AA 07 9C 07 9C 0B 20 0B 20 0C 56 0C 56 0C 56 0C 56 0C 56 0C 56 0C 56 0C 56 0C 56
					39 00 00 40 00 00 02 6F 5C
					39 00 00 40 00 00 2F B4 00 00 00 78 00 8C 00 8C 00 B4 00 B4 01 26 01 26 02 8E 02 8E 05 8E 05 8E 08 26 08 26 09 40 09 40 09 40 09 40 09 40 09 40 09 40 09 40 09 40
					39 00 00 00 00 00 03 51 06 44
				];
				qcom,mdss-dsi-pwm-switch-low-command = [
					39 00 00 40 00 00 06 F0 55 AA 52 08 00
					39 00 00 40 00 00 02 6F 11
					39 00 00 40 00 00 04 B2 0F 17 4E
					39 00 00 40 00 00 2D B3 00 08 00 B4 00 B4 01 5F 01 5F 02 20 02 20 03 7C 03 7C 05 30 05 30 06 43 06 43 06 44 06 44 09 0B 09 0B 0D BB 0D BB 0F FF 0F FF 0F FF
					39 00 00 40 00 00 2F B4 00 00 00 80 00 96 00 96 00 C0 00 C0 01 26 01 26 02 8E 02 8E 05 8E 05 8E 08 26 08 26 09 40 09 40 09 40 09 40 09 40 09 40 09 40 09 40 09 40
					39 00 00 40 00 00 02 6F 2E
					39 00 00 40 00 00 2F B4 00 00 00 E2 00 FF 00 FF 01 3A 01 3A 01 CE 01 CE 03 AA 03 AA 07 9C 07 9C 0B 20 0B 20 0C 56 0C 56 0C 56 0C 56 0C 56 0C 56 0C 56 0C 56 0C 56
					39 00 00 40 00 00 02 6F 5C
					39 00 00 40 00 00 2F B4 00 00 00 78 00 8C 00 8C 00 B4 00 B4 01 26 01 26 02 8E 02 8E 05 8E 05 8E 08 26 08 26 09 40 09 40 09 40 09 40 09 40 09 40 09 40 09 40 09 40
					39 00 00 00 00 00 03 51 06 43
				];
				/* origin 3 pulse */
				qcom,mdss-dsi-timming-pwm-switch-high-command = [
					39 00 00 40 00 00 06 F0 55 AA 52 08 00
					39 00 00 40 00 00 02 6F 11
					39 00 00 40 00 00 04 B2 02 03 42
					39 00 00 40 00 00 2D B3 00 08 00 B4 00 B4 01 5F 01 5F 02 20 02 20 03 7C 03 7C 05 30 05 30 06 43 06 43 06 44 06 44 09 0B 09 0B 0D BB 0D BB 0F FF 0F FF 0F FF
					39 00 00 40 00 00 2F B4 00 00 00 80 00 96 00 96 00 C0 00 C0 01 26 01 26 02 8E 02 8E 05 8E 05 8E 08 26 08 26 09 40 09 40 09 40 09 40 09 40 09 40 09 40 09 40 09 40
					39 00 00 40 00 00 02 6F 2E
					39 00 00 40 00 00 2F B4 00 00 00 E2 00 FF 00 FF 01 3A 01 3A 01 CE 01 CE 03 AA 03 AA 07 9C 07 9C 0B 20 0B 20 0C 56 0C 56 0C 56 0C 56 0C 56 0C 56 0C 56 0C 56 0C 56
					39 00 00 40 00 00 02 6F 5C
					39 00 00 00 00 00 2F B4 00 00 00 78 00 8C 00 8C 00 B4 00 B4 01 26 01 26 02 8E 02 8E 05 8E 05 8E 08 26 08 26 09 40 09 40 09 40 09 40 09 40 09 40 09 40 09 40 09 40
				];
				qcom,mdss-dsi-timming-pwm-switch-low-command = [
					39 00 00 40 00 00 06 F0 55 AA 52 08 00
					39 00 00 40 00 00 02 6F 11
					39 00 00 40 00 00 04 B2 0F 17 4E
					39 00 00 40 00 00 2D B3 00 08 00 B4 00 B4 01 5F 01 5F 02 20 02 20 03 7C 03 7C 05 30 05 30 06 43 06 43 06 44 06 44 09 0B 09 0B 0D BB 0D BB 0F FF 0F FF 0F FF
					39 00 00 40 00 00 2F B4 00 00 00 80 00 96 00 96 00 C0 00 C0 01 26 01 26 02 8E 02 8E 05 8E 05 8E 08 26 08 26 09 40 09 40 09 40 09 40 09 40 09 40 09 40 09 40 09 40
					39 00 00 40 00 00 02 6F 2E
					39 00 00 40 00 00 2F B4 00 00 00 E2 00 FF 00 FF 01 3A 01 3A 01 CE 01 CE 03 AA 03 AA 07 9C 07 9C 0B 20 0B 20 0C 56 0C 56 0C 56 0C 56 0C 56 0C 56 0C 56 0C 56 0C 56
					39 00 00 40 00 00 02 6F 5C
					39 00 00 00 00 00 2F B4 00 00 00 78 00 8C 00 8C 00 B4 00 B4 01 26 01 26 02 8E 02 8E 05 8E 05 8E 08 26 08 26 09 40 09 40 09 40 09 40 09 40 09 40 09 40 09 40 09 40
				];
				qcom,mdss-dsi-pwm-switch-onepulse-command = [
					39 00 00 40 00 00 06 F0 55 AA 52 08 00
					39 00 00 40 00 00 02 6F 11
					39 00 00 40 00 00 04 B2 00 00 40
					39 00 00 40 00 00 2D B3 00 08 00 B4 00 B4 01 5F 01 5F 02 20 02 20 03 7C 03 7C 05 30 05 30 06 43 06 43 06 44 06 44 09 0B 09 0B 0D BB 0D BB 0F FF 0F FF 0F FF
					39 00 00 40 00 00 2F B4 00 00 00 80 00 96 00 96 00 C0 00 C0 01 26 01 26 02 8E 02 8E 05 8E 05 8E 08 26 08 26 0A DE 0A DE 0A DE 0A DE 0A DE 0A DE 0A DE 0A DE 0A DE
					39 00 00 40 00 00 02 6F 2E
					39 00 00 40 00 00 2F B4 00 00 00 E2 00 FF 00 FF 01 3A 01 3A 01 CE 01 CE 03 AA 03 AA 07 9C 07 9C 0B 20 0B 20 0E 5B 0E 5B 0E 5B 0E 5B 0E 5B 0E 5B 0E 5B 0E 5B 0E 5B
					39 00 00 40 00 00 02 6F 5C
					39 00 00 40 00 00 2F B4 00 00 00 78 00 8C 00 8C 00 B4 00 B4 01 26 01 26 02 8E 02 8E 05 8E 05 8E 08 26 08 26 0A DE 0A DE 0A DE 0A DE 0A DE 0A DE 0A DE 0A DE 0A DE
					39 00 00 00 00 00 03 51 06 44
				];
				qcom,mdss-dsi-timming-pwm-switch-onepulse-command = [
					39 00 00 40 00 00 06 F0 55 AA 52 08 00
					39 00 00 40 00 00 02 6F 11
					39 00 00 40 00 00 04 B2 00 00 40
					39 00 00 40 00 00 2D B3 00 08 00 B4 00 B4 01 5F 01 5F 02 20 02 20 03 7C 03 7C 05 30 05 30 06 43 06 43 06 44 06 44 09 0B 09 0B 0D BB 0D BB 0F FF 0F FF 0F FF
					39 00 00 40 00 00 2F B4 00 00 00 80 00 96 00 96 00 C0 00 C0 01 26 01 26 02 8E 02 8E 05 8E 05 8E 08 26 08 26 0A DE 0A DE 0A DE 0A DE 0A DE 0A DE 0A DE 0A DE 0A DE
					39 00 00 40 00 00 02 6F 2E
					39 00 00 40 00 00 2F B4 00 00 00 E2 00 FF 00 FF 01 3A 01 3A 01 CE 01 CE 03 AA 03 AA 07 9C 07 9C 0B 20 0B 20 0E 5B 0E 5B 0E 5B 0E 5B 0E 5B 0E 5B 0E 5B 0E 5B 0E 5B
					39 00 00 40 00 00 02 6F 5C
					39 00 00 00 00 00 2F B4 00 00 00 78 00 8C 00 8C 00 B4 00 B4 01 26 01 26 02 8E 02 8E 05 8E 05 8E 08 26 08 26 0A DE 0A DE 0A DE 0A DE 0A DE 0A DE 0A DE 0A DE 0A DE
				];
				qcom,mdss-dsi-pwm-switch-threepulse-command = [
					39 00 00 40 00 00 06 F0 55 AA 52 08 00
					39 00 00 40 00 00 02 6F 11
					39 00 00 40 00 00 04 B2 02 03 42
					39 00 00 40 00 00 2D B3 00 08 00 B4 00 B4 01 5F 01 5F 02 20 02 20 03 7C 03 7C 05 30 05 30 06 43 06 43 06 44 06 44 09 0B 09 0B 0D BB 0D BB 0F FF 0F FF 0F FF
					39 00 00 40 00 00 2F B4 00 00 00 80 00 96 00 96 00 C0 00 C0 01 26 01 26 02 8E 02 8E 05 8E 05 8E 08 26 08 26 09 40 09 40 09 40 09 40 09 40 09 40 09 40 09 40 09 40
					39 00 00 40 00 00 02 6F 2E
					39 00 00 40 00 00 2F B4 00 00 00 E2 00 FF 00 FF 01 3A 01 3A 01 CE 01 CE 03 AA 03 AA 07 9C 07 9C 0B 20 0B 20 0C 56 0C 56 0C 56 0C 56 0C 56 0C 56 0C 56 0C 56 0C 56
					39 00 00 40 00 00 02 6F 5C
					39 00 00 00 00 00 2F B4 00 00 00 78 00 8C 00 8C 00 B4 00 B4 01 26 01 26 02 8E 02 8E 05 8E 05 8E 08 26 08 26 09 40 09 40 09 40 09 40 09 40 09 40 09 40 09 40 09 40
				];
				qcom,mdss-dsi-aod-hbm-on-command-state = "dsi_hs_mode";
				qcom,mdss-dsi-aod-hbm-off-command-state = "dsi_hs_mode";
				qcom,mdss-dsi-timing-switch-command-state = "dsi_hs_mode";
				qcom,mdss-dsi-on-command-state = "dsi_lp_mode";
				qcom,mdss-dsi-off-command-state = "dsi_hs_mode";
				qcom,mdss-dsi-hbm-on-command-state = "dsi_hs_mode";
				qcom,mdss-dsi-hbm-on-onepulse-command-state = "dsi_hs_mode";
				qcom,mdss-dsi-hbm-off-command-state = "dsi_hs_mode";
				qcom,mdss-dsi-skipframe-dbv-command-state = "dsi_hs_mode";
				qcom,mdss-dsi-adfr-min-fps-0-command-state = "dsi_hs_mode";
				qcom,mdss-dsi-adfr-min-fps-1-command-state = "dsi_hs_mode";
				qcom,mdss-dsi-bl-demua1-command-state = "dsi_hs_mode";
				qcom,mdss-dsi-bl-demua2-command-state = "dsi_hs_mode";
				qcom,mdss-dsi-bl-demua3-command-state = "dsi_hs_mode";
				qcom,mdss-dsi-bl-demua4-command-state = "dsi_hs_mode";
				qcom,mdss-dsi-bl-demua5-command-state = "dsi_hs_mode";
				qcom,mdss-dsi-bl-demua6-command-state = "dsi_hs_mode";
				qcom,mdss-dsi-panel-info-switch-page-command-state = "dsi_lp_mode";
				qcom,mdss-dsi-default-switch-page-command-state = "dsi_lp_mode";
				qcom,mdss-dsi-pwm-switch-high-command-state = "dsi_hs_mode";
				qcom,mdss-dsi-pwm-switch-low-command-state = "dsi_hs_mode";
				qcom,mdss-dsi-timming-pwm-switch-high-command-state = "dsi_hs_mode";
				qcom,mdss-dsi-timming-pwm-switch-low-command-state = "dsi_hs_mode";
				qcom,mdss-dsi-pwm-switch-onepulse-command-state = "dsi_hs_mode";
				qcom,mdss-dsi-timming-pwm-switch-onepulse-command-state = "dsi_hs_mode";
				qcom,mdss-dsi-pwm-switch-threepulse-command-state = "dsi_hs_mode";

				qcom,lm-split = <620 620>;
				qcom,compression-mode = "dsc";
				qcom,mdss-dsc-encoders = <2>;
				qcom,mdss-dsc-slice-height = <12>;
				qcom,mdss-dsc-slice-width = <620>;
				qcom,mdss-dsc-slice-per-pkt = <2>;
				qcom,mdss-dsc-bit-per-component = <10>;
				qcom,mdss-dsc-bit-per-pixel = <8>;
				qcom,mdss-dsc-block-prediction-enable;
			};
		};
	};
};

&soc {
	dsi_oplus_zonda_tianma_nt37705_1240_2772_dsc_cmd {
		qcom,dsi-display-active;
	};
};

&dsi_oplus_zonda_tianma_nt37705_1240_2772_dsc_cmd {
	qcom,panel-supply-entries = <&oplus_zonda_dsi_panel_pwr_supply>;
	qcom,mdss-dsi-panel-controller = <&mdss_dsi0>;
	qcom,mdss-dsi-bl-pmic-control-type = "bl_ctrl_dcs";
	qcom,bl-update-flag = "delay_until_first_frame";
	qcom,mdss-dsi-bl-min-level = <1>;
	qcom,mdss-dsi-bl-max-level = <4095>;
	qcom,mdss-brightness-max-level = <4095>;
	oplus,dsi-bl-normal-max-level = <3515>;
	oplus,dsi-brightness-normal-max-level = <3515>;

	oplus,dsi-brightness-default-level = <1638>;
	qcom,mdss-dsi-bl-inverted-dbv;
	qcom,platform-te-gpio = <&tlmm 86 0>;
	oplus,adfr-test-te-gpio = <&tlmm 177 0>;
	qcom,platform-reset-gpio = <&tlmm 3 0>;
	qcom,platform-panel-vout-gpio = <&tlmm 90 0>;

	qcom,ulps-enabled;
	qcom,dsi-select-clocks = "pll_byte_clk0", "pll_dsi_clk0";

	/* panel dynamic demua support */
	oplus,dynamic-demua-support;

	/* aod/fod config */
	oplus,ofp-fp-type = <0x08>;
	oplus,ofp-need-to-wait-data-before-aod-on;

/* #ifdef OPLUS_FEATURE_DISPLAY_TEMP_COMPENSATION */
	oplus,temp-compensation-config = <3>;
	oplus,temp-compensation-reg-repeat = <3>; // reg repeat count, max 4, default 4
	oplus,temp-compensation-dbv-group = <3516 1604 1511 1419 1328 1212 1096 950 761 544>;
	oplus,temp-compensation-temp-group = <(0-10) 0 10 20 25 30 35 40 45 51>;
	oplus,temp-compensation-data = [
		/* dbv > 3515 */
		/*  2  3  4  5  6  7  8  9 10 11 12 13 14 15 16 17 18 19 20 21 22 23 24 25 */
		18 1C 20 18 1C 00 00 00 32 32 32 32 32 32 00 00 00 01 A2 F5 20 01 A2 F5 20	/* -20 ~ -10 */
		18 1C 20 18 1C 00 00 00 32 32 32 32 32 32 00 00 00 01 A2 F5 20 01 A2 F5 20	/* -10 ~ 0 */
		18 1C 20 18 1C 00 00 00 32 32 32 32 32 32 00 00 00 01 A2 F5 20 01 A2 F5 20	/* 0 ~ 10 */
		18 1C 20 18 1C 00 00 00 32 32 32 32 32 32 00 00 00 01 A2 F5 20 01 A2 F5 20	/* 10 ~ 20 */
		18 1C 20 18 1C 00 00 00 32 32 32 32 32 32 00 00 00 01 A2 F5 20 01 A2 F5 20	/* 20 ~ 25 */
		18 1C 20 18 1C 00 00 00 32 32 32 32 32 32 00 00 00 01 A2 F5 20 01 A2 F5 20	/* 25 ~ 30 */
		1C 20 24 1C 20 00 00 00 32 32 32 32 32 32 00 00 00 01 A2 F5 20 01 A2 F5 20	/* 30 ~ 35 */
		20 24 28 20 24 00 00 00 30 30 30 30 30 30 00 00 00 01 A2 F5 20 01 A2 F5 20	/* 35 ~ 40 */
		28 2C 30 28 2C 00 00 00 30 30 30 30 30 30 00 00 00 01 A2 F5 20 01 A2 F5 20	/* 40 ~ 45 */
		30 34 38 30 34 00 00 00 30 30 30 30 30 30 00 00 00 01 A2 F5 20 01 A2 F5 20	/* 45 ~ 50 */
		34 38 3C 34 38 00 00 00 30 30 30 30 30 30 00 00 00 01 A2 F5 20 01 A2 F5 20	/* > 50 */

		/* 1604 <= dbv <= 3515 */
		/*  2  3  4  5  6  7  8  9 10 11 12 13 14 15 16 17 18 19 20 21 22 23 24 25 */
		18 1C 20 18 1C 00 00 00 1B 1C 1F 26 27 2A 00 00 00 01 A2 F5 20 01 A2 F5 20	/* -20 ~ -10 */
		18 1C 20 18 1C 00 00 00 1B 1C 1F 26 27 2A 00 00 00 01 A2 F5 20 01 A2 F5 20	/* -10 ~ 0 */
		18 1C 20 18 1C 00 00 00 1B 1C 1F 26 27 2A 00 00 00 01 A2 F5 20 01 A2 F5 20	/* 0 ~ 10 */
		18 1C 20 18 1C 00 00 00 1B 1C 1F 26 27 2A 00 00 00 01 A2 F5 20 01 A2 F5 20	/* 10 ~ 20 */
		18 1C 20 18 1C 00 00 00 1B 1C 1F 26 27 2A 00 00 00 01 A2 F5 20 01 A2 F5 20	/* 20 ~ 25 */
		18 1C 20 18 1C 00 00 00 1B 1C 1F 26 27 2A 00 00 00 01 A2 F5 20 01 A2 F5 20	/* 25 ~ 30 */
		1C 20 24 1C 20 00 00 00 1B 1C 1F 26 27 2A 00 00 00 01 A2 F5 20 01 A2 F5 20	/* 30 ~ 35 */
		20 24 28 20 24 00 00 00 1B 1C 1F 26 27 2A 00 00 00 01 A2 F5 20 01 A2 F5 20	/* 35 ~ 40 */
		28 2C 30 28 2C 00 00 00 1A 1B 1E 25 26 29 00 00 00 01 A2 F5 20 01 A2 F5 20	/* 40 ~ 45 */
		30 34 38 30 34 00 00 00 1A 1B 1E 25 26 29 00 00 00 01 A2 F5 20 01 A2 F5 20	/* 45 ~ 50 */
		34 38 3C 34 38 00 00 00 1A 1B 1E 25 26 29 00 00 00 01 A2 F5 20 01 A2 F5 20	/* > 50 */

		/* 1511 <= dbv < 1604 */
		/*  2  3  4  5  6  7  8  9 10 11 12 13 14 15 16 17 18 19 20 21 22 23 24 25 */
		18 1C 20 18 1C 00 00 00 1B 1C 1F 26 27 2A 00 00 00 01 A2 F5 20 01 A2 F5 20	/* -20 ~ -10 */
		18 1C 20 18 1C 00 00 00 1B 1C 1F 26 27 2A 00 00 00 01 A2 F5 20 01 A2 F5 20	/* -10 ~ 0 */
		18 1C 20 18 1C 00 00 00 1B 1C 1F 26 27 2A 00 00 00 01 A2 F5 20 01 A2 F5 20	/* 0 ~ 10 */
		18 1C 20 18 1C 00 00 00 1B 1C 1F 26 27 2A 00 00 00 01 A2 F5 20 01 A2 F5 20	/* 10 ~ 20 */
		18 1C 20 18 1C 00 00 00 1B 1C 1F 26 27 2A 00 00 00 01 A2 F5 20 01 A2 F5 20	/* 20 ~ 25 */
		18 1C 20 18 1C 00 00 00 1B 1C 1F 26 27 2A 00 00 00 01 A2 F5 20 01 A2 F5 20	/* 25 ~ 30 */
		1C 20 24 1C 20 00 00 00 1B 1C 1F 26 27 2A 00 00 00 01 A2 F5 20 01 A2 F5 20	/* 30 ~ 35 */
		20 24 28 20 24 00 00 00 1B 1C 1F 26 27 2A 00 00 00 01 A2 F5 20 01 A2 F5 20	/* 35 ~ 40 */
		28 2C 30 28 2C 00 00 00 1A 1B 1E 25 26 29 00 00 00 01 A2 F5 20 01 A2 F5 20	/* 40 ~ 45 */
		30 34 38 30 34 00 00 00 1A 1B 1E 25 26 29 00 00 00 01 A2 F5 20 01 A2 F5 20	/* 45 ~ 50 */
		34 38 3C 34 38 00 00 00 1A 1B 1E 25 26 29 00 00 00 01 A2 F5 20 01 A2 F5 20	/* > 50 */

		/* 1419 <= dbv < 1511 */
		/*  2  3  4  5  6  7  8  9 10 11 12 13 14 15 16 17 18 19 20 21 22 23 24 25 */
		18 1C 20 18 1C 00 00 00 1B 1C 1F 26 27 2A 00 00 00 01 A2 F5 20 01 A2 F5 20	/* -20 ~ -10 */
		18 1C 20 18 1C 00 00 00 1B 1C 1F 26 27 2A 00 00 00 01 A2 F5 20 01 A2 F5 20	/* -10 ~ 0 */
		18 1C 20 18 1C 00 00 00 1B 1C 1F 26 27 2A 00 00 00 01 A2 F5 20 01 A2 F5 20	/* 0 ~ 10 */
		18 1C 20 18 1C 00 00 00 1B 1C 1F 26 27 2A 00 00 00 01 A2 F5 20 01 A2 F5 20	/* 10 ~ 20 */
		18 1C 20 18 1C 00 00 00 1B 1C 1F 26 27 2A 00 00 00 01 A2 F5 20 01 A2 F5 20	/* 20 ~ 25 */
		18 1C 20 18 1C 00 00 00 1B 1C 1F 26 27 2A 00 00 00 01 A2 F5 20 01 A2 F5 20	/* 25 ~ 30 */
		1C 20 24 1C 20 00 00 00 1B 1C 1F 26 27 2A 00 00 00 01 A2 F5 20 01 A2 F5 20	/* 30 ~ 35 */
		20 24 28 20 24 00 00 00 1B 1C 1F 26 27 2A 00 00 00 01 A2 F5 20 01 A2 F5 20	/* 35 ~ 40 */
		28 2C 30 28 2C 00 00 00 1A 1B 1E 25 26 29 00 00 00 01 A2 F5 20 01 A2 F5 20	/* 40 ~ 45 */
		30 34 38 30 34 00 00 00 1A 1B 1E 25 26 29 00 00 00 01 A2 F5 20 01 A2 F5 20	/* 45 ~ 50 */
		34 38 3C 34 38 00 00 00 1A 1B 1E 25 26 29 00 00 00 01 A2 F5 20 01 A2 F5 20	/* > 50 */

		/* 1328 <= dbv < 1419 */
		/*  2  3  4  5  6  7  8  9 10 11 12 13 14 15 16 17 18 19 20 21 22 23 24 25 */
		18 1C 20 18 1C 00 00 00 1B 1C 1F 26 27 2A 00 00 00 01 A2 F5 20 01 A2 F5 20	/* -20 ~ -10 */
		18 1C 20 18 1C 00 00 00 1B 1C 1F 26 27 2A 00 00 00 01 A2 F5 20 01 A2 F5 20	/* -10 ~ 0 */
		18 1C 20 18 1C 00 00 00 1B 1C 1F 26 27 2A 00 00 00 01 A2 F5 20 01 A2 F5 20	/* 0 ~ 10 */
		18 1C 20 18 1C 00 00 00 1B 1C 1F 26 27 2A 00 00 00 01 A2 F5 20 01 A2 F5 20	/* 10 ~ 20 */
		18 1C 20 18 1C 00 00 00 1B 1C 1F 26 27 2A 00 00 00 01 A2 F5 20 01 A2 F5 20	/* 20 ~ 25 */
		18 1C 20 18 1C 00 00 00 1B 1C 1F 26 27 2A 00 00 00 01 A2 F5 20 01 A2 F5 20	/* 25 ~ 30 */
		1C 20 24 1C 20 00 00 00 1B 1C 1F 26 27 2A 00 00 00 01 A2 F5 20 01 A2 F5 20	/* 30 ~ 35 */
		20 24 28 20 24 00 00 00 1B 1C 1F 26 27 2A 00 00 00 01 A2 F5 20 01 A2 F5 20	/* 35 ~ 40 */
		28 2C 30 28 2C 00 00 00 1A 1B 1E 25 26 29 00 00 00 01 A2 F5 20 01 A2 F5 20	/* 40 ~ 45 */
		30 34 38 30 34 00 00 00 1A 1B 1E 25 26 29 00 00 00 01 A2 F5 20 01 A2 F5 20	/* 45 ~ 50 */
		34 38 3C 34 38 00 00 00 1A 1B 1E 25 26 29 00 00 00 01 A2 F5 20 01 A2 F5 20	/* > 50 */

		/* 1212 <= dbv < 1328 */
		/*  2  3  4  5  6  7  8  9 10 11 12 13 14 15 16 17 18 19 20 21 22 23 24 25 */
		10 18 1C 10 18 00 00 00 1B 1C 1F 26 27 2A 00 00 00 01 A2 A2 20 01 A2 A2 20	/* -20 ~ -10 */
		10 18 1C 10 18 00 00 00 1B 1C 1F 26 27 2A 00 00 00 01 A2 A2 20 01 A2 A2 20	/* -10 ~ 0 */
		10 18 1C 10 18 00 00 00 1B 1C 1F 26 27 2A 00 00 00 01 A2 A2 20 01 A2 A2 20	/* 0 ~ 10 */
		10 18 1C 10 18 00 00 00 1B 1C 1F 26 27 2A 00 00 00 01 A2 A2 20 01 A2 A2 20	/* 10 ~ 20 */
		10 18 1C 10 18 00 00 00 1B 1C 1F 26 27 2A 00 00 00 01 A2 A2 20 01 A2 A2 20	/* 20 ~ 25 */
		10 18 1C 10 18 00 00 00 1B 1C 1F 26 27 2A 00 00 00 01 A2 A2 20 01 A2 A2 20	/* 25 ~ 30 */
		10 1C 20 10 1C 00 00 00 1B 1C 1F 26 27 2A 00 00 00 01 A2 A2 20 01 A2 A2 20	/* 30 ~ 35 */
		14 20 24 14 20 00 00 00 1B 1C 1F 26 27 2A 00 00 00 01 A2 A2 20 01 A2 A2 20	/* 35 ~ 40 */
		18 28 2C 18 28 00 00 00 1A 1B 1E 25 26 29 00 00 00 01 A2 A2 20 01 A2 A2 20	/* 40 ~ 45 */
		1C 30 34 1C 30 00 00 00 1A 1B 1E 25 26 29 00 00 00 01 A2 A2 20 01 A2 A2 20	/* 45 ~ 50 */
		20 34 38 20 34 00 00 00 1A 1B 1E 25 26 29 00 00 00 01 A2 A2 20 01 A2 A2 20	/* > 50 */

		/* 1096 <= dbv < 1212 */
		/*  2  3  4  5  6  7  8  9 10 11 12 13 14 15 16 17 18 19 20 21 22 23 24 25 */
		10 18 1C 10 18 00 00 00 1B 1C 1F 26 27 2A 00 00 00 01 A2 A2 20 01 A2 A2 20	/* -20 ~ -10 */
		10 18 1C 10 18 00 00 00 1B 1C 1F 26 27 2A 00 00 00 01 A2 A2 20 01 A2 A2 20	/* -10 ~ 0 */
		10 18 1C 10 18 00 00 00 1B 1C 1F 26 27 2A 00 00 00 01 A2 A2 20 01 A2 A2 20	/* 0 ~ 10 */
		10 18 1C 10 18 00 00 00 1B 1C 1F 26 27 2A 00 00 00 01 A2 A2 20 01 A2 A2 20	/* 10 ~ 20 */
		10 18 1C 10 18 00 00 00 1B 1C 1F 26 27 2A 00 00 00 01 A2 A2 20 01 A2 A2 20	/* 20 ~ 25 */
		10 18 1C 10 18 00 00 00 1B 1C 1F 26 27 2A 00 00 00 01 A2 A2 20 01 A2 A2 20	/* 25 ~ 30 */
		10 1C 20 10 1C 00 00 00 1B 1C 1F 26 27 2A 00 00 00 01 A2 A2 20 01 A2 A2 20	/* 30 ~ 35 */
		14 20 24 14 20 00 00 00 1B 1C 1F 26 27 2A 00 00 00 01 A2 A2 20 01 A2 A2 20	/* 35 ~ 40 */
		18 28 2C 18 28 00 00 00 1A 1B 1E 25 26 29 00 00 00 01 A2 A2 20 01 A2 A2 20	/* 40 ~ 45 */
		1C 30 34 1C 30 00 00 00 1A 1B 1E 25 26 29 00 00 00 01 A2 A2 20 01 A2 A2 20	/* 45 ~ 50 */
		20 34 38 20 34 00 00 00 1A 1B 1E 25 26 29 00 00 00 01 A2 A2 20 01 A2 A2 20	/* > 50 */

		/* 950 <= dbv < 1096 */
		/*  2  3  4  5  6  7  8  9 10 11 12 13 14 15 16 17 18 19 20 21 22 23 24 25 */
		10 18 1C 10 18 00 00 00 1B 1C 1F 26 27 2A 00 00 00 01 A2 A2 20 01 A2 A2 20	/* -20 ~ -10 */
		10 18 1C 10 18 00 00 00 1B 1C 1F 26 27 2A 00 00 00 01 A2 A2 20 01 A2 A2 20	/* -10 ~ 0 */
		10 18 1C 10 18 00 00 00 1B 1C 1F 26 27 2A 00 00 00 01 A2 A2 20 01 A2 A2 20	/* 0 ~ 10 */
		10 18 1C 10 18 00 00 00 1B 1C 1F 26 27 2A 00 00 00 01 A2 A2 20 01 A2 A2 20	/* 10 ~ 20 */
		10 18 1C 10 18 00 00 00 1B 1C 1F 26 27 2A 00 00 00 01 A2 A2 20 01 A2 A2 20	/* 20 ~ 25 */
		10 18 1C 10 18 00 00 00 1B 1C 1F 26 27 2A 00 00 00 01 A2 A2 20 01 A2 A2 20	/* 25 ~ 30 */
		10 1C 20 10 1C 00 00 00 1B 1C 1F 26 27 2A 00 00 00 01 A2 A2 20 01 A2 A2 20	/* 30 ~ 35 */
		14 20 24 14 20 00 00 00 1B 1C 1F 26 27 2A 00 00 00 01 A2 A2 20 01 A2 A2 20	/* 35 ~ 40 */
		18 28 2C 18 28 00 00 00 1A 1B 1E 25 26 29 00 00 00 01 A2 A2 20 01 A2 A2 20	/* 40 ~ 45 */
		1C 30 34 1C 30 00 00 00 1A 1B 1E 25 26 29 00 00 00 01 A2 A2 20 01 A2 A2 20	/* 45 ~ 50 */
		20 34 38 20 34 00 00 00 1A 1B 1E 25 26 29 00 00 00 01 A2 A2 20 01 A2 A2 20	/* > 50 */

		/* 761 <= dbv < 950 */
		/*  2  3  4  5  6  7  8  9 10 11 12 13 14 15 16 17 18 19 20 21 22 23 24 25 */
		10 18 1C 10 18 00 00 00 1B 1C 1F 26 27 2A 00 00 00 01 A2 A2 20 01 A2 A2 20	/* -20 ~ -10 */
		10 18 1C 10 18 00 00 00 1B 1C 1F 26 27 2A 00 00 00 01 A2 A2 20 01 A2 A2 20	/* -10 ~ 0 */
		10 18 1C 10 18 00 00 00 1B 1C 1F 26 27 2A 00 00 00 01 A2 A2 20 01 A2 A2 20	/* 0 ~ 10 */
		10 18 1C 10 18 00 00 00 1B 1C 1F 26 27 2A 00 00 00 01 A2 A2 20 01 A2 A2 20	/* 10 ~ 20 */
		10 18 1C 10 18 00 00 00 1B 1C 1F 26 27 2A 00 00 00 01 A2 A2 20 01 A2 A2 20	/* 20 ~ 25 */
		10 18 1C 10 18 00 00 00 1B 1C 1F 26 27 2A 00 00 00 01 A2 A2 20 01 A2 A2 20	/* 25 ~ 30 */
		10 1C 20 10 1C 00 00 00 1B 1C 1F 26 27 2A 00 00 00 01 A2 A2 20 01 A2 A2 20	/* 30 ~ 35 */
		14 20 24 14 20 00 00 00 1B 1C 1F 26 27 2A 00 00 00 01 A2 A2 20 01 A2 A2 20	/* 35 ~ 40 */
		18 28 2C 18 28 00 00 00 1A 1B 1E 25 26 29 00 00 00 01 A2 A2 20 01 A2 A2 20	/* 40 ~ 45 */
		1C 30 34 1C 30 00 00 00 1A 1B 1E 25 26 29 00 00 00 01 A2 A2 20 01 A2 A2 20	/* 45 ~ 50 */
		20 34 38 20 34 00 00 00 1A 1B 1E 25 26 29 00 00 00 01 A2 A2 20 01 A2 A2 20	/* > 50 */

		/* 544 <= dbv < 761 */
		/*  2  3  4  5  6  7  8  9 10 11 12 13 14 15 16 17 18 19 20 21 22 23 24 25 */
		08 0C 10 08 0C 00 00 00 1B 1C 1F 26 27 2A 00 00 00 01 A2 A2 20 01 A2 A2 20	/* -20 ~ -10 */
		08 0C 10 08 0C 00 00 00 1B 1C 1F 26 27 2A 00 00 00 01 A2 A2 20 01 A2 A2 20	/* -10 ~ 0 */
		08 0C 10 08 0C 00 00 00 1B 1C 1F 26 27 2A 00 00 00 01 A2 A2 20 01 A2 A2 20	/* 0 ~ 10 */
		08 0C 10 08 0C 00 00 00 1B 1C 1F 26 27 2A 00 00 00 01 A2 A2 20 01 A2 A2 20	/* 10 ~ 20 */
		08 0C 10 08 0C 00 00 00 1B 1C 1F 26 27 2A 00 00 00 01 A2 A2 20 01 A2 A2 20	/* 20 ~ 25 */
		08 0C 10 08 0C 00 00 00 1B 1C 1F 26 27 2A 00 00 00 01 A2 A2 20 01 A2 A2 20	/* 25 ~ 30 */
		08 0C 10 08 0C 00 00 00 1B 1C 1F 26 27 2A 00 00 00 01 A2 A2 20 01 A2 A2 20	/* 30 ~ 35 */
		08 0C 10 08 0C 00 00 00 1B 1C 1F 26 27 2A 00 00 00 01 A2 A2 20 01 A2 A2 20	/* 35 ~ 40 */
		08 14 18 08 14 00 00 00 1A 1B 1E 25 26 29 00 00 00 01 A2 A2 20 01 A2 A2 20	/* 40 ~ 45 */
		0C 18 1C 0C 18 00 00 00 1A 1B 1E 25 26 29 00 00 00 01 A2 A2 20 01 A2 A2 20	/* 45 ~ 50 */
		10 1C 20 10 1C 00 00 00 1A 1B 1E 25 26 29 00 00 00 01 A2 A2 20 01 A2 A2 20	/* > 50 */

		/* dbv < 544 */
		/*  2  3  4  5  6  7  8  9 10 11 12 13 14 15 16 17 18 19 20 21 22 23 24 25 */
		04 04 08 04 04 00 00 00 1B 1C 1F 26 27 2A 00 00 00 01 A2 A2 20 01 A2 A2 20	/* -20 ~ -10 */
		04 04 08 04 04 00 00 00 1B 1C 1F 26 27 2A 00 00 00 01 A2 A2 20 01 A2 A2 20	/* -10 ~ 0 */
		04 04 08 04 04 00 00 00 1B 1C 1F 26 27 2A 00 00 00 01 A2 A2 20 01 A2 A2 20	/* 0 ~ 10 */
		04 04 08 04 04 00 00 00 1B 1C 1F 26 27 2A 00 00 00 01 A2 A2 20 01 A2 A2 20	/* 10 ~ 20 */
		04 04 08 04 04 00 00 00 1B 1C 1F 26 27 2A 00 00 00 01 A2 A2 20 01 A2 A2 20	/* 20 ~ 25 */
		04 04 08 04 04 00 00 00 1B 1C 1F 26 27 2A 00 00 00 01 A2 A2 20 01 A2 A2 20	/* 25 ~ 30 */
		04 04 08 04 04 00 00 00 1B 1C 1F 26 27 2A 00 00 00 01 A2 A2 20 01 A2 A2 20	/* 30 ~ 35 */
		04 04 08 04 04 00 00 00 1B 1C 1F 26 27 2A 00 00 00 01 A2 A2 20 01 A2 A2 20	/* 35 ~ 40 */
		04 08 0C 04 08 00 00 00 1A 1B 1E 25 26 29 00 00 00 01 A2 A2 20 01 A2 A2 20	/* 40 ~ 45 */
		08 08 0C 08 08 00 00 00 1A 1B 1E 25 26 29 00 00 00 01 A2 A2 20 01 A2 A2 20	/* 45 ~ 50 */
		08 08 0C 08 08 00 00 00 1A 1B 1E 25 26 29 00 00 00 01 A2 A2 20 01 A2 A2 20	/* > 50 */
	];
/* #endif */ /* OPLUS_FEATURE_DISPLAY_TEMP_COMPENSATION */

	/* adfr config */
	/* just for qsync enable*/
	qcom,qsync-enable;
	qcom,mdss-dsi-qsync-min-refresh-rate = <24>;
	/*
	** 0st bit: adfr global on/off
	** 1st bit: fakeframe on/off
	** 2st bit: switch on/off
	** 3rd bit: 0:double-TE switch 1:external TE/TP switch
	** 4rd bit: idle mode on/off
	** 5th bit: temperature compensation mode on/off
	** 6th bit: OA backlight mutual exclusion
	*/
	oplus,adfr-config = <0x61>;  // 0b0110'0001

	qcom,mdss-dsi-display-timings {
		timing@sa_fhd_120 { /* FHD+ 120hz */
			qcom,mdss-dsi-panel-phy-timings = [00 2C 0C 0C 1D 1A 0C 0C 0B 02 04 00 24 11];
			qcom,display-topology = <1 1 1>,<2 2 1>;
			qcom,default-topology-index = <1>;
		};
		timing@sa_fhd_90 { /* FHD+ 90hz */
			qcom,mdss-dsi-panel-phy-timings = [00 2C 0C 0C 1D 1A 0C 0C 0B 02 04 00 24 11];
			qcom,display-topology = <1 1 1>,<2 2 1>;
			qcom,default-topology-index = <1>;
		};
		timing@sa_fhd_60 { /* FHD+ 60hz */
			qcom,mdss-dsi-panel-phy-timings = [00 2C 0C 0C 1D 1A 0C 0C 0B 02 04 00 24 11];
			qcom,display-topology = <1 1 1>,<2 2 1>;
			qcom,default-topology-index = <1>;
		};
		timing@sa_fhd_144 { /* FHD+ 144hz */
			qcom,mdss-dsi-panel-phy-timings = [00 2C 0C 0C 1D 1A 0C 0C 0B 02 04 00 24 11];
			qcom,display-topology = <1 1 1>,<2 2 1>;
			qcom,default-topology-index = <1>;
		};
		timing@oa_fhd_120 { /* FHD+ 120hz */
			qcom,mdss-dsi-panel-phy-timings = [00 2C 0C 0C 1D 1A 0C 0C 0B 02 04 00 24 11];
			qcom,display-topology = <1 1 1>,<2 2 1>;
			qcom,default-topology-index = <1>;
		};
	};
};
&dsi_oplus_zonda_tianma_nt37705_1240_2772_dsc_cmd {
	oplus,color_vivid_status;
	oplus,color_srgb_status;
	oplus,color_softiris_status;
	oplus,color_dual_brightness_status;
	//oplus,color_oplus_calibrate_status;
	//oplus,apollo_backlight_enable;
	//oplus,color_srgb_status;
	oplus,dsi-serial-number-enabled;
	//oplus,dsi-serial-number-lock;
	oplus,dsi-serial-number-switch-page;
	oplus,dsi-serial-number-index= <0>;
	oplus,dsi-serial-number-reg= <0xD7>;
	oplus,dsi-serial-number-read-count= <7>;
	oplus,enhance_mipi_strength;
	oplus,vreg_ctrl_flag;
	oplus,sw_reset_ctrl_flag;
	oplus,disp_hw_seq_modify_flag;
	oplus,gpio-pre-on;
	/*Feature config*/
	oplus,pwm-switch-support;
	oplus,pwm-switch-backlight-threshold = <1603>;
	oplus,pwm-onepulse-support;
	oplus,pwm-onepulse-backlight-threshold = <1603>;
	//oplus,pwm-onepulse-default-enabled;

};
&dsi_oplus_zonda_tianma_nt37705_1240_2772_dsc_cmd {
	qcom,panel_voltage_vddi_name = "vddio";
	qcom,panel_voltage_vddi = <0 1800000 1850000 1950000>;
	qcom,panel_voltage_vddr_name = "vddio";
	qcom,panel_voltage_vddr = <1 1800000 1850000 1950000>;
};

/* #ifdef OPLUS_FEATURE_DISPLAY */
&mdss_dsi_phy0 {
	oplus,dsi-pll-ssc-disalbed;
};

&mdss_dsi_phy1 {
	oplus,dsi-pll-ssc-disalbed;
};
/* OPLUS_FEATURE_DISPLAY */
